VERSION ""

NS_ :

BS_:

BU_:
	NEO
	MCU
	GTW
	EPAS
	DI
	ESP
	SBW
	STW
	APP
	DAS
	iBooster
	IVS
	XXX

VAL_TABLE_ StW_AnglHP_Spd 16383 "SNA" ;
VAL_TABLE_ DI_aebFaultReason 15 "DI_AEB_FAULT_DAS_REQ_DI_UNAVAIL" 14 "DI_AEB_FAULT_ACCEL_REQ_INVALID" 13 "DI_AEB_FAULT_MIN_TIME_BTWN_EVENTS" 12 "DI_AEB_FAULT_ESP_MIA" 11 "DI_AEB_FAULT_ESP_FAULT" 10 "DI_AEB_FAULT_EPB_NOT_PARKED" 9 "DI_AEB_FAULT_ACCEL_OUT_OF_BOUNDS" 8 "DI_AEB_FAULT_PM_REQUEST" 7 "DI_AEB_FAULT_VEL_EST_ABNORMAL" 6 "DI_AEB_FAULT_DAS_SNA" 5 "DI_AEB_FAULT_DAS_CONTROL_MIA" 4 "DI_AEB_FAULT_SPEED_DELTA" 3 "DI_AEB_FAULT_EBR_FAULT" 2 "DI_AEB_FAULT_PM_MIA" 1 "DI_AEB_FAULT_EPB_MIA" 0 "DI_AEB_FAULT_NONE" ;
VAL_TABLE_ DI_aebLockState 3 "AEB_LOCK_STATE_SNA" 2 "AEB_LOCK_STATE_UNUSED" 1 "AEB_LOCK_STATE_UNLOCKED" 0 "AEB_LOCK_STATE_LOCKED" ;
VAL_TABLE_ DI_aebSmState 7 "DI_AEB_STATE_FAULT" 6 "DI_AEB_STATE_EXIT" 5 "DI_AEB_STATE_STANDSTILL" 4 "DI_AEB_STATE_STOPPING" 3 "DI_AEB_STATE_ENABLE" 2 "DI_AEB_STATE_ENABLE_INIT" 1 "DI_AEB_STATE_STANDBY" 0 "DI_AEB_STATE_UNAVAILABLE" ;
VAL_TABLE_ DI_aebState 7 "AEB_CAN_STATE_SNA" 4 "AEB_CAN_STATE_FAULT" 3 "AEB_CAN_STATE_STANDSTILL" 2 "AEB_CAN_STATE_ENABLED" 1 "AEB_CAN_STATE_STANDBY" 0 "AEB_CAN_STATE_UNAVAILABLE" ;
VAL_TABLE_ DI_epbInterfaceReady 1 "EPB_INTERFACE_READY" 0 "EPB_INTERFACE_NOT_READY" ;
VAL_TABLE_ DI_gear 7 "DI_GEAR_SNA" 4 "DI_GEAR_D" 3 "DI_GEAR_N" 2 "DI_GEAR_R" 1 "DI_GEAR_P" 0 "DI_GEAR_INVALID" ;
VAL_TABLE_ DI_gpoReason 8 "DI_GPO_NUMREASONS" 7 "DI_GPO_CAPACITOR_OVERTEMP" 6 "DI_GPO_NOT_ENOUGH_12V" 5 "DI_GPO_NO_BATTERY_POWER" 4 "DI_GPO_AMBIENT_OVERTEMP" 3 "DI_GPO_FLUID_DELTAT" 2 "DI_GPO_STATOR_OVERTEMP" 1 "DI_GPO_HEATSINK_OVERTEMP" 0 "DI_GPO_OUTLET_OVERTEMP" ;
VAL_TABLE_ DI_immobilizerCondition 1 "DI_IMM_CONDITION_LEARNED" 0 "DI_IMM_CONDITION_VIRGIN_SNA" ;
VAL_TABLE_ DI_immobilizerState 7 "DI_IMM_STATE_FAULT" 6 "DI_IMM_STATE_FAULTRETRY" 5 "DI_IMM_STATE_RESET" 4 "DI_IMM_STATE_LEARN" 3 "DI_IMM_STATE_DISARMED" 2 "DI_IMM_STATE_AUTHENTICATING" 1 "DI_IMM_STATE_REQUEST" 0 "DI_IMM_STATE_INIT_SNA" ;
VAL_TABLE_ DI_limpReason 24 "DI_LIMP_NUMREASONS" 23 "DI_LIMP_CAPACITOR_OVERTEMP" 22 "DI_LIMP_GTW_MIA" 21 "DI_LIMP_TRQCMD_VALIDITY_UNKNOWN" 20 "DI_LIMP_DI_MIA" 19 "DI_LIMP_CONFIG_MISMATCH" 18 "DI_LIMP_HEATSINK_TEMP" 17 "DI_LIMP_PMREQUEST" 16 "DI_LIMP_PMHEARTBEAT" 15 "DI_LIMP_TRQ_CROSS_CHECK" 14 "DI_LIMP_EXTERNAL_COMMAND" 13 "DI_LIMP_WRONG_CS_CALIBRATION" 12 "DI_LIMP_STATOR_TEMP" 11 "DI_LIMP_DELTAT_TOO_NEGATIVE" 10 "DI_LIMP_DELTAT_TOO_POSITIVE" 9 "DI_LIMP_AMBIENT_TEMP" 8 "DI_LIMP_OUTLET_TEMP" 7 "DI_LIMP_LOW_FLOW" 6 "DI_LIMP_BMS_MIA" 5 "DI_LIMP_12V_SUPPLY_UNDERVOLTAGE" 4 "DI_LIMP_NO_FLUID" 3 "DI_LIMP_NO_FUNC_HEATSINK_SENSOR" 2 "DI_LIMP_NO_FUNC_STATORT_SENSOR" 1 "DI_LIMP_BUSV_SENSOR_IRRATIONAL" 0 "DI_LIMP_PHASE_IMBALANCE" ;
VAL_TABLE_ DI_mode 2 "DI_MODE_DYNO" 1 "DI_MODE_DRIVE" 0 "DI_MODE_UNDEF" ;
VAL_TABLE_ DI_motorType 14 "DI_MOTOR_F2AE" 13 "DI_MOTOR_F2AD" 12 "DI_MOTOR_F2AC" 11 "DI_MOTOR_F2AB" 10 "DI_MOTOR_F1AC" 9 "DI_MOTOR_SSR1A" 8 "DI_MOTOR_F1A" 7 "DI_MOTOR_M7M6" 6 "DI_MOTOR_M8A" 5 "DI_MOTOR_M7M5" 4 "DI_MOTOR_M7M4" 3 "DI_MOTOR_M7M3" 2 "DI_MOTOR_ROADSTER_SPORT" 1 "DI_MOTOR_ROADSTER_BASE" 0 "DI_MOTOR_SNA" ;
VAL_TABLE_ DI_speedUnits 1 "DI_SPEED_KPH" 0 "DI_SPEED_MPH" ;
VAL_TABLE_ DI_state 4 "DI_STATE_ENABLE" 3 "DI_STATE_FAULT" 2 "DI_STATE_CLEAR_FAULT" 1 "DI_STATE_STANDBY" 0 "DI_STATE_PREAUTH" ;
VAL_TABLE_ DI_velocityEstimatorState 4 "VE_STATE_BACKUP_MOTOR" 3 "VE_STATE_BACKUP_WHEELS_B" 2 "VE_STATE_BACKUP_WHEELS_A" 1 "VE_STATE_WHEELS_NORMAL" 0 "VE_STATE_NOT_INITIALIZED" ;
VAL_TABLE_ DAS_DepartureWarning 3 "SNA" 2 "RIGHT_WARNING" 1 "LEFT_WARNING" 0 "NONE" ;
VAL_TABLE_ DAS_LaneDepartureWarningStatus 3 "DEGRADED" 2 "FAILED" 1 "INACTIVE" 0 "ACTIVE" ;
VAL_TABLE_ DAS_LaneTypeColor 15 "SNA" 14 "INVALID_YELLOW" 13 "BOTTS_DOTS_YELLOW" 12 "DOUBLE_LANE_YELLOW" 11 "ROAD_EDGE_YELLOW" 10 "UNDECIDED_YELLOW" 9 "SOLID_YELLOW" 8 "DASHED_YELLOW" 6 "INVALID" 5 "BOTTS_DOTS" 4 "DOUBLE_LANE" 3 "ROAD_EDGE" 2 "UNDECIDED" 1 "SOLID" 0 "DASHED" ;
VAL_TABLE_ DAS_NM_keepAwakeReason 2 "DAS_KEEPAWAKE_REASON_TELEMETRY" 1 "DAS_KEEPAWAKE_REASON_PRECONDITIONING" 0 "DAS_KEEPAWAKE_REASON_NONE_SNA" ;
VAL_TABLE_ DAS_SignType 255 "E_INVALID_SIGN" 254 "NO_SIGN_DETECTED" 221 "STANDARD_ELECTR_END_OF_NO_PASSING" 220 "STANDARD_ELECTR_NO_PASSING_START" 201 "REGULAR_END_OF_NO_PASSING" 200 "REGULAR_NO_PASSING_START" 176 "REGULAR_END_OF_PLAYGROUND_AREA" 175 "REGULAR_PLAYGROUND_AREA_BEGIN" 174 "STANDARD_REGULAR_END_OF_EXPRESSWAY" 173 "STANDARD_REGULAR_EXPRESSWAY_BEGIN" 172 "STANDARD_REGULAR_END_OF_MOTORWAY" 171 "STANDARD_REGULAR_MOTORWAY_BEGIN" 129 "STANDARD_ELECTRONIC_145" 128 "STANDARD_ELECTRONIC_135" 127 "STANDARD_ELECTRONIC_125" 126 "STANDARD_ELECTRONIC_115" 125 "STANDARD_ELECTRONIC_105" 124 "STANDARD_ELECTRONIC_95" 123 "STANDARD_ELECTRONIC_85" 122 "STANDARD_ELECTRONIC_75" 121 "STANDARD_ELECTRONIC_65" 120 "STANDARD_ELECTRONIC_55" 119 "STANDARD_ELECTRONIC_45" 118 "STANDARD_ELECTRONIC_35" 117 "STANDARD_ELECTRONIC_25" 116 "STANDARD_ELECTRONIC_15" 115 "STANDARD_ELECTRONIC_5" 114 "STANDARD_REGULAR_145" 113 "STANDARD_REGULAR_135" 112 "STANDARD_REGULAR_125" 111 "STANDARD_REGULAR_115" 110 "STANDARD_REGULAR_105" 109 "STANDARD_REGULAR_95" 108 "STANDARD_REGULAR_85" 107 "STANDARD_REGULAR_75" 106 "STANDARD_REGULAR_65" 105 "STANDARD_REGULAR_55" 104 "STANDARD_REGULAR_45" 103 "STANDARD_REGULAR_35" 102 "STANDARD_REGULAR_25" 101 "STANDARD_REGULAR_15" 100 "STANDARD_REGULAR_5" 65 "ELECTRIC_GEN_END_ALL_RESTRICTION" 64 "REGULAR_GEN_END_ALL_RESTRICT" 50 "ELECTRONIC_END_OF_NUM_RESTRICT" 41 "STANDARD_ELECTRONIC_140" 40 "STANDARD_ELECTRONIC_130" 39 "STANDARD_ELECTRONIC_120" 38 "STANDARD_ELECTRONIC_110" 37 "STANDARD_ELECTRONIC_100" 36 "STANDARD_ELECTRONIC_90" 35 "STANDARD_ELECTRONIC_80" 34 "STANDARD_ELECTRONIC_70" 33 "STANDARD_ELECTRONIC_60" 32 "STANDARD_ELECTRONIC_50" 31 "STANDARD_ELECTRONIC_40" 30 "STANDARD_ELECTRONIC_30" 29 "STANDARD_ELECTRONIC_20" 28 "STANDARD_ELECTRONIC_10" 20 "STANDARD_END_OF_NUM_RESTRICTION" 13 "STANDARD_REGULAR_140" 12 "STANDARD_REGULAR_130" 11 "STANDARD_REGULAR_120" 10 "STANDARD_REGULAR_110" 9 "STANDARD_REGULAR_100" 8 "STANDARD_REGULAR_90" 7 "STANDARD_REGULAR_80" 6 "STANDARD_REGULAR_70" 5 "STANDARD_REGULAR_60" 4 "STANDARD_REGULAR_50" 3 "STANDARD_REGULAR_40" 2 "STANDARD_REGULAR_30" 1 "STANDARD_REGULAR_20" 0 "STANDARD_REGULAR_10" ;
VAL_TABLE_ DAS_SteeringAngleRequest 16384 "ZERO_ANGLE" ;
VAL_TABLE_ DAS_aebEvent 3 "AEB_SNA" 2 "AEB_FAULT" 1 "AEB_ACTIVE" 0 "AEB_NOT_ACTIVE" ;
VAL_TABLE_ DAS_csa_internal_state 4 "CSA_INTERNAL_STATE_ENABLE_HOLD" 3 "CSA_INTERNAL_STATE_ENABLE_ACCELEROMETER" 2 "CSA_INTERNAL_STATE_ENABLE_PREDICTED" 1 "CSA_INTERNAL_STATE_AVAILABLE" 0 "CSA_INTERNAL_STATE_UNAVAILABLE" ;
VAL_TABLE_ DAS_eyeqAlert 3 "a003_eyeq_watchdog_reset" 2 "a002_eyeq_communication_timeout" 1 "a001_eyeq_boot_failure" ;
VAL_TABLE_ DAS_hazardLightRequest 3 "DAS_REQUEST_HAZARDS_SNA" 2 "DAS_REQUEST_HAZARDS_UNUSED" 1 "DAS_REQUEST_HAZARDS_ON" 0 "DAS_REQUEST_HAZARDS_OFF" ;
VAL_TABLE_ DAS_headlightRequest 3 "DAS_HEADLIGHT_REQUEST_INVALID" 1 "DAS_HEADLIGHT_REQUEST_ON" 0 "DAS_HEADLIGHT_REQUEST_OFF" ;
VAL_TABLE_ DAS_highLowBeamDecision 3 "DAS_HIGH_BEAM_SNA" 2 "DAS_HIGH_BEAM_ON" 1 "DAS_HIGH_BEAM_OFF" 0 "DAS_HIGH_BEAM_UNDECIDED" ;
VAL_TABLE_ DAS_highLowBeamOffReason 5 "HIGH_BEAM_OFF_REASON_SNA" 4 "HIGH_BEAM_OFF_REASON_HEAD_LIGHT" 3 "HIGH_BEAM_OFF_REASON_AMBIENT_LIGHT" 2 "HIGH_BEAM_OFF_REASON_MOVING_RADAR_TARGET" 1 "HIGH_BEAM_OFF_REASON_MOVING_VISION_TARGET" 0 "HIGH_BEAM_ON" ;
VAL_TABLE_ DAS_infoIndex 255 "DAS_INFO_END" 24 "DAS_INFO_EYEQ_FFS" 23 "DAS_INFO_EYEQ_APP" 20 "DAS_INFO_UDS_PROTOCOL_BOOTCRC" 19 "DAS_INFO_VERSION_DEPRECATED" 18 "DAS_INFO_BOOTLOADER_GITHASH" 17 "DAS_INFO_APP_GITHASH" 16 "DAS_INFO_EYEQ_BOOT" 15 "DAS_INFO_BOOTLOADER_CRC" 14 "DAS_INFO_BOOTLOADER_SVN" 13 "DAS_INFO_APP_CRC" 11 "DAS_INFO_PCBAID_ASSYID_USAGEID" 10 "DAS_INFO_BUILD_HWID_COMPONENTID" 9 "DAS_INFO_DEPRECATED_9" 8 "DAS_INFO_DEPRECATED_8" 7 "DAS_INFO_DEPRECATED_7" 6 "DAS_INFO_DEPRECATED_6" 5 "DAS_INFO_DEPRECATED_5" 4 "DAS_INFO_DEPRECATED_4" 3 "DAS_INFO_DEPRECATED_3" 2 "DAS_INFO_DEPRECATED_2" 1 "DAS_INFO_DEPRECATED_1" 0 "DAS_INFO_DEPRECATED_0" ;
VAL_TABLE_ DAS_locMode 3 "DAS_LOC_DRIVERLESS" 2 "DAS_LOC_RESTRICTED" 1 "DAS_LOC_NORMAL" 0 "DAS_LOC_OFF" ;
VAL_TABLE_ DAS_locRequest 4 "DAS_RQ_PARK" 3 "DAS_RQ_HOLD" 2 "DAS_RQ_BACKWARD" 1 "DAS_RQ_FORWARD" 0 "DAS_RQ_IDLE" ;
VAL_TABLE_ DAS_locState 7 "DAS_LOC_FAULT_SNA" 6 "DAS_LOC_AEB_ACTIVE" 2 "DAS_LOC_CANCEL_SILENT" 1 "DAS_LOC_CANCEL_GENERIC" 0 "DAS_LOC_HEALTHY" ;
VAL_TABLE_ DAS_steeringLKAOperatingStatus 3 "Not_available" 2 "Not_used" 1 "Operating" 0 "Inhibited" ;
VAL_TABLE_ DAS_sw019_020_taskID 5 "TASKS_VEHICLE" 4 "TASKS_MOBILEYE" 3 "TASKS_UDS" 2 "TASKS_CAN" 1 "TASKS_INIT" 0 "TASKS_RESERVED" ;
VAL_TABLE_ DAS_sw021_tempSensorId 4 "DDR_TEMP_SENSOR" 3 "CAMERA_TEMP_SENSOR" 2 "EYE_Q_TEMP_SENSOR_1" 1 "EYE_Q_TEMP_SENSOR_0" 0 "EXTERNAL_TEMP_SENSOR" ;
VAL_TABLE_ DAS_sw022_operation 4 "Erase All" 3 "Delete" 2 "Read" 1 "Write" 0 "Initialize" ;
VAL_TABLE_ DAS_sw024_heaterState 2 "SHORT" 1 "OPEN" 0 "NORMAL" ;
VAL_TABLE_ DAS_sw037_issue 1 "Invalid parameters" 0 "Failed to read" ;
VAL_TABLE_ DAS_sw043_mesp_health_main_state 172 "EYEQ_MESP_MAIN_STATE_TAC2" 170 "EYEQ_MESP_MAIN_STATE_DV" 146 "EYEQ_MESP_MAIN_STATE_VISION_INIT_PENDING" 133 "EYEQ_MESP_MAIN_STATE_TAC2_INIT_PENDING" 130 "EYEQ_MESP_MAIN_STATE_SPC_INIT_PENDING" 129 "EYEQ_MESP_MAIN_STATE_SPTAC_INIT_PENDING" 34 "EYEQ_MESP_MAIN_STATE_SPC" 33 "EYEQ_MESP_MAIN_STATE_SPTAC" 2 "EYEQ_MESP_MAIN_STATE_VISION" ;
VAL_TABLE_ DAS_sw043_mobileye_status 24 "MOBILEYE_STATUS_UNDEFINED" 23 "MOBILEYE_STATUS_TEARDOWN_FLASH_ACCESS_MODE" 22 "MOBILEYE_STATUS_FLASH_READ_MODE" 21 "MOBILEYE_STATUS_SETUP_FLASH_ACCESS_MODE" 20 "MOBILEYE_STATUS_RUNNING_SPTAC_MODE" 19 "MOBILEYE_STATUS_SPTAC_INIT_SENT" 18 "MOBILEYE_STATUS_WAITING_FOR_SPTAC_INIT" 17 "MOBILEYE_STATUS_BURN_EDR_MODE" 16 "MOBILEYE_STATUS_SPC_INIT_SENT" 15 "MOBILEYE_STATUS_WAITING_FOR_SPC_INIT" 14 "MOBILEYE_STATUS_ERROR" 13 "MOBILEYE_STATUS_LATCHING_FAILURE" 12 "MOBILEYE_STATUS_UPDATING" 11 "MOBILEYE_STATUS_RUNNING_DV_MODE" 10 "MOBILEYE_STATUS_WAITING_FOR_DV" 9 "MOBILEYE_STATUS_RUNNING_TAC_MODE" 8 "MOBILEYE_STATUS_RUNNING_SPC_MODE" 7 "MOBILEYE_STATUS_RUNNING_VISION_MODE" 6 "MOBILEYE_STATUS_TAC_INIT_SENT" 5 "MOBILEYE_STATUS_WAITING_FOR_TAC_INIT" 4 "MOBILEYE_STATUS_VISION_INIT_SENT" 3 "MOBILEYE_STATUS_WAITING_FOR_VISION_INIT" 2 "MOBILEYE_STATUS_WAITING_FOR_BOOT" 1 "MOBILEYE_STATUS_POWER_OFF" 0 "MOBILEYE_STATUS_POWER_CYCLE" ;
VAL_TABLE_ DAS_turnIndicatorRequest 3 "DAS_TURN_INDICATOR_CANCEL" 2 "DAS_TURN_INDICATOR_RIGHT" 1 "DAS_TURN_INDICATOR_LEFT" 0 "DAS_TURN_INDICATOR_NONE" ;
VAL_TABLE_ DAS_turnIndicatorRequestReason 6 "DAS_ACTIVE_COMMANDED_LANE_CHANGE" 5 "DAS_CANCEL_FORK" 4 "DAS_CANCEL_LANE_CHANGE" 3 "DAS_ACTIVE_FORK" 2 "DAS_ACTIVE_SPEED_LANE_CHANGE" 1 "DAS_ACTIVE_NAV_LANE_CHANGE" 0 "DAS_NONE" ;
VAL_TABLE_ DAS_wiperSpeed 15 "DAS_WIPER_SPEED_INVALID" 14 "DAS_WIPER_SPEED_14" 13 "DAS_WIPER_SPEED_13" 12 "DAS_WIPER_SPEED_12" 11 "DAS_WIPER_SPEED_11" 10 "DAS_WIPER_SPEED_10" 9 "DAS_WIPER_SPEED_9" 8 "DAS_WIPER_SPEED_8" 7 "DAS_WIPER_SPEED_7" 6 "DAS_WIPER_SPEED_6" 5 "DAS_WIPER_SPEED_5" 4 "DAS_WIPER_SPEED_4" 3 "DAS_WIPER_SPEED_3" 2 "DAS_WIPER_SPEED_2" 1 "DAS_WIPER_SPEED_1" 0 "DAS_WIPER_SPEED_OFF" ;

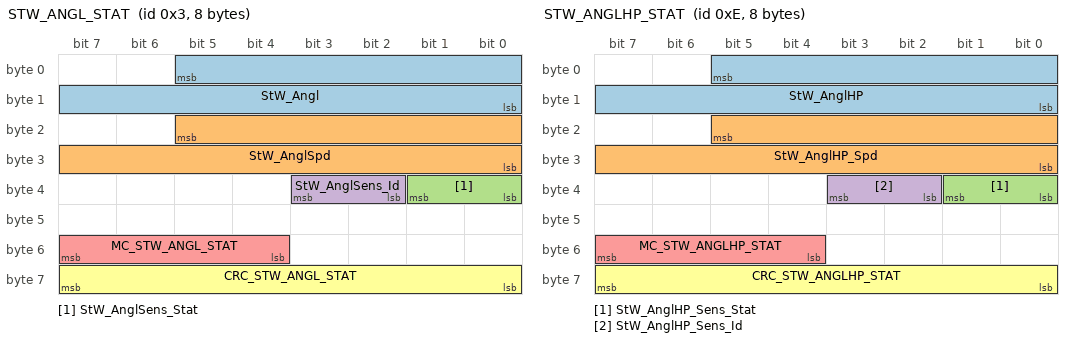
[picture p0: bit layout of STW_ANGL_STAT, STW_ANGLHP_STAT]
BO_ 3 STW_ANGL_STAT: 8 STW
 SG_ StW_Angl : 5|14@0+ (0.5,-2048) [0|0] "deg"  NEO
 SG_ StW_AnglSpd : 21|14@0+ (0.5,-2048) [0|0] "/s"  NEO
 SG_ StW_AnglSens_Stat : 33|2@0+ (1,0) [-1|4] ""  NEO
 SG_ StW_AnglSens_Id : 35|2@0+ (1,0) [3|3] ""  NEO
 SG_ MC_STW_ANGL_STAT : 55|4@0+ (1,0) [0|15] ""  NEO
 SG_ CRC_STW_ANGL_STAT : 63|8@0+ (1,0) [0|255] ""  NEO

BO_ 14 STW_ANGLHP_STAT: 8 STW
 SG_ StW_AnglHP : 5|14@0+ (0.1,-819.2) [-819.2|819] "deg"  NEO
 SG_ StW_AnglHP_Spd : 21|14@0+ (0.5,-4096) [-4096|4095.5] "deg/s"  NEO
 SG_ StW_AnglHP_Sens_Stat : 33|2@0+ (1,0) [0|0] ""  NEO
 SG_ StW_AnglHP_Sens_Id : 35|2@0+ (1,0) [0|0] ""  NEO
 SG_ MC_STW_ANGLHP_STAT : 55|4@0+ (1,0) [0|15] ""  NEO
 SG_ CRC_STW_ANGLHP_STAT : 63|8@0+ (1,0) [0|0] ""  NEO

BO_ 69 STW_ACTN_RQ: 8 XXX
 SG_ SpdCtrlLvr_Stat : 0|6@1+ (1,0) [0|0] "" XXX
 SG_ VSL_Enbl_Rq : 6|1@1+ (1,0) [0|0] "" XXX
 SG_ SpdCtrlLvrStat_Inv : 7|1@1+ (1,0) [0|0] "" XXX
 SG_ DTR_Dist_Rq : 8|8@1+ (1,0) [0|200] "" XXX
 SG_ TurnIndLvr_Stat : 16|2@1+ (1,0) [0|0] "" XXX
 SG_ HiBmLvr_Stat : 18|2@1+ (1,0) [0|0] "" XXX
 SG_ WprWashSw_Psd : 20|2@1+ (1,0) [0|0] "" XXX
 SG_ WprWash_R_Sw_Posn_V2 : 22|2@1+ (1,0) [0|0] "" XXX
 SG_ StW_Lvr_Stat : 24|3@1+ (1,0) [0|0] "" XXX
 SG_ StW_Cond_Flt : 27|1@1+ (1,0) [0|0] "" XXX
 SG_ StW_Cond_Psd : 28|2@1+ (1,0) [0|0] "" XXX
 SG_ HrnSw_Psd : 30|2@1+ (1,0) [0|0] "" XXX
 SG_ StW_Sw00_Psd : 32|1@1+ (1,0) [0|0] "" XXX
 SG_ StW_Sw01_Psd : 33|1@1+ (1,0) [0|0] "" XXX
 SG_ StW_Sw02_Psd : 34|1@1+ (1,0) [0|0] "" XXX
 SG_ StW_Sw03_Psd : 35|1@1+ (1,0) [0|0] "" XXX
 SG_ StW_Sw04_Psd : 36|1@1+ (1,0) [0|0] "" XXX
 SG_ StW_Sw05_Psd : 37|1@1+ (1,0) [0|0] "" XXX
 SG_ StW_Sw06_Psd : 38|1@1+ (1,0) [0|0] "" XXX
 SG_ StW_Sw07_Psd : 39|1@1+ (1,0) [0|0] "" XXX
 SG_ StW_Sw08_Psd : 40|1@1+ (1,0) [0|0] "" XXX
 SG_ StW_Sw09_Psd : 41|1@1+ (1,0) [0|0] "" XXX
 SG_ StW_Sw10_Psd : 42|1@1+ (1,0) [0|0] "" XXX
 SG_ StW_Sw11_Psd : 43|1@1+ (1,0) [0|0] "" XXX
 SG_ StW_Sw12_Psd : 44|1@1+ (1,0) [0|0] "" XXX
 SG_ StW_Sw13_Psd : 45|1@1+ (1,0) [0|0] "" XXX
 SG_ StW_Sw14_Psd : 46|1@1+ (1,0) [0|0] "" XXX
 SG_ StW_Sw15_Psd : 47|1@1+ (1,0) [0|0] "" XXX
 SG_ WprSw6Posn : 48|3@1+ (1,0) [0|0] "" XXX
 SG_ MC_STW_ACTN_RQ : 52|4@1+ (1,0) [0|15] "" XXX
 SG_ CRC_STW_ACTN_RQ : 56|8@1+ (1,0) [0|0] "" XXX

BO_ 104 MCU_locationStatus2: 8 XXX
 SG_ MCU_elevation : 0|32@1- (0.1,0) [0|0] "m" XXX
 SG_ MCU_navigonExpectedSpeed : 32|7@1+ (1,0) [0|126] "mph" XXX

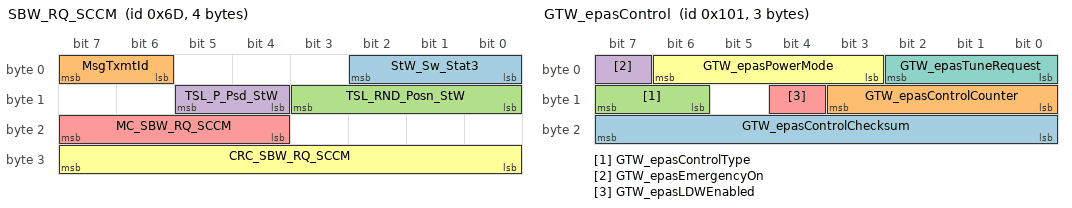
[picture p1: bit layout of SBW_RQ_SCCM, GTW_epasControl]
BO_ 109 SBW_RQ_SCCM: 4 XXX
 SG_ StW_Sw_Stat3 : 0|3@1+ (1,0) [0|0] "" XXX
 SG_ MsgTxmtId : 6|2@1+ (1,0) [0|0] "" XXX
 SG_ TSL_RND_Posn_StW : 8|4@1+ (1,0) [0|0] "" XXX
 SG_ TSL_P_Psd_StW : 12|2@1+ (1,0) [0|0] "" XXX
 SG_ MC_SBW_RQ_SCCM : 20|4@1+ (1,0) [0|15] "" XXX
 SG_ CRC_SBW_RQ_SCCM : 24|8@1+ (1,0) [0|0] "" XXX

BO_ 257 GTW_epasControl: 3 NEO
 SG_ GTW_epasControlChecksum : 23|8@0+ (1,0) [0|255] ""  NEO
 SG_ GTW_epasControlCounter : 11|4@0+ (1,0) [0|15] ""  NEO
 SG_ GTW_epasControlType : 15|2@0+ (1,0) [-1|4] ""  NEO
 SG_ GTW_epasEmergencyOn : 7|1@0+ (1,0) [-1|2] ""  NEO
 SG_ GTW_epasLDWEnabled : 12|1@0+ (1,0) [-1|2] ""  NEO
 SG_ GTW_epasPowerMode : 6|4@0+ (1,0) [4|14] ""  NEO
 SG_ GTW_epasTuneRequest : 2|3@0+ (1,0) [-1|8] ""  NEO

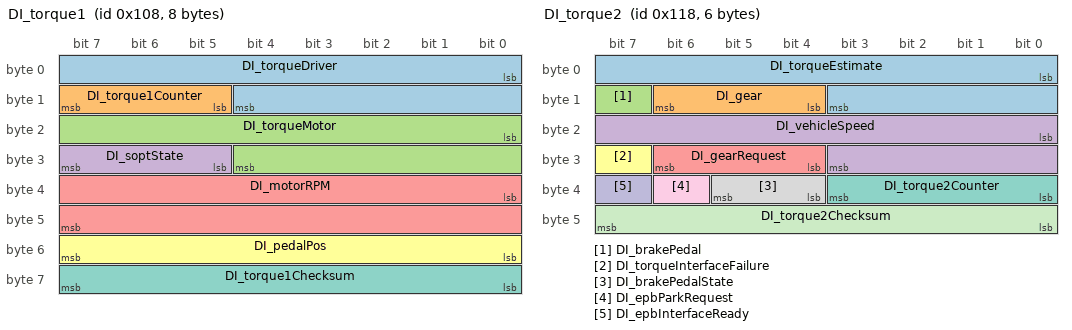
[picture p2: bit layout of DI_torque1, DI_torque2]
BO_ 264 DI_torque1: 8 DI
 SG_ DI_torqueDriver : 0|13@1- (0.25,0) [-750|750] "Nm"  NEO
 SG_ DI_torque1Counter : 13|3@1+ (1,0) [0|0] ""  NEO
 SG_ DI_torqueMotor : 16|13@1- (0.25,0) [-750|750] "Nm"  NEO
 SG_ DI_soptState : 29|3@1+ (1,0) [0|0] ""  NEO
 SG_ DI_motorRPM : 32|16@1- (1,0) [-17000|17000] "RPM"  NEO
 SG_ DI_pedalPos : 48|8@1+ (0.4,0) [0|100] "%"  NEO
 SG_ DI_torque1Checksum : 56|8@1+ (1,0) [0|0] ""  NEO

BO_ 280 DI_torque2: 6 DI
 SG_ DI_torqueEstimate : 0|12@1- (0.5,0) [-750|750] "Nm" NEO
 SG_ DI_gear : 12|3@1+ (1,0) [0|0] "" NEO
 SG_ DI_brakePedal : 15|1@1+ (1,0) [0|0] "" NEO
 SG_ DI_vehicleSpeed : 16|12@1+ (0.05,-25) [-25|179.75] "MPH" NEO
 SG_ DI_gearRequest : 28|3@1+ (1,0) [0|0] "" NEO
 SG_ DI_torqueInterfaceFailure : 31|1@1+ (1,0) [0|0] "" NEO
 SG_ DI_torque2Counter : 32|4@1+ (1,0) [0|0] "" NEO
 SG_ DI_brakePedalState : 36|2@1+ (1,0) [0|0] "" NEO
 SG_ DI_epbParkRequest : 38|1@1+ (1,0) [0|0] "" NEO
 SG_ DI_epbInterfaceReady : 39|1@1+ (1,0) [0|0] "" NEO
 SG_ DI_torque2Checksum : 40|8@1+ (1,0) [0|0] "" NEO

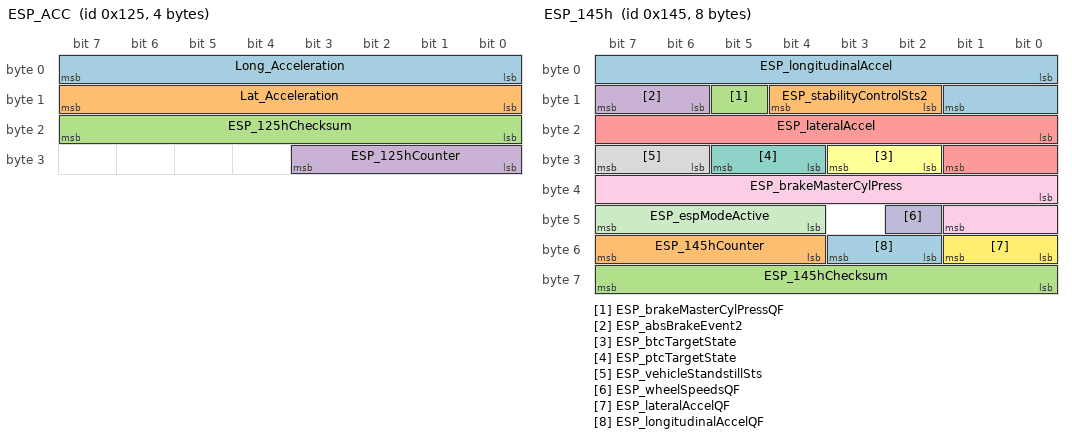
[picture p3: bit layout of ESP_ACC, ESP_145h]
BO_ 293 ESP_ACC: 4 ESP
 SG_ Long_Acceleration : 0|8@1- (0.08,0) [-10.24|10] "m/s^2" NEO
 SG_ Lat_Acceleration : 8|8@1- (0.08,0) [-10.24|10] "m/s^2" NEO
 SG_ ESP_125hChecksum : 16|8@1+ (1,0) [0|0] "" NEO
 SG_ ESP_125hCounter : 24|4@1+ (1,0) [0|0] "" NEO

BO_ 309 ESP_135h: 5 ESP
 SG_ ESP_135hChecksum : 23|8@0+ (1,0) [0|255] ""  NEO
 SG_ ESP_135hCounter : 11|4@0+ (1,0) [0|15] ""  NEO
 SG_ ESP_absBrakeEvent : 2|1@0+ (1,0) [-1|2] ""  NEO
 SG_ ESP_brakeDiscWipingActive : 4|1@0+ (1,0) [-1|2] ""  NEO
 SG_ ESP_brakeLamp : 3|1@0+ (1,0) [-1|2] ""  NEO
 SG_ ESP_espFaultLamp : 6|1@0+ (1,0) [-1|2] ""  NEO
 SG_ ESP_espLampFlash : 7|1@0+ (1,0) [-1|2] ""  NEO
 SG_ ESP_hillStartAssistActive : 1|2@0+ (1,0) [-1|4] ""  NEO
 SG_ ESP_messagePumpService : 24|1@0+ (1,0) [0|1] ""  NEO
 SG_ ESP_messagePumpFailure : 25|1@0+ (1,0) [0|1] ""  NEO
 SG_ ESP_messageEBDFailure : 26|1@0+ (1,0) [0|1] ""  NEO
 SG_ ESP_absFaultLamp : 27|1@0+ (1,0) [-1|2] ""  NEO
 SG_ ESP_tcDisabledByFault : 28|1@0+ (1,0) [0|1] ""  NEO
 SG_ ESP_messageDynoModeActive : 29|1@0+ (1,0) [0|1] ""  NEO
 SG_ ESP_hydraulicBoostEnabled : 30|1@0+ (1,0) [0|1] ""  NEO
 SG_ ESP_espOffLamp : 31|1@0+ (1,0) [-1|2] ""  NEO
 SG_ ESP_stabilityControlSts : 14|3@0+ (1,0) [6|7] ""  NEO
 SG_ ESP_tcLampFlash : 5|1@0+ (1,0) [-1|2] ""  NEO
 SG_ ESP_tcOffLamp : 15|1@0+ (1,0) [0|1] ""  NEO

BO_ 325 ESP_145h: 8 ESP
 SG_ ESP_longitudinalAccel : 0|10@1+ (0.05,-25.6) [-25.6|25.55] "m/s^2" NEO
 SG_ ESP_stabilityControlSts2 : 10|3@1+ (1,0) [0|0] "" NEO
 SG_ ESP_brakeMasterCylPressQF : 13|1@1+ (1,0) [0|1] "" NEO
 SG_ ESP_absBrakeEvent2 : 14|2@1+ (1,0) [0|0] "" NEO
 SG_ ESP_lateralAccel : 16|10@1+ (0.05,-25.6) [-25.6|25.55] "m/s^2" NEO
 SG_ ESP_btcTargetState : 26|2@1+ (1,0) [0|0] "" NEO
 SG_ ESP_ptcTargetState : 28|2@1+ (1,0) [0|0] "" NEO
 SG_ ESP_vehicleStandstillSts : 30|2@1+ (1,0) [0|0] "" NEO
 SG_ ESP_brakeMasterCylPress : 32|10@1+ (0.25,-42.5) [-42.5|213.25] "bar" NEO
 SG_ ESP_wheelSpeedsQF : 42|1@1+ (1,0) [0|1] "" NEO
 SG_ ESP_espModeActive : 44|4@1+ (1,0) [0|15] "" NEO
 SG_ ESP_lateralAccelQF : 48|2@1+ (1,0) [0|3] "" NEO
 SG_ ESP_longitudinalAccelQF : 50|2@1+ (1,0) [0|3] "" NEO
 SG_ ESP_145hCounter : 52|4@1+ (1,0) [0|0] "" NEO
 SG_ ESP_145hChecksum : 56|8@1+ (1,0) [0|0] "" NEO

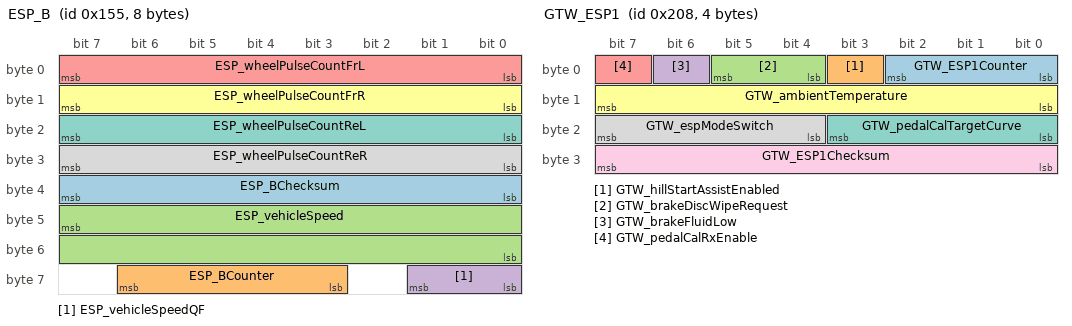
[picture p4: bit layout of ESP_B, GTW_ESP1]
BO_ 341 ESP_B: 8 ESP
 SG_ ESP_BChecksum : 39|8@0+ (1,0) [0|255] ""  NEO,EPAS
 SG_ ESP_BCounter : 62|4@0+ (1,0) [1|15] ""  NEO,EPAS
 SG_ ESP_vehicleSpeed : 47|16@0+ (0.01,0) [0|0] "kph"  NEO,EPAS
 SG_ ESP_vehicleSpeedQF : 57|2@0+ (1,0) [1|2] ""  NEO,EPAS
 SG_ ESP_wheelPulseCountFrL : 7|8@0+ (1,0) [0|254] ""  NEO,EPAS
 SG_ ESP_wheelPulseCountFrR : 15|8@0+ (1,0) [0|254] ""  NEO,EPAS
 SG_ ESP_wheelPulseCountReL : 23|8@0+ (1,0) [0|254] ""  NEO,EPAS
 SG_ ESP_wheelPulseCountReR : 31|8@0+ (1,0) [0|254] ""  NEO,EPAS

BO_ 513 SDM1: 5 GTW
 SG_ SDM_bcklPassStatus : 3|2@0+ (1,0) [0|3] "" NEO
 SG_ SDM_bcklDrivStatus : 5|2@0+ (1,0) [0|3] "" NEO

BO_ 520 GTW_ESP1: 4 NEO
 SG_ GTW_ESP1Counter : 0|3@1+ (1,0) [0|1] "" NEO,ESP
 SG_ GTW_hillStartAssistEnabled : 3|1@1+ (1,0) [0|0] "" NEO,ESP
 SG_ GTW_brakeDiscWipeRequest : 4|2@1+ (1,0) [0|0] "" NEO,ESP
 SG_ GTW_brakeFluidLow : 6|1@1+ (1,0) [0|0] "" NEO,ESP
 SG_ GTW_pedalCalRxEnable : 7|1@1+ (1,0) [0|1] "" NEO,ESP
 SG_ GTW_ambientTemperature : 8|8@1+ (0.5,-40) [-40|60] "dgr. Celsius" NEO,ESP
 SG_ GTW_pedalCalTargetCurve : 16|4@1+ (1,0) [0|15] "" NEO,ESP
 SG_ GTW_espModeSwitch : 20|4@1+ (1,0) [0|15] "" NEO,ESP
 SG_ GTW_ESP1Checksum : 24|8@1+ (1,0) [0|0] "" NEO,ESP

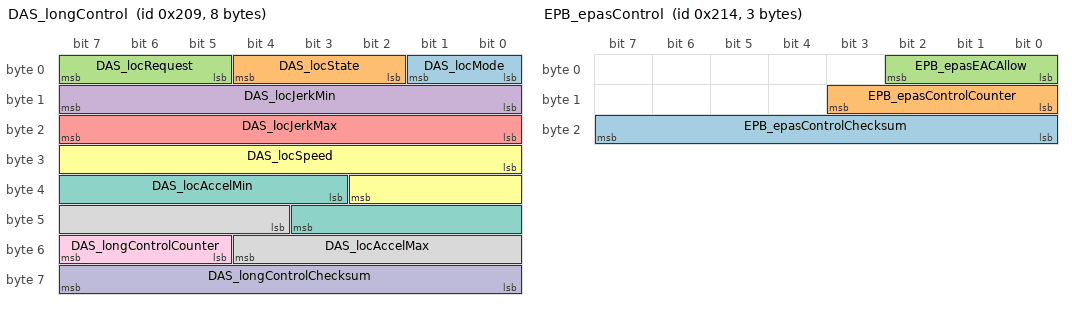
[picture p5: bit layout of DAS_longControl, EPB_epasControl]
BO_ 521 DAS_longControl: 8 XXX
 SG_ DAS_locMode : 0|2@1+ (1,0) [0|0] "" XXX
 SG_ DAS_locState : 2|3@1+ (1,0) [0|0] "" XXX
 SG_ DAS_locRequest : 5|3@1+ (1,0) [0|0] "" XXX
 SG_ DAS_locJerkMin : 8|8@1+ (0.034,-8.67) [-8.67|0] "m/s^3" XXX
 SG_ DAS_locJerkMax : 16|8@1+ (0.034,0) [0|8.67] "m/s^3" XXX
 SG_ DAS_locSpeed : 24|11@1+ (0.1,0) [0|204.7] "kph" XXX
 SG_ DAS_locAccelMin : 35|9@1+ (0.04,-15) [-15|5.44] "m/s^2" XXX
 SG_ DAS_locAccelMax : 44|9@1+ (0.04,-15) [-15|5.44] "m/s^2" XXX
 SG_ DAS_longControlCounter : 53|3@1+ (1,0) [0|0] "" XXX
 SG_ DAS_longControlChecksum : 56|8@1+ (1,0) [0|0] "" XXX

BO_ 522 BrakeMessage: 8 XXX
 SG_ driverBrakeStatus : 2|2@1+ (1,0) [0|3] "" XXX

BO_ 529 RCM_status: 8 RCM
 SG_ RCM_driverOrientationInitStatus : 2|3@0+ (1,0) [0|7] "" GTW,OCS
 SG_ RCM_armStatus : 5|2@0+ (1,0) [0|3] "" GTW,OCS
 SG_ RCM_warningIndicatorState : 7|2@0+ (1,0) [0|3] "" GTW,OCS
 SG_ RCM_tellTalePassengerState : 9|2@0+ (1,0) [0|3] "" GTW,OCS,DAS
 SG_ RCM_bucklePassengerStatus : 11|2@0+ (1,0) [0|3] "" GTW,OCS
 SG_ RCM_tellTaleDriverState : 13|2@0+ (1,0) [0|3] "" GTW,OCS
 SG_ RCM_buckleDriverStatus : 15|2@0+ (1,0) [0|3] "" GTW,OCS,DAS
 SG_ RCM_seatTrackPositionDrvr : 19|2@0+ (1,0) [0|3] "" GTW,OCS
 SG_ RCM_passAirbagRequest : 21|2@0+ (1,0) [0|3] "" GTW,OCS
 SG_ RCM_chimeState1stRow : 23|2@0+ (1,0) [0|3] "" GTW,OCS
 SG_ RCM_vinLearnFlag : 25|2@0+ (1,0) [0|3] "" GTW,OCS
 SG_ RCM_hwConfigPin58 : 27|2@0+ (1,0) [0|3] "" GTW,OCS
 SG_ RCM_hwConfigPin57 : 29|2@0+ (1,0) [0|3] "" GTW,OCS
 SG_ RCM_hwConfigPin56 : 31|2@0+ (1,0) [0|3] "" GTW,OCS
 SG_ RCM_passOccupantStatus : 33|2@0+ (1,0) [0|3] "" GTW,OCS
 SG_ RCM_airbagCutoffSwStatus : 35|2@0+ (1,0) [0|3] "" GTW,OCS
 SG_ RCM_privateCANStatus : 37|2@0+ (1,0) [0|3] "" GTW,OCS
 SG_ RCM_publicCANStatus : 39|2@0+ (1,0) [0|3] "" GTW,OCS
 SG_ RCM_edr2State : 45|2@0+ (1,0) [0|3] "" GTW,OCS
 SG_ RCM_edr1State : 47|2@0+ (1,0) [0|3] "" GTW,OCS
 SG_ RCM_buckle2ndRowStatus : 50|3@0+ (1,0) [0|3] "" GTW,OCS,DAS
 SG_ RCM_statusCounter : 55|4@0+ (1,0) [0|15] "" GTW,OCS,DAS
 SG_ RCM_statusChecksum : 63|8@0+ (1,0) [0|255] "" GTW,OCS,DAS

BO_ 532 EPB_epasControl: 3 EPB
 SG_ EPB_epasControlChecksum : 23|8@0+ (1,0) [0|255] ""  XXX
 SG_ EPB_epasControlCounter : 11|4@0+ (1,0) [0|15] ""  XXX
 SG_ EPB_epasEACAllow : 2|3@0+ (1,0) [4|7] ""  XXX

BO_ 536 MCU_chassisControl: 8 XXX
 SG_ MCU_dasDebugEnable : 0|1@1+ (1,0) [0|0] "" XXX
 SG_ MCU_parkBrakeRequest : 1|2@1+ (1,0) [0|0] "" XXX
 SG_ MCU_trailerModeCH : 3|1@1+ (1,0) [0|0] "" XXX
 SG_ MCU_fcwSensitivity : 4|2@1+ (1,0) [0|0] "" XXX
 SG_ MCU_fcwEnable : 6|2@1+ (1,0) [0|0] "" XXX
 SG_ MCU_latControlEnable : 8|2@1+ (1,0) [0|0] "" XXX
 SG_ MCU_accOvertakeEnable : 10|2@1+ (1,0) [0|0] "" XXX
 SG_ MCU_ldwEnable : 12|2@1+ (1,0) [0|0] "" XXX
 SG_ MCU_aebEnable : 14|2@1+ (1,0) [0|0] "" XXX
 SG_ MCU_bsdEnable : 16|2@1+ (1,0) [0|0] "" XXX
 SG_ MCU_ahlbEnable : 18|2@1+ (1,0) [0|0] "" XXX
 SG_ MCU_parkSetting : 20|2@1+ (1,0) [0|0] "" XXX
 SG_ MCU_pedalSafetyEnable : 22|2@1+ (1,0) [0|0] "" XXX
 SG_ MCU_frontDefrostReq_das : 24|2@1+ (1,0) [0|0] "" XXX
 SG_ MCU_autoParkRequest : 26|4@1+ (1,0) [0|0] "" XXX
 SG_ MCU_redLightStopSignEnable : 30|2@1+ (1,0) [0|0] "" XXX
 SG_ MCU_enableCreepTorqueCH : 32|1@1+ (1,0) [0|0] "" XXX
 SG_ MCU_narrowGarages : 33|1@1+ (1,0) [0|0] "" XXX
 SG_ MCU_rebootAutopilot : 34|1@1+ (1,0) [0|0] "" XXX
 SG_ MCU_enableAutowipers : 35|1@1+ (1,0) [0|0] "" XXX
 SG_ MCU_overPaintedUSS : 38|2@1+ (1,0) [0|0] "" XXX
 SG_ MCU_selfParkTune : 40|4@1+ (1,0) [0|15] "" XXX
 SG_ MCU_towModeEnable : 44|2@1+ (1,0) [0|0] "" XXX
 SG_ MCU_zeroSpeedConfirmed : 46|2@1+ (1,0) [0|0] "" XXX
 SG_ MCU_aesEnable : 48|2@1+ (1,0) [0|0] "" XXX
 SG_ MCU_autoLaneChangeEnable : 50|2@1+ (1,0) [0|0] "" XXX
 SG_ MCU_chassisControlCounter : 52|4@1+ (1,0) [0|0] "" XXX
 SG_ MCU_chassisControlChecksum : 56|8@1+ (1,0) [0|0] "" XXX

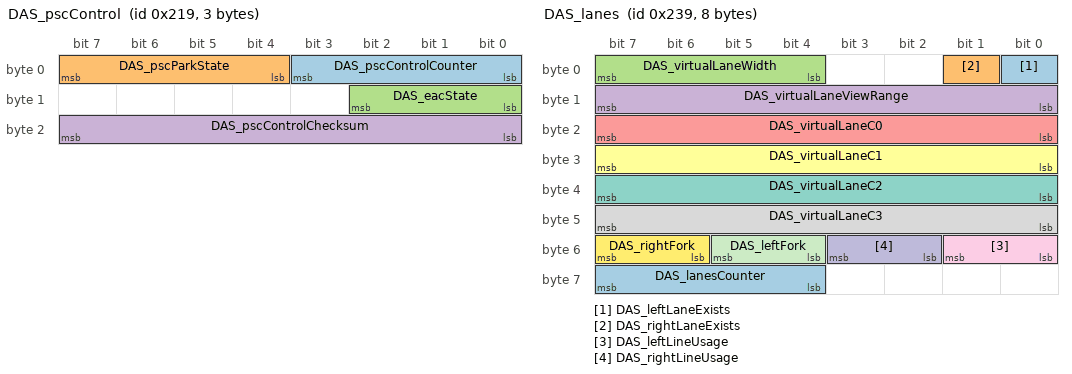
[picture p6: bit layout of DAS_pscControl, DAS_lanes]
BO_ 537 DAS_pscControl: 3 DAS
 SG_ DAS_pscControlCounter : 0|4@1+ (1,0) [0|15] "" PARK,APS
 SG_ DAS_pscParkState : 4|4@1+ (1,0) [0|15] "" PARK,EPB,APS
 SG_ DAS_eacState : 8|3@1+ (1,0) [0|3] "" PARK,APS
 SG_ DAS_pscControlChecksum : 16|8@1+ (1,0) [0|255] "" PARK,APS

BO_ 568 UI_driverAssistRoadSign: 8 XXX
 SG_ UI_roadSign M : 0|8@1+ (1,0) [0|0] "" XXX
 SG_ UI_splineLocConfidence : 40|7@1+ (1,0) [0|100] "" XXX
 SG_ UI_splineID : 48|4@1+ (1,0) [0|15] "" Vector__XXX
 SG_ UI_roadSignCounter : 52|4@1+ (1,0) [0|0] "" Vector__XXX
 SG_ UI_roadSignChecksum : 56|8@1+ (1,0) [0|0] "" Vector__XXX
 SG_ UI_dummyData m0 : 8|1@1+ (1,0) [0|0] "" Vector__XXX
 SG_ UI_stopSignStopLineDist m1 : 8|10@1+ (0.25,-8) [-8|247.5] "m" Vector__XXX
 SG_ UI_stopSignStopLineConf m1 : 18|7@1+ (1,0) [0|100] "" Vector__XXX
 SG_ UI_trafficLightStopLineDist m2 : 8|10@1+ (0.25,-8) [-8|247.5] "m" Vector__XXX
 SG_ UI_trafficLightStopLineConf m2 : 18|7@1+ (1,0) [0|100] "" Vector__XXX
 SG_ UI_baseMapSpeedLimitMPS m3 : 8|8@1+ (0.25,0) [0|63.75] "m/s" XXX
 SG_ UI_bottomQrtlFleetSpeedMPS m3 : 16|8@1+ (0.25,0) [0|63.75] "m/s" XXX
 SG_ UI_topQrtlFleetSpeedMPS m3 : 24|8@1+ (0.25,0) [0|63.75] "m/s" XXX
 SG_ UI_meanFleetSplineSpeedMPS m4 : 8|8@1+ (0.25,0) [0|63.75] "m/s" XXX
 SG_ UI_medianFleetSpeedMPS m4 : 16|8@1+ (0.25,0) [0|63.75] "m/s" XXX
 SG_ UI_meanFleetSplineAccelMPS2 m4 : 24|8@1+ (0.05,-6.35) [-6.35|6.4] "m/s^2" XXX
 SG_ UI_rampType m4 : 32|3@1+ (1,0) [0|7] "" XXX
 SG_ UI_currSplineIdFull m5 : 8|32@1+ (1,0) [0|1] "" XXX

BO_ 569 DAS_lanes: 8 XXX
 SG_ DAS_leftLaneExists : 0|1@1+ (1,0) [0|0] "" XXX
 SG_ DAS_rightLaneExists : 1|1@1+ (1,0) [0|0] "" XXX
 SG_ DAS_virtualLaneWidth : 4|4@1+ (0.3125,2) [2|7] "m" XXX
 SG_ DAS_virtualLaneViewRange : 8|8@1+ (1,0) [0|160] "m" XXX
 SG_ DAS_virtualLaneC0 : 16|8@1+ (0.035,-3.5) [-3.5|3.5] "m" XXX
 SG_ DAS_virtualLaneC1 : 24|8@1+ (0.0016,-0.2) [-0.2|0.2] "rad" XXX
 SG_ DAS_virtualLaneC2 : 32|8@1+ (2E-05,-0.0025) [-0.0025|0.0025] "m-1" XXX
 SG_ DAS_virtualLaneC3 : 40|8@1+ (2.4E-07,-3E-05) [-3E-05|3E-05] "m-2" XXX
 SG_ DAS_leftLineUsage : 48|2@1+ (1,0) [0|3] "" XXX
 SG_ DAS_rightLineUsage : 50|2@1+ (1,0) [0|3] "" XXX
 SG_ DAS_leftFork : 52|2@1+ (1,0) [0|3] "" XXX
 SG_ DAS_rightFork : 54|2@1+ (1,0) [0|3] "" XXX
 SG_ DAS_lanesCounter : 60|4@1+ (1,0) [0|0] "" XXX

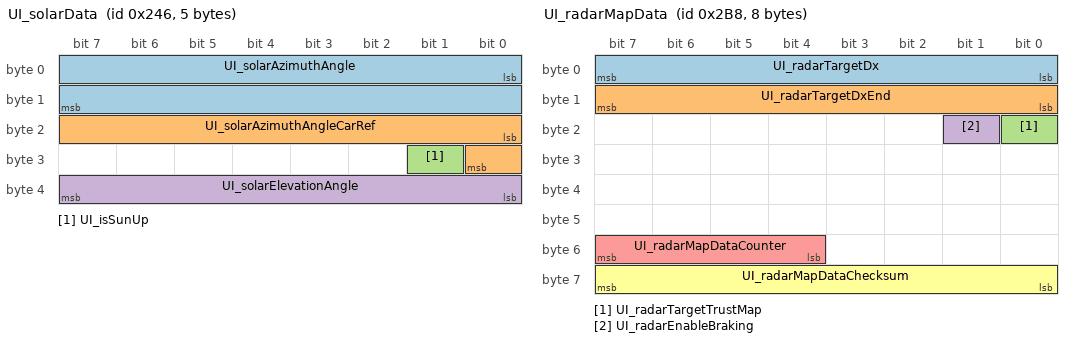
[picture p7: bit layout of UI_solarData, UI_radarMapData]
BO_ 582 UI_solarData: 5 XXX
 SG_ UI_solarAzimuthAngle : 0|16@1- (1,0) [0|360] "deg" XXX
 SG_ UI_solarAzimuthAngleCarRef : 16|9@1- (1,0) [-180|180] "deg" XXX
 SG_ UI_isSunUp : 25|1@1+ (1,0) [0|0] "" Vector__XXX
 SG_ UI_solarElevationAngle : 32|8@1- (1,0) [-90|90] "deg" XXX

BO_ 643 BODY_R1: 8 XXX
 SG_ AirTemp_Insd : 47|8@0+ (0.25,0) [0|63.5] "C"  XXX
 SG_ AirTemp_Outsd : 63|8@0+ (0.5,-40) [-40|86.5] "C"  XXX
 SG_ Bckl_Sw_RL_Stat_SAM_R : 49|2@0+ (1,0) [-1|4] ""  XXX
 SG_ Bckl_Sw_RM_Stat_SAM_R : 53|2@0+ (1,0) [-1|4] ""  XXX
 SG_ Bckl_Sw_RR_Stat_SAM_R : 51|2@0+ (1,0) [-1|4] ""  XXX
 SG_ DL_RLtch_Stat : 9|2@0+ (1,0) [-1|4] ""  XXX
 SG_ DrRLtch_FL_Stat : 1|2@0+ (1,0) [-1|4] ""  XXX
 SG_ DrRLtch_FR_Stat : 3|2@0+ (1,0) [-1|4] ""  XXX
 SG_ DrRLtch_RL_Stat : 5|2@0+ (1,0) [-1|4] ""  XXX
 SG_ DrRLtch_RR_Stat : 7|2@0+ (1,0) [-1|4] ""  XXX
 SG_ EngHd_Stat : 11|2@0+ (1,0) [-1|4] ""  XXX
 SG_ LoBm_On_Rq : 32|1@0+ (1,0) [0|1] ""  XXX
 SG_ HiBm_On : 33|1@0+ (1,0) [0|1] ""  XXX
 SG_ Hrn_On : 26|1@0+ (1,0) [0|1] ""  XXX
 SG_ IrLmp_D_Lt_Flt : 34|1@0+ (1,0) [0|1] ""  XXX
 SG_ IrLmp_P_Rt_Flt : 35|1@0+ (1,0) [0|1] ""  XXX
 SG_ LgtSens_Twlgt : 18|3@0+ (1,0) [0|7] "Steps"  XXX
 SG_ LgtSens_SNA : 19|1@0+ (1,0) [0|1] ""  XXX
 SG_ LgtSens_Tunnel : 20|1@0+ (1,0) [0|1] ""  XXX
 SG_ LgtSens_Flt : 21|1@0+ (1,0) [0|1] ""  XXX
 SG_ LgtSens_Night : 22|1@0+ (1,0) [-1|2] ""  XXX
 SG_ ADL_LoBm_On_Rq : 23|1@0+ (1,0) [0|1] ""  XXX
 SG_ LoBm_D_Lt_Flt : 36|1@0+ (1,0) [0|1] ""  XXX
 SG_ LoBm_P_Rt_Flt : 37|1@0+ (1,0) [0|1] ""  XXX
 SG_ MPkBrk_Stat : 28|1@0+ (1,0) [-1|2] ""  XXX
 SG_ RevGr_Engg : 39|2@0+ (1,0) [-1|4] ""  XXX
 SG_ StW_Cond_Stat : 55|2@0+ (1,0) [-1|4] ""  XXX
 SG_ Term54_Actv : 27|1@0+ (1,0) [0|1] ""  XXX
 SG_ Trlr_Stat : 25|2@0+ (1,0) [-1|4] ""  XXX
 SG_ VTA_Alm_Actv : 13|1@0+ (1,0) [0|1] ""  XXX
 SG_ WprOutsdPkPosn : 29|1@0+ (1,0) [0|1] ""  XXX

BO_ 696 UI_radarMapData: 8 XXX
 SG_ UI_radarTargetDx : 0|8@1+ (1,-95) [-95|160] "m" XXX
 SG_ UI_radarTargetDxEnd : 8|8@1+ (1,0) [0|255] "m" XXX
 SG_ UI_radarTargetTrustMap : 16|1@1+ (1,0) [0|1] "" XXX
 SG_ UI_radarEnableBraking : 17|1@1+ (1,0) [0|1] "" XXX
 SG_ UI_radarMapDataCounter : 52|4@1+ (1,0) [0|0] "" XXX
 SG_ UI_radarMapDataChecksum : 56|8@1+ (1,0) [0|0] "" XXX

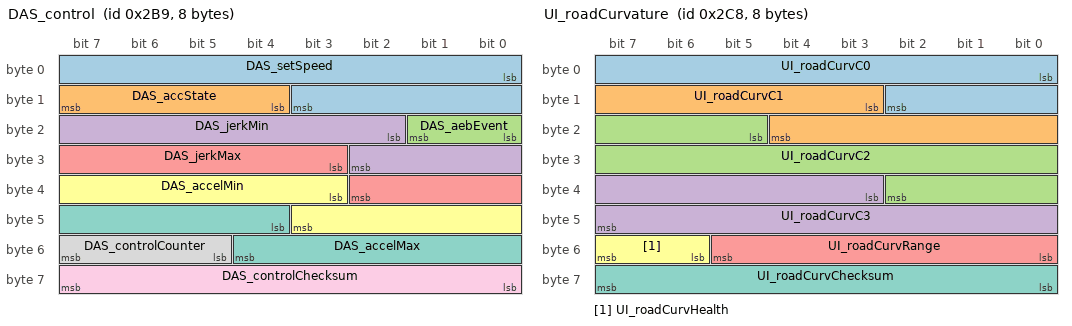
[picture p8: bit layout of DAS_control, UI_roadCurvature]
BO_ 697 DAS_control: 8 NEO
 SG_ DAS_setSpeed : 0|12@1+ (0.1,0) [0|409.4] "kph" NEO
 SG_ DAS_accState : 12|4@1+ (1,0) [0|0] "" NEO
 SG_ DAS_aebEvent : 16|2@1+ (1,0) [0|3] "" NEO
 SG_ DAS_jerkMin : 18|9@1+ (0.03,-15.232) [-15.232|0.098] "m/s^3" NEO
 SG_ DAS_jerkMax : 27|8@1+ (0.059,0) [0|15.045] "m/s^3" NEO
 SG_ DAS_accelMin : 35|9@1+ (0.04,-15) [-15|5.44] "m/s^2" NEO
 SG_ DAS_accelMax : 44|9@1+ (0.04,-15) [-15|5.44] "m/s^2" NEO
 SG_ DAS_controlCounter : 53|3@1+ (1,0) [0|0] "" NEO
 SG_ DAS_controlChecksum : 56|8@1+ (1,0) [0|0] "" NEO

BO_ 712 UI_roadCurvature: 8 XXX
 SG_ UI_roadCurvC0 : 0|11@1- (0.02,0) [-20.48|20.46] "m" XXX
 SG_ UI_roadCurvC1 : 11|10@1- (0.00075,0) [-0.384|0.38325] "1" XXX
 SG_ UI_roadCurvC2 : 21|14@1- (7.5E-06,0) [-0.03072|0.03071625] "1/m" XXX
 SG_ UI_roadCurvC3 : 35|13@1- (3E-08,0) [-0.00012288|0.00012285] "1/m2" XXX
 SG_ UI_roadCurvRange : 48|6@1+ (4,0) [0|252] "m" XXX
 SG_ UI_roadCurvHealth : 54|2@1+ (1,0) [0|0] "" XXX
 SG_ UI_roadCurvChecksum : 56|8@1+ (1,0) [0|0] "" Vector__XXX

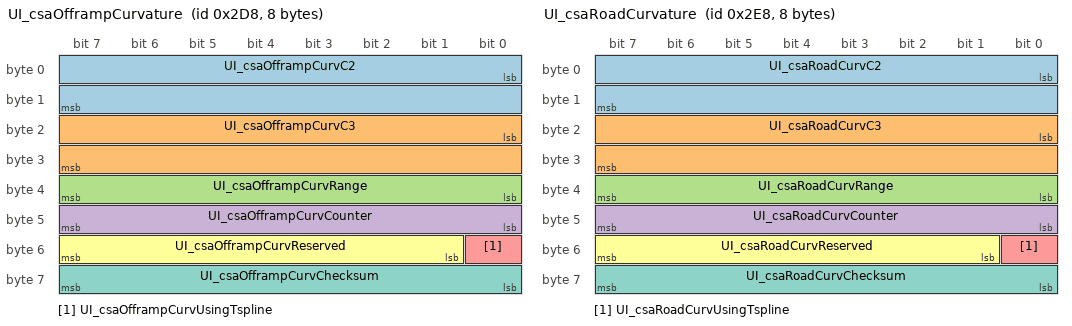
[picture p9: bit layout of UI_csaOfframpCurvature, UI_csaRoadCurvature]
BO_ 728 UI_csaOfframpCurvature: 8 XXX
 SG_ UI_csaOfframpCurvC2 : 0|16@1- (1E-06,0) [-0.032768|0.032767] "1/m" XXX
 SG_ UI_csaOfframpCurvC3 : 16|16@1- (4E-09,0) [-0.000131072|0.000131068] "1/m2" XXX
 SG_ UI_csaOfframpCurvRange : 32|8@1+ (2,0) [0|510] "m" XXX
 SG_ UI_csaOfframpCurvCounter : 40|8@1+ (1,0) [0|255] "" Vector__XXX
 SG_ UI_csaOfframpCurvUsingTspline : 48|1@1+ (1,0) [0|1] "" XXX
 SG_ UI_csaOfframpCurvReserved : 49|7@1+ (1,0) [0|0] "" Vector__XXX
 SG_ UI_csaOfframpCurvChecksum : 56|8@1+ (1,0) [0|0] "" Vector__XXX

BO_ 744 UI_csaRoadCurvature: 8 XXX
 SG_ UI_csaRoadCurvC2 : 0|16@1- (1E-06,0) [-0.032768|0.032767] "1/m" XXX
 SG_ UI_csaRoadCurvC3 : 16|16@1- (4E-09,0) [-0.000131072|0.000131068] "1/m2" XXX
 SG_ UI_csaRoadCurvRange : 32|8@1+ (2,0) [0|510] "m" XXX
 SG_ UI_csaRoadCurvCounter : 40|8@1+ (1,0) [0|255] "" Vector__XXX
 SG_ UI_csaRoadCurvUsingTspline : 48|1@1+ (1,0) [0|1] "" XXX
 SG_ UI_csaRoadCurvReserved : 49|7@1+ (1,0) [0|0] "" Vector__XXX
 SG_ UI_csaRoadCurvChecksum : 56|8@1+ (1,0) [0|0] "" Vector__XXX

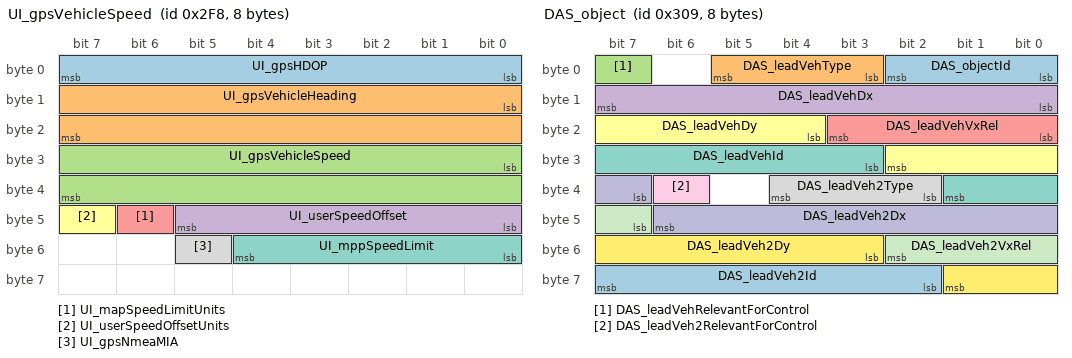
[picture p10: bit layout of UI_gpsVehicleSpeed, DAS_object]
BO_ 760 UI_gpsVehicleSpeed: 8 XXX
 SG_ UI_gpsHDOP : 0|8@1+ (0.1,0) [0|25.5] "1" XXX
 SG_ UI_gpsVehicleHeading : 8|16@1+ (0.0078125,0) [0|511.9921875] "deg" XXX
 SG_ UI_gpsVehicleSpeed : 24|16@1+ (0.00390625,0) [0|250.996] "km/hr" Vector__XXX
 SG_ UI_userSpeedOffset : 40|6@1+ (1,-30) [-30|33] "kph/mph" XXX
 SG_ UI_mapSpeedLimitUnits : 46|1@1+ (1,0) [0|1] "" XXX
 SG_ UI_userSpeedOffsetUnits : 47|1@1+ (1,0) [0|1] "" XXX
 SG_ UI_mppSpeedLimit : 48|5@1+ (5,0) [0|155] "kph/mph" XXX
 SG_ UI_gpsNmeaMIA : 53|1@1+ (1,0) [0|0] "" XXX

BO_ 777 DAS_object: 8 XXX
 SG_ DAS_objectId : 0|3@1+ (1,0) [0|7] "" XXX
 SG_ DAS_leadVehType : 3|3@1+ (1,0) [0|7] "" XXX
 SG_ DAS_leadVehRelevantForControl : 7|1@1+ (1,0) [0|1] "" XXX
 SG_ DAS_leadVehDx : 8|8@1+ (0.5,0) [0|127] "m" XXX
 SG_ DAS_leadVehVxRel : 16|4@1+ (4,-30) [-30|26] "m/s" XXX
 SG_ DAS_leadVehDy : 20|7@1+ (0.35,-22.05) [-22.05|22.4] "m" XXX
 SG_ DAS_leadVehId : 27|7@1+ (1,0) [0|126] "" XXX
 SG_ DAS_leadVeh2Type : 34|3@1+ (1,0) [0|7] "" XXX
 SG_ DAS_leadVeh2RelevantForControl : 38|1@1+ (1,0) [0|1] "" XXX
 SG_ DAS_leadVeh2Dx : 39|8@1+ (0.5,0) [0|127] "m" XXX
 SG_ DAS_leadVeh2VxRel : 47|4@1+ (4,-30) [-30|26] "m/s" XXX
 SG_ DAS_leadVeh2Dy : 51|7@1+ (0.35,-22.05) [-22.05|22.4] "m" XXX
 SG_ DAS_leadVeh2Id : 58|6@1+ (1,0) [0|63] "" XXX

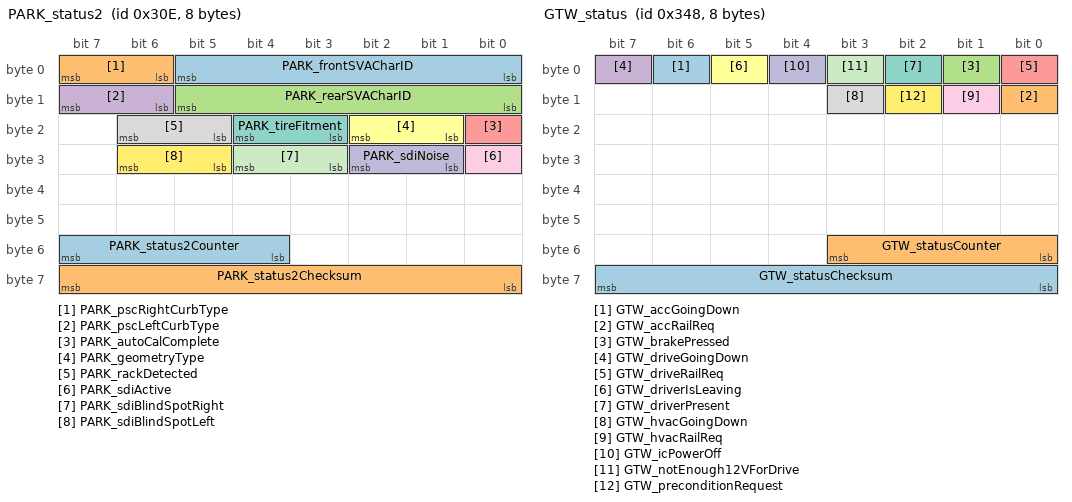
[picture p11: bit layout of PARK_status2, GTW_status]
BO_ 782 PARK_status2: 8 PARK
 SG_ PARK_frontSVACharID : 0|6@1+ (1,0) [0|63] "" DAS,GTW
 SG_ PARK_pscRightCurbType : 6|2@1+ (1,0) [0|3] "" DAS,GTW
 SG_ PARK_rearSVACharID : 8|6@1+ (1,0) [0|63] "" DAS,GTW
 SG_ PARK_pscLeftCurbType : 14|2@1+ (1,0) [0|3] "" DAS,GTW
 SG_ PARK_autoCalComplete : 16|1@1+ (1,0) [0|1] "" DAS,GTW
 SG_ PARK_geometryType : 17|2@1+ (1,0) [0|3] "" GTW
 SG_ PARK_tireFitment : 19|2@1+ (1,0) [0|3] "" DAS,GTW
 SG_ PARK_rackDetected : 21|2@1+ (1,0) [0|3] "" DAS,GTW
 SG_ PARK_sdiActive : 24|1@1+ (1,0) [0|1] "" DAS,GTW
 SG_ PARK_sdiNoise : 25|2@1+ (1,0) [0|3] "" DAS,GTW
 SG_ PARK_sdiBlindSpotRight : 27|2@1+ (1,0) [0|3] "" DAS,GTW
 SG_ PARK_sdiBlindSpotLeft : 29|2@1+ (1,0) [0|3] "" DAS,GTW
 SG_ PARK_status2Counter : 52|4@1+ (1,0) [0|0] "" GTW,DAS
 SG_ PARK_status2Checksum : 56|8@1+ (1,0) [0|0] "" GTW

BO_ 792 GTW_carState: 8 XXX
 SG_ YEAR : 0|7@1+ (1,2000) [2000|2127] "Year" XXX
 SG_ CERRD : 7|1@1+ (1,0) [0|1] "" XXX
 SG_ MONTH : 8|4@1+ (1,0) [1|12] "Month" XXX
 SG_ DOOR_STATE_FL : 12|2@1+ (1,0) [0|3] "" XXX
 SG_ DOOR_STATE_FR : 14|2@1+ (1,0) [0|3] "" XXX
 SG_ SECOND : 16|6@1+ (1,0) [0|59] "s" XXX
 SG_ DOOR_STATE_RL : 22|2@1+ (1,0) [0|3] "" XXX
 SG_ Hour : 24|5@1+ (1,0) [0|23] "h" XXX
 SG_ DOOR_STATE_RR : 29|2@1+ (1,0) [0|3] "" XXX
 SG_ DAY : 32|5@1+ (1,0) [0|31] "" XXX
 SG_ MINUTE : 40|6@1+ (1,0) [0|59] "min" XXX
 SG_ BOOT_STATE : 46|2@1+ (1,0) [0|3] "" XXX
 SG_ GTW_updateInProgress : 48|2@1+ (1,0) [0|3] "" XXX
 SG_ DOOR_STATE_FrontTrunk : 50|2@1+ (1,0) [0|3] "" XXX
 SG_ MCU_factoryMode : 52|1@1+ (1,0) [0|1] "" XXX
 SG_ MCU_transportModeOn : 53|1@0+ (1,0) [0|1] "" XXX
 SG_ BC_headLightLStatus : 55|2@0+ (1,0) [0|3] "" XXX
 SG_ BC_headLightRStatus : 57|2@0+ (1,0) [0|3] "" XXX
 SG_ BC_indicatorLStatus : 59|2@0+ (1,0) [0|3] "" XXX
 SG_ BC_indicatorRStatus : 61|2@0+ (1,0) [0|3] "" XXX

BO_ 824 UI_status: 8 XXX
 SG_ UI_touchActive : 0|1@1+ (1,0) [0|0] "" IC
 SG_ UI_audioActive : 1|1@1+ (1,0) [0|0] "" IC
 SG_ UI_bluetoothActive : 2|1@1+ (1,0) [0|0] "" IC
 SG_ UI_cellActive : 3|1@1+ (1,0) [0|0] "" IC
 SG_ UI_displayReady : 4|1@1+ (1,0) [0|0] "" IC
 SG_ UI_gpsActive : 5|1@1+ (1,0) [0|0] "" IC
 SG_ UI_wifiConnected : 6|1@1+ (1,0) [0|0] "" IC,XXX
 SG_ UI_systemActive : 7|1@1+ (1,0) [0|0] "" IC
 SG_ UI_xmActive : 8|1@1+ (1,0) [0|0] "" IC
 SG_ UI_displayOn : 9|1@1+ (1,0) [0|0] "" IC,XXX
 SG_ UI_readyForDrive : 10|1@1+ (1,0) [0|0] "" IC
 SG_ UI_cellConnected : 11|1@1+ (1,0) [0|0] "" IC,XXX
 SG_ UI_vpnActive : 12|1@1+ (1,0) [0|0] "" IC,XXX
 SG_ UI_wifiActive : 13|1@1+ (1,0) [0|0] "" IC
 SG_ UI_cameraActive : 14|1@1+ (1,0) [0|0] "" IC,XXX
 SG_ UI_usbActive : 15|1@1+ (1,0) [0|0] "" IC
 SG_ UI_screenshotActive : 16|1@1+ (1,0) [0|0] "" IC,XXX
 SG_ UI_monitorModemPower : 17|1@1+ (1,0) [0|0] "" Vector__XXX
 SG_ UI_factoryReset : 18|2@1+ (1,0) [0|3] "" Vector__XXX
 SG_ UI_cellNetworkTechnology : 20|4@1+ (1,0) [0|15] "" XXX
 SG_ UI_tegraCoreTemperature : 24|8@1+ (1,-64) [0|0] "deg C" IC
 SG_ UI_tegraAmbientTemperature : 32|8@1+ (1,-64) [0|0] "deg C" IC
 SG_ UI_googleWifiUsages : 40|8@1+ (1,0) [0|0] "" Vector__XXX
 SG_ UI_autopilotTrial : 48|2@1+ (1,0) [0|0] "" XXX
 SG_ UI_cellSignalBars : 50|3@1+ (1,0) [0|7] "" XXX
 SG_ UI_hardwareType : 53|2@1+ (1,0) [0|3] "" XXX
 SG_ UI_developmentCar : 55|1@1+ (1,0) [0|0] "" Vector__XXX
 SG_ UI_cellReceiverPower : 56|8@1+ (1,-128) [-128|127] "dB" XXX

BO_ 840 GTW_status: 8 XXX
 SG_ GTW_accGoingDown : 6|1@0+ (1,0) [0|1] ""  XXX
 SG_ GTW_accRailReq : 8|1@0+ (1,0) [0|1] ""  XXX
 SG_ GTW_brakePressed : 1|1@0+ (1,0) [0|1] ""  XXX
 SG_ GTW_driveGoingDown : 7|1@0+ (1,0) [0|1] ""  XXX
 SG_ GTW_driveRailReq : 0|1@0+ (1,0) [0|1] ""  XXX
 SG_ GTW_driverIsLeaving : 5|1@0+ (1,0) [0|1] ""  XXX
 SG_ GTW_driverPresent : 2|1@0+ (1,0) [0|1] ""  XXX
 SG_ GTW_hvacGoingDown : 11|1@0+ (1,0) [0|1] ""  XXX
 SG_ GTW_hvacRailReq : 9|1@0+ (1,0) [0|1] ""  XXX
 SG_ GTW_icPowerOff : 4|1@0+ (1,0) [0|1] ""  XXX
 SG_ GTW_notEnough12VForDrive : 3|1@0+ (1,0) [0|1] ""  XXX
 SG_ GTW_preconditionRequest : 10|1@0+ (1,0) [0|1] ""  XXX
 SG_ GTW_statusChecksum : 63|8@0+ (1,0) [0|255] ""  XXX
 SG_ GTW_statusCounter : 51|4@0+ (1,0) [0|15] ""  XXX

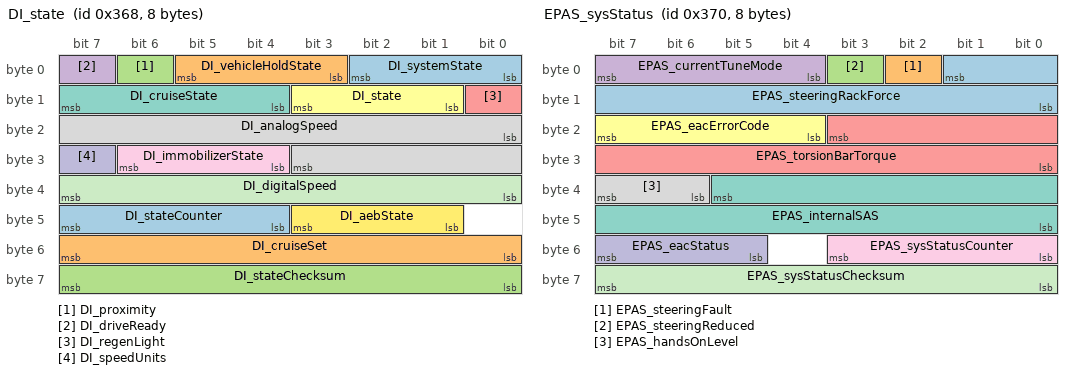
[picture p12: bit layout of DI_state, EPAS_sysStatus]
BO_ 872 DI_state: 8 DI
 SG_ DI_systemState : 0|3@1+ (1,0) [0|0] ""  NEO
 SG_ DI_vehicleHoldState : 3|3@1+ (1,0) [0|0] ""  NEO
 SG_ DI_proximity : 6|1@1+ (1,0) [0|0] ""  NEO
 SG_ DI_driveReady : 7|1@1+ (1,0) [0|0] ""  NEO
 SG_ DI_regenLight : 8|1@1+ (1,0) [0|0] ""  NEO
 SG_ DI_state : 9|3@1+ (1,0) [0|0] ""  NEO
 SG_ DI_cruiseState : 12|4@1+ (1,0) [0|0] ""  NEO
 SG_ DI_analogSpeed : 16|12@1+ (0.1,0) [0|150] "speed"  NEO
 SG_ DI_immobilizerState : 28|3@1+ (1,0) [0|0] ""  NEO
 SG_ DI_speedUnits : 31|1@1+ (1,0) [0|1] ""  NEO
 SG_ DI_digitalSpeed : 32|8@1+ (1,0) [0|255.5] "speed"  NEO
 SG_ DI_aebState : 41|3@1+ (1,0) [0|0] ""  NEO
 SG_ DI_stateCounter : 44|4@1+ (1,0) [0|0] ""  NEO
 SG_ DI_cruiseSet : 48|8@1+ (1,0) [0|250] ""  NEO
 SG_ DI_stateChecksum : 56|8@1+ (1,0) [0|0] ""  NEO

BO_ 880 EPAS_sysStatus: 8 EPAS
 SG_ EPAS_steeringRackForce : 1|10@0+ (50,-25575) [-25575|25575] "N" NEO
 SG_ EPAS_steeringFault : 2|1@0+ (1,0) [0|1] "" NEO
 SG_ EPAS_steeringReduced : 3|1@0+ (1,0) [0|1] "" NEO
 SG_ EPAS_currentTuneMode : 7|4@0+ (1,0) [0|15] "" NEO
 SG_ EPAS_torsionBarTorque : 19|12@0+ (0.01,-20.5) [-20.5|20.45] "Nm" NEO
 SG_ EPAS_eacErrorCode : 23|4@0+ (1,0) [0|15] "" NEO
 SG_ EPAS_internalSAS : 37|14@0+ (0.1,-819.2) [-819.2|819] "deg" NEO
 SG_ EPAS_handsOnLevel : 39|2@0+ (1,0) [0|3] "" NEO
 SG_ EPAS_sysStatusCounter : 51|4@0+ (1,0) [0|15] "" NEO
 SG_ EPAS_eacStatus : 55|3@0+ (1,0) [0|7] "" NEO
 SG_ EPAS_sysStatusChecksum : 63|8@0+ (1,0) [0|255] "" NEO

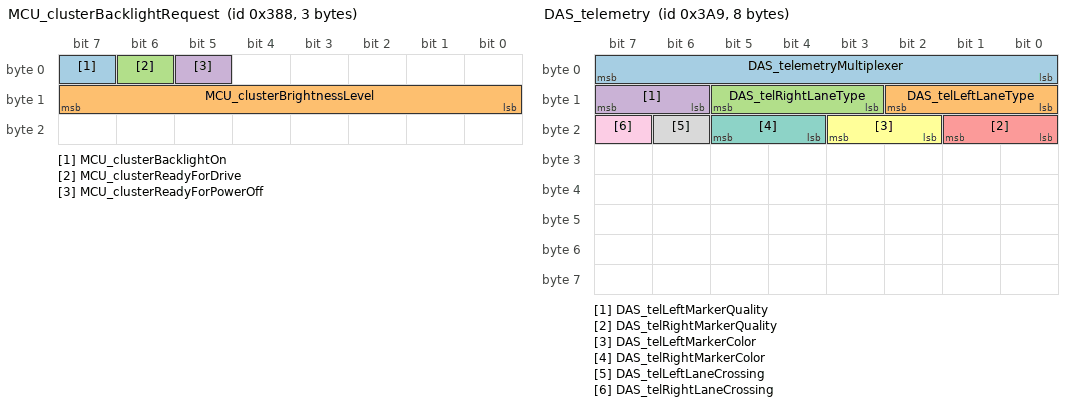
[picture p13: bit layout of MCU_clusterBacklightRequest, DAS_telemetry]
BO_ 904 MCU_clusterBacklightRequest: 3 XXX
 SG_ MCU_clusterBacklightOn : 7|1@1+ (1,0) [0|1] "" XXX
 SG_ MCU_clusterBrightnessLevel : 8|8@1+ (0.5,0) [0|127.5] "%" XXX
 SG_ MCU_clusterReadyForDrive : 6|1@1+ (1,0) [-1|2] ""  XXX
 SG_ MCU_clusterReadyForPowerOff : 5|1@1+ (1,0) [0|1] "" XXX

BO_ 905 DAS_status2: 8 XXX
 SG_ DAS_accSpeedLimit : 0|10@1+ (0.2,0) [0|204.6] "mph" GTW,APS
 SG_ DAS_pmmObstacleSeverity : 10|3@1+ (1,0) [0|7] "" GTW,APS
 SG_ DAS_pmmLoggingRequest : 13|1@1+ (1,0) [0|1] "" GTW,APS
 SG_ DAS_activationFailureStatus : 14|2@1+ (1,0) [0|1] "" GTW,APS
 SG_ DAS_pmmUltrasonicsFaultReason : 16|3@1+ (1,0) [0|7] "" GTW,APS
 SG_ DAS_pmmRadarFaultReason : 19|2@1+ (1,0) [0|3] "" GTW,APS
 SG_ DAS_pmmSysFaultReason : 21|3@1+ (1,0) [0|7] "" GTW,APS
 SG_ DAS_pmmCameraFaultReason : 24|2@1+ (1,0) [0|3] "" GTW,APS
 SG_ DAS_ACC_report : 26|5@1+ (1,0) [0|0] "" GTW,APS
 SG_ DAS_relaxCruiseLimits : 31|1@1+ (1,0) [0|0] "" GTW,APS,APP
 SG_ DAS_csaState : 32|2@1+ (1,0) [0|0] "" GTW,APS
 SG_ DAS_radarTelemetry : 34|2@1+ (1,0) [0|0] "" GTW,APS
 SG_ DAS_robState : 36|2@1+ (1,0) [0|3] "" GTW,APS
 SG_ DAS_driverInteractionLevel : 38|2@1+ (1,0) [0|3] "" GTW,APS
 SG_ DAS_ppOffsetDesiredRamp : 40|8@1+ (0.01,-1.28) [-1.28|1.27] "m" GTW,APS
 SG_ DAS_longCollisionWarning : 48|4@1+ (1,0) [0|15] "" GTW,APS
 SG_ DAS_status2Counter : 52|4@1+ (1,0) [0|0] "" GTW,APS
 SG_ DAS_status2Checksum : 56|8@1+ (1,0) [0|0] "" GTW,APS

BO_ 920 GTW_carConfig: 8 XXX
 SG_ GTW_performanceConfig : 2|3@0+ (1,0) [0|0] "" XXX
 SG_ GTW_fourWheelDrive : 4|2@0+ (1,0) [0|0] ""  XXX
 SG_ GTW_unknown1 : 5|1@0+ (1,0) [0|0] ""  XXX
 SG_ GTW_dasHw : 7|2@0+ (1,0) [0|0] ""  XXX
 SG_ GTW_parkAssistInstalled : 9|2@0+ (1,0) [0|0] ""  XXX
 SG_ GTW_forwardRadarHw : 11|2@0+ (1,0) [0|0] "" XXX
 SG_ GTW_airSuspensionInstalled : 14|3@0+ (1,0) [0|0] ""  XXX
 SG_ GTW_unknown2 : 15|1@0+ (1,0) [0|0] ""  XXX
 SG_ GTW_country : 23|16@0+ (1,0) [0|0] ""  XXX
 SG_ GTW_parkSensorGeometryType : 33|2@0+ (1,0) [0|0] ""  XXX
 SG_ GTW_rhd : 34|1@0+ (1,0) [0|0] ""  XXX
 SG_ GTW_bodyControlsType : 35|1@0+ (1,0) [0|0] "" XXX
 SG_ GTW_radarPosition : 39|4@0+ (1,0) [0|0] ""  XXX
 SG_ GTW_rearCornerRadarHw : 41|2@0+ (1,0) [0|0] ""  XXX
 SG_ GTW_frontCornerRadarHw : 43|2@0+ (1,0) [0|0] ""  XXX
 SG_ GTW_epasType : 45|2@0+ (1,0) [0|0] ""  XXX
 SG_ GTW_chassisType : 47|2@0+ (1,0) [0|2] ""  XXX
 SG_ GTW_wheelType : 52|5@0+ (1,0) [0|0] ""  XXX
 SG_ GTW_rearSeatControllerMask : 55|3@0+ (1,0) [0|7] ""  XXX
 SG_ GTW_euVehicle : 56|1@0+ (1,0) [0|0] "" XXX
 SG_ GTW_foldingMirrorsInstalled : 57|1@0+ (1,0) [0|0] ""  XXX
 SG_ GTW_brakeHwType : 59|2@0+ (1,0) [0|2] ""  XXX
 SG_ GTW_autopilot : 61|2@0+ (1,0) [0|0] ""  XXX
 SG_ GTW_unknown3 : 63|2@0+ (1,0) [0|0] ""  XXX

BO_ 921 DAS_status: 8 XXX
 SG_ DAS_autopilotState : 0|4@1+ (1,0) [0|0] "" GTW,APS,TAS2
 SG_ DAS_blindSpotRearLeft : 4|2@1+ (1,0) [0|0] "" GTW,APS
 SG_ DAS_blindSpotRearRight : 6|2@1+ (1,0) [0|0] "" GTW,APS
 SG_ DAS_fusedSpeedLimit : 8|5@1+ (5,0) [0|150] "kph/mph" GTW,APS
 SG_ DAS_suppressSpeedWarning : 13|1@1+ (1,0) [0|0] "" GTW,APS
 SG_ DAS_summonObstacle : 14|1@1+ (1,0) [0|0] "" GTW,APS
 SG_ DAS_summonClearedGate : 15|1@1+ (1,0) [0|0] "" GTW,APS
 SG_ DAS_visionOnlySpeedLimit : 16|5@1+ (5,0) [0|150] "kph/mph" GTW,APS
 SG_ DAS_heaterState : 21|1@1+ (1,0) [0|0] "" GTW
 SG_ DAS_forwardCollisionWarning : 22|2@1+ (1,0) [0|0] "" GTW,APS
 SG_ DAS_autoparkReady : 24|1@1+ (1,0) [0|1] "" GTW,APS
 SG_ DAS_autoParked : 25|1@1+ (1,0) [0|0] "" GTW,APS
 SG_ DAS_autoparkWaitingForBrake : 26|1@1+ (1,0) [0|1] "" GTW,APS
 SG_ DAS_summonFwdLeashReached : 27|1@1+ (1,0) [0|1] "" GTW,APS
 SG_ DAS_summonRvsLeashReached : 28|1@1+ (1,0) [0|1] "" GTW,APS
 SG_ DAS_lssState : 29|3@1+ (1,0) [0|0] "" GTW,APS,EPB
 SG_ DAS_sideCollisionAvoid : 32|2@1+ (1,0) [0|0] "" GTW,APS
 SG_ DAS_sideCollisionWarning : 34|2@1+ (1,0) [0|0] "" GTW,APS
 SG_ DAS_sideCollisionInhibit : 36|1@1+ (1,0) [0|0] "" GTW,APS
 SG_ DAS_laneDepartureWarning : 37|3@1+ (1,0) [0|0] "" GTW,APS
 SG_ DAS_fleetSpeedState : 40|2@1+ (1,0) [0|0] "" GTW,APS
 SG_ DAS_autopilotHandsOnState : 42|4@1+ (1,0) [0|0] "" GTW,APS
 SG_ DAS_autoLaneChangeState : 46|5@1+ (1,0) [0|0] "" GTW,APS
 SG_ DAS_summonAvailable : 51|1@1+ (1,0) [0|1] "" GTW,APS
 SG_ DAS_statusCounter : 52|4@1+ (1,0) [0|0] "" GTW,APS,TAS2
 SG_ DAS_statusChecksum : 56|8@1+ (1,0) [0|0] "" GTW,APS,TAS2

BO_ 937 DAS_telemetry: 8 XXX
 SG_ DAS_telemetryMultiplexer : 0|8@1+ (1,0) [0|0] "" XXX
 SG_ DAS_telLeftLaneType : 8|3@1+ (1,0) [0|0] "" XXX
 SG_ DAS_telRightLaneType : 11|3@1+ (1,0) [0|0] "" XXX
 SG_ DAS_telLeftMarkerQuality : 14|2@1+ (1,0) [0|0] "" XXX
 SG_ DAS_telRightMarkerQuality : 16|2@1+ (1,0) [0|0] "" XXX
 SG_ DAS_telLeftMarkerColor : 18|2@1+ (1,0) [0|0] "" XXX
 SG_ DAS_telRightMarkerColor : 20|2@1+ (1,0) [0|0] "" XXX
 SG_ DAS_telLeftLaneCrossing : 22|1@1+ (1,0) [0|0] "" XXX
 SG_ DAS_telRightLaneCrossing : 23|1@1+ (1,0) [0|0] "" XXX

BO_ 938 DAS_telemetryM: 8 XXX
 SG_ DAS_telemetryMultiplexerM M : 0|8@1+ (1,0) [0|0] "" XXX
 SG_ DAS_telLeftLaneType m0 : 8|3@1+ (1,0) [0|0] "" XXX
 SG_ DAS_telRightLaneType m0 : 11|3@1+ (1,0) [0|0] "" XXX
 SG_ DAS_telLeftMarkerQuality m0 : 14|2@1+ (1,0) [0|0] "" XXX
 SG_ DAS_telRightMarkerQuality m0 : 16|2@1+ (1,0) [0|0] "" XXX
 SG_ DAS_telLeftMarkerColor m0 : 18|2@1+ (1,0) [0|0] "" XXX
 SG_ DAS_telRightMarkerColor m0 : 20|2@1+ (1,0) [0|0] "" XXX
 SG_ DAS_telLeftLaneCrossing m0 : 22|1@1+ (1,0) [0|0] "" XXX
 SG_ DAS_telRightLaneCrossing m0 : 23|1@1+ (1,0) [0|0] "" XXX
 SG_ DAS_MCPObserved m1 : 8|1@1+ (1,0) [0|1] "" XXX
 SG_ DAS_accReengaged m1 : 9|1@1+ (1,0) [0|1] "" XXX
 SG_ DAS_pedestrianInFOVBeforeIntr m1 : 10|1@1+ (1,0) [0|1] "" XXX
 SG_ DAS_pedestrianInFOVAfterIntr m1 : 11|1@1+ (1,0) [0|1] "" XXX
 SG_ DAS_camFreeSpaceBeforeIntr m1 : 12|1@1+ (1,0) [0|1] "" XXX
 SG_ DAS_camFreeSpaceAfterIntr m1 : 13|1@1+ (1,0) [0|1] "" XXX
 SG_ DAS_timeOfIntervention m1 : 14|6@1+ (0.25,0) [0|16] "s" XXX
 SG_ DAS_timeOfFirstPedestrian m1 : 20|6@1+ (0.25,0) [0|16] "s" XXX
 SG_ DAS_timeOfACCReengaging m1 : 26|6@1+ (0.25,0) [0|16] "s" XXX
 SG_ DAS_durationOfPrevACCStandstill m1 : 32|6@1+ (0.5,0) [0|30] "s" XXX
 SG_ DAS_maxAbsSteeringWheelAngle m1 : 38|7@1+ (2,0) [0|256] "degrees" XXX
 SG_ DAS_targetRelvelAtIntervention m1 : 45|6@1+ (0.25,-2) [-2|13.5] "m/s" XXX
 SG_ DAS_targetDistAtIntervention m1 : 51|6@1+ (0.5,0) [0|32] "m" XXX
 SG_ DAS_egoSpeedAtIntervention m1 : 57|6@1+ (0.5,0) [0|32] "m/s" XXX
 SG_ DAS_stopSignLongitudinalDist m2 : 8|10@1+ (0.1,0) [0|102.2] "m" XXX
 SG_ DAS_stopSignLateralDist m2 : 18|8@1+ (0.25,-32) [-32|31.5] "m" XXX
 SG_ DAS_stopSignHeight m2 : 26|6@1+ (0.1,0) [0|6.2] "m" XXX
 SG_ DAS_stopSignStopLineDistance m2 : 32|10@1+ (0.1,-20) [-20|82.2] "m" XXX
 SG_ DAS_stopSignCIPVDistance m2 : 42|6@1+ (0.5,0) [0|31.5] "m" XXX
 SG_ DAS_stopSignHostAccel m2 : 48|10@1+ (0.01,-5) [-5|5.23] "m/s^2" XXX
 SG_ DAS_stopSignCrossingWarning m2 : 58|1@1+ (1,0) [0|1] "" XXX
 SG_ DAS_stopSignIndex m2 : 59|4@1+ (1,0) [0|15] "" XXX
 SG_ DAS_csaOverride m7 : 10|1@1+ (1,0) [0|0] "" XXX
 SG_ DAS_csaIntState m7 : 11|3@1+ (1,0) [0|3] "" XXX
 SG_ DAS_csaEnableSpeed m7 : 14|12@1+ (0.05,-25) [-25|179.75] "MPH" XXX
 SG_ DAS_csaDisableSpeed m7 : 26|12@1+ (0.05,-25) [-25|179.75] "MPH" XXX
 SG_ DAS_csaFiltCurv m7 : 40|16@1- (1E-06,0) [-0.032768|0.032767] "1/m" XXX
 SG_ DAS_csaMeasLatAccel m7 : 56|8@1+ (0.08,-10.24) [-10.24|10] "m/s^2" XXX
 SG_ DAS_soCamCipvStatus m8 : 8|2@1+ (1,0) [0|3] "" XXX
 SG_ DAS_soRad5Status m8 : 10|2@1+ (1,0) [0|3] "" XXX
 SG_ DAS_soRad1Status m8 : 12|2@1+ (1,0) [0|3] "" XXX
 SG_ DAS_soCamCipvDx m8 : 14|6@1+ (2,0) [0|126] "m" XXX
 SG_ DAS_soRad1Dx m8 : 20|6@1+ (2,0) [0|126] "m" XXX
 SG_ DAS_soRad5Dx m8 : 26|6@1+ (2,0) [0|126] "m" XXX
 SG_ DAS_soCamCipvDy m8 : 32|5@1+ (0.4,-6.4) [-6.4|6] "m" XXX
 SG_ DAS_soRad5Dy m8 : 37|5@1+ (0.4,-6.4) [-6.4|6] "m" XXX
 SG_ DAS_soCamCipvVx m8 : 42|5@1+ (1,0) [0|31] "m/s" XXX
 SG_ DAS_soRad5ObstProb m8 : 47|4@1+ (0.0625,0) [0|0.9375] "probability" XXX
 SG_ DAS_soRad5Dz m8 : 51|6@1+ (0.25,-5) [-5|10.75] "m" XXX
 SG_ DAS_soRad5powerdB m8 : 57|7@1+ (2,0) [0|254] "dB" XXX
 SG_ DAS_assPrevSetSpeed m9 : 8|8@1+ (0.25,0) [0|63.75] "m/s" XXX
 SG_ DAS_assNewSetSpeed m9 : 16|8@1+ (0.25,0) [0|63.75] "m/s" XXX
 SG_ DAS_assFusedSpeedLimit m9 : 24|6@1+ (1,0) [0|63] "m/s" XXX
 SG_ DAS_assAutosteerActive m9 : 30|1@1+ (1,0) [0|1] "" XXX
 SG_ DAS_assSmartSpeedActive m9 : 31|1@1+ (2,0) [0|1] "" XXX

BO_ 968 UI_driverAssistMapData: 8 XXX
 SG_ UI_mapSpeedLimitDependency : 0|3@1+ (1,0) [0|0] "" XXX
 SG_ UI_roadClass : 3|3@1+ (1,0) [0|0] "" XXX
 SG_ UI_inSuperchargerGeofence : 6|1@1+ (1,0) [0|0] "" XXX
 SG_ UI_mapSpeedUnits : 7|1@1+ (1,0) [0|0] "" XXX
 SG_ UI_mapSpeedLimit : 8|5@1+ (1,0) [0|0] "" XXX
 SG_ UI_mapSpeedLimitType : 13|3@1+ (1,0) [0|0] "" XXX
 SG_ UI_countryCode : 16|10@1+ (1,0) [0|0] "" XXX
 SG_ UI_streetCount : 26|2@1+ (1,0) [0|0] "" XXX
 SG_ UI_gpsRoadMatch : 28|1@1+ (1,0) [0|0] "" XXX
 SG_ UI_navRouteActive : 29|1@1+ (1,0) [0|0] "" XXX
 SG_ UI_parallelAutoparkEnabled : 30|1@1+ (1,0) [0|1] "" XXX
 SG_ UI_perpendicularAutoparkEnabled : 31|1@1+ (1,0) [0|1] "" XXX
 SG_ UI_nextBranchDist : 32|5@1+ (10,0) [0|300] "m" XXX
 SG_ UI_controlledAccess : 37|1@1+ (1,0) [0|0] "" XXX
 SG_ UI_nextBranchLeftOffRamp : 38|1@1+ (1,0) [0|0] "" XXX
 SG_ UI_nextBranchRightOffRamp : 39|1@1+ (1,0) [0|0] "" XXX
 SG_ UI_rejectLeftLane : 40|1@1+ (1,0) [0|0] "" XXX
 SG_ UI_rejectRightLane : 41|1@1+ (1,0) [0|0] "" XXX
 SG_ UI_rejectHPP : 42|1@1+ (1,0) [0|0] "" XXX
 SG_ UI_rejectNav : 43|1@1+ (1,0) [0|0] "" XXX
 SG_ UI_rejectLeftFreeSpace : 44|1@1+ (1,0) [0|0] "" XXX
 SG_ UI_rejectRightFreeSpace : 45|1@1+ (1,0) [0|0] "" XXX
 SG_ UI_rejectAutosteer : 46|1@1+ (1,0) [0|0] "" XXX
 SG_ UI_rejectHandsOn : 47|1@1+ (1,0) [0|0] "" XXX
 SG_ UI_acceptBottsDots : 48|1@1+ (1,0) [0|0] "" XXX
 SG_ UI_autosteerRestricted : 49|1@1+ (1,0) [0|0] "" XXX
 SG_ UI_pmmEnabled : 50|1@1+ (1,0) [0|0] "" XXX
 SG_ UI_scaEnabled : 51|1@1+ (1,0) [0|0] "" XXX
 SG_ UI_mapDataCounter : 52|4@1+ (1,0) [0|0] "" XXX
 SG_ UI_mapDataChecksum : 56|8@1+ (1,0) [0|0] "" XXX

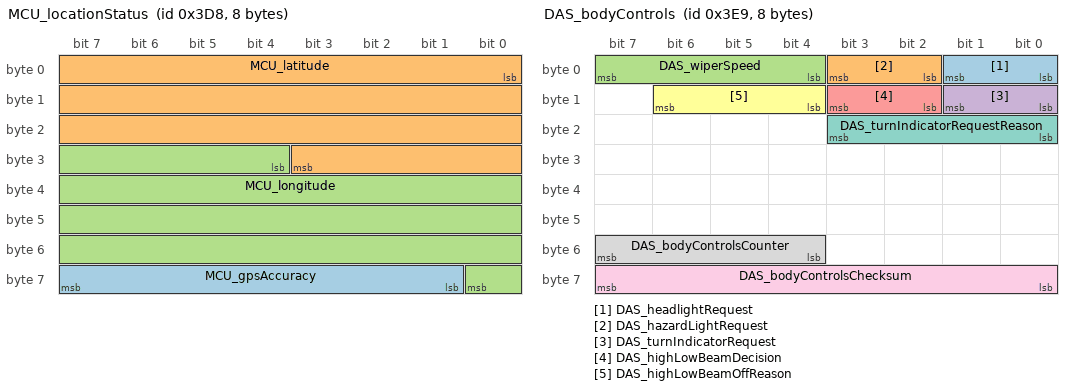
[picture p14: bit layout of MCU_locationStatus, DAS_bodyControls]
BO_ 984 MCU_locationStatus: 8 XXX
 SG_ MCU_gpsAccuracy : 57|7@1+ (0.2,0) [0|0] "m" XXX
 SG_ MCU_latitude : 0|28@1- (1E-06,0) [0|0] "deg" XXX
 SG_ MCU_longitude : 28|29@1- (1E-06,0) [0|0] "deg" XXX

BO_ 1000 UI_driverAssistControl: 8 XXX
 SG_ UI_autopilotControlRequest : 0|1@1+ (1,0) [1|0] "" XXX
 SG_ UI_ulcStalkConfirm : 1|1@1+ (1,0) [1|0] "" XXX
 SG_ UI_summonHeartbeat : 2|2@1+ (1,0) [0|0] "" XXX
 SG_ UI_curvSpeedAdaptDisable : 4|1@1+ (1,0) [0|0] "" XXX
 SG_ UI_dasDeveloper : 5|1@1+ (1,0) [0|0] "" XXX
 SG_ UI_enableVinAssociation : 6|1@1+ (1,0) [0|0] "" XXX
 SG_ UI_lssLkaEnabled : 7|1@1+ (1,0) [0|0] "" XXX
 SG_ UI_lssLdwEnabled : 8|1@1+ (1,0) [0|0] "" XXX
 SG_ UI_autoSummonEnable : 10|1@1+ (1,0) [0|1] "" XXX
 SG_ UI_exceptionListEnable : 11|1@1+ (1,0) [0|1] "" XXX
 SG_ UI_roadCheckDisable : 12|1@1+ (1,0) [0|0] "" XXX
 SG_ UI_driveOnMapsEnable : 13|1@1+ (1,0) [0|0] "" XXX
 SG_ UI_handsOnRequirementDisable : 14|1@1+ (1,0) [0|0] "" XXX
 SG_ UI_forksEnable : 15|1@1+ (1,0) [0|0] "" XXX
 SG_ UI_fuseLanesDisable : 16|1@1+ (1,0) [0|0] "" XXX
 SG_ UI_fuseHPPDisable : 17|1@1+ (1,0) [0|0] "" XXX
 SG_ UI_fuseVehiclesDisable : 18|1@1+ (1,0) [0|0] "" XXX
 SG_ UI_enableNextGenACC : 19|1@1+ (1,0) [0|1] "" XXX
 SG_ UI_visionSpeedType : 20|2@1+ (1,0) [0|0] "" XXX
 SG_ UI_curvatureDatabaseOnly : 22|1@1+ (1,0) [0|0] "" XXX
 SG_ UI_lssElkEnabled : 23|1@1+ (1,0) [0|0] "" XXX
 SG_ UI_summonExitType : 24|2@1+ (1,0) [0|3] "" XXX
 SG_ UI_summonEntryType : 26|2@1+ (1,0) [0|3] "" XXX
 SG_ UI_selfParkRequest : 28|4@1+ (1,0) [0|15] "" XXX
 SG_ UI_summonReverseDist : 32|6@1+ (1,0) [0|63] "" XXX
 SG_ UI_undertakeAssistEnable : 38|1@1+ (1,0) [0|0] "" XXX
 SG_ UI_adaptiveSetSpeedEnable : 39|1@1+ (1,0) [0|0] "" XXX
 SG_ UI_drivingSide : 40|2@1+ (1,0) [0|3] "" XXX
 SG_ UI_enableClipTelemetry : 42|1@1+ (1,0) [0|0] "" XXX
 SG_ UI_enableTripTelemetry : 43|1@1+ (1,0) [0|0] "" XXX
 SG_ UI_enableRoadSegmentTelemetry : 44|1@1+ (1,0) [0|0] "" XXX
 SG_ UI_followNavRouteEnable : 46|1@1+ (1,0) [0|0] "" XXX
 SG_ UI_ulcSpeedConfig : 48|2@1+ (1,0) [0|3] "" XXX
 SG_ UI_ulcBlindSpotConfig : 50|2@1+ (1,0) [0|3] "" XXX
 SG_ UI_autopilotAlwaysOn : 52|1@1+ (1,0) [0|1] "" XXX
 SG_ UI_accFromZero : 53|1@1+ (1,0) [0|1] "" XXX
 SG_ UI_alcOffHighwayEnable : 54|1@1+ (1,0) [0|1] "" XXX
 SG_ UI_validationLoop : 55|1@1+ (1,0) [0|1] "" XXX
 SG_ UI_ulcOffHighway : 56|1@1+ (1,0) [0|1] "" XXX
 SG_ UI_enableNavRouteCSA : 57|1@1+ (1,0) [0|1] "" XXX
 SG_ UI_enableCutinExperiments : 58|1@1+ (1,0) [0|1] "" XXX
 SG_ UI_source3D : 60|3@1+ (1,0) [0|7] "" XXX
 SG_ UI_enableVisionOnlyStops : 63|1@1+ (1,0) [0|1] "" XXX

BO_ 1001 DAS_bodyControls: 8 XXX
 SG_ DAS_headlightRequest : 0|2@1+ (1,0) [0|3] "" XXX
 SG_ DAS_hazardLightRequest : 2|2@1+ (1,0) [0|3] "" XXX
 SG_ DAS_wiperSpeed : 4|4@1+ (1,0) [0|15] "" XXX
 SG_ DAS_turnIndicatorRequest : 8|2@1+ (1,0) [0|3] "" XXX
 SG_ DAS_highLowBeamDecision : 10|2@1+ (1,0) [0|3] "" XXX
 SG_ DAS_highLowBeamOffReason : 12|3@1+ (1,0) [0|4] "" XXX
 SG_ DAS_turnIndicatorRequestReason : 16|4@1+ (1,0) [0|15] "" XXX
 SG_ DAS_bodyControlsCounter : 52|4@1+ (1,0) [0|15] "" XXX
 SG_ DAS_bodyControlsChecksum : 56|8@1+ (1,0) [0|255] "" XXX

BO_ 1006 UI_autopilotControl: 8 XXX
 SG_ UI_autopilotControlIndex M : 0|3@1+ (1,0) [0|7] "" XXX
 SG_ UI_hovEnabled m0 : 3|1@1+ (1,0) [0|0] "" XXX
 SG_ UI_donDisableAutoWiperDuration m0 : 4|3@1+ (1,0) [0|0] "" XXX
 SG_ UI_donDisableOnAutoWiperSpeed m0 : 7|4@1+ (1,0) [0|0] "" XXX
 SG_ UI_blindspotMinSpeed m0 : 11|4@1+ (1,0) [0|0] "" XXX
 SG_ UI_blindspotDistance m0 : 15|3@1+ (1,0) [0|0] "" XXX
 SG_ UI_blindspotTTC m0 : 18|3@1+ (1,0) [0|0] "" XXX
 SG_ UI_donStopEndOfRampBuffer m0 : 21|3@1+ (1,0) [0|0] "" XXX
 SG_ UI_donDisableCutin m0 : 24|1@1+ (1,0) [0|0] "" XXX
 SG_ UI_donMinGoreWidthForAbortMap m0 : 25|4@1+ (1,0) [0|0] "" XXX
 SG_ UI_donAlcProgGoreAbortThres m0 : 29|4@1+ (1,0) [0|0] "" XXX
 SG_ UI_donMinGoreWidthForAbortNotMap m0 : 33|4@1+ (1,0) [0|0] "" XXX
 SG_ UI_alcDisableUltrasonicCheck m0 : 37|1@1+ (1,0) [0|0] "" XXX
 SG_ UI_alcUltrasonicDistance m0 : 38|4@1+ (1,0) [0|0] "" XXX
 SG_ UI_alcUltrasonicWaitTime m0 : 42|3@1+ (1,0) [0|0] "" XXX
 SG_ UI_alcEgoLeadingReactionAccel m0 : 48|2@1+ (1,0) [0|0] "" XXX
 SG_ UI_alcMergIntervalRearDHyst m0 : 50|2@1+ (1,0) [0|0] "" XXX
 SG_ UI_alcMergingIntervalHeadwayHyst m0 : 52|2@1+ (1,0) [0|0] "" XXX
 SG_ UI_alcAssertivenessRate m0 : 54|2@1+ (1,0) [0|0] "" XXX
 SG_ UI_alcViewRangeSensitivity m0 : 56|2@1+ (1,0) [0|0] "" XXX
 SG_ UI_camBlockLaneCheckDisable m1 : 3|1@1+ (1,0) [0|0] "" XXX
 SG_ UI_camBlockLaneCheckThreshold m1 : 4|6@1+ (0.01587,0) [0|1] "%" XXX
 SG_ UI_camBlockBlurDisable m1 : 10|1@1+ (1,0) [0|0] "" XXX
 SG_ UI_camBlockBlurThreshold m1 : 11|6@1+ (0.01587,0) [0|1] "%" XXX

BO_ 1064 UI_telemetryControl: 8 XXX
 SG_ UI_TCR_enable : 0|1@1+ (1,0) [0|0] "" XXX
 SG_ UI_TCR_moveStateStanding : 1|1@1+ (1,0) [0|0] "" XXX
 SG_ UI_TCR_moveStateStopped : 2|1@1+ (1,0) [0|0] "" XXX
 SG_ UI_TCR_moveStateMoving : 3|1@1+ (1,0) [0|0] "" XXX
 SG_ UI_TCR_moveStateIndeterm : 4|1@1+ (1,0) [0|0] "" XXX
 SG_ UI_TCR_classConstElem : 5|1@1+ (1,0) [0|0] "" XXX
 SG_ UI_TCR_classMovingPed : 6|1@1+ (1,0) [0|0] "" XXX
 SG_ UI_TCR_classMovingTwoWheel : 7|1@1+ (1,0) [0|0] "" XXX
 SG_ UI_TCR_classMovingFourWheel : 8|1@1+ (1,0) [0|0] "" XXX
 SG_ UI_TCR_classUnknown : 9|1@1+ (1,0) [0|0] "" XXX
 SG_ UI_TCR_downSampleFactor : 16|4@1+ (1,0) [0|15] "" Vector__XXX
 SG_ UI_TCR_wExist : 24|5@1+ (1,0) [0|31] "" Vector__XXX
 SG_ UI_TCR_vehSpeed : 32|8@1+ (1,0) [0|0] "" Vector__XXX
 SG_ UI_TCR_minRCS : 40|8@1+ (0.25,-14) [-14|49.75] "dB" Vector__XXX
 SG_ UI_TCR_maxDy : 48|5@1+ (0.5,0) [0|15.5] "m" Vector__XXX
 SG_ UI_TCR_maxObjects : 56|5@1+ (1,0) [0|31] "" Vector__XXX
 SG_ UI_TCR_maxRoadClass : 61|3@1+ (1,0) [0|7] "" Vector__XXX

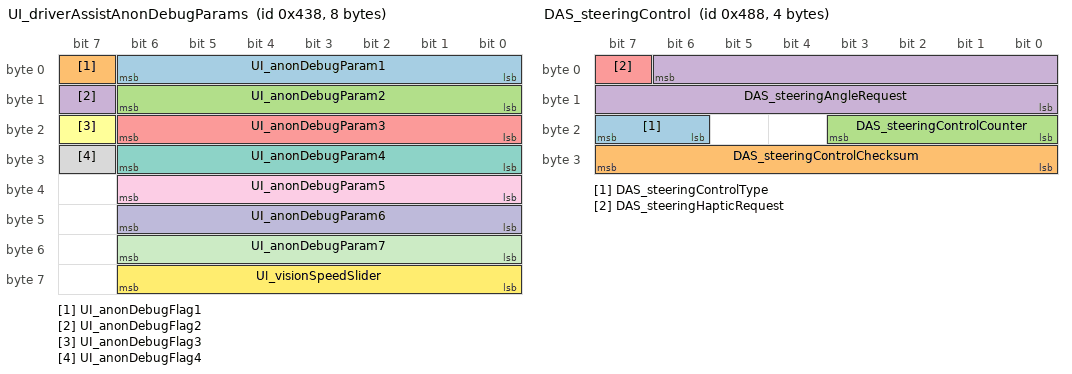
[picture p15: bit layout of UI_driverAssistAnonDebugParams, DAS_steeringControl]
BO_ 1080 UI_driverAssistAnonDebugParams: 8 XXX
 SG_ UI_anonDebugParam1 : 0|7@1+ (1,0) [0|100] "" XXX
 SG_ UI_anonDebugFlag1 : 7|1@1+ (1,0) [0|0] "" XXX
 SG_ UI_anonDebugParam2 : 8|7@1+ (1,0) [0|100] "" XXX
 SG_ UI_anonDebugFlag2 : 15|1@1+ (1,0) [0|0] "" XXX
 SG_ UI_anonDebugParam3 : 16|7@1+ (1,0) [0|100] "" XXX
 SG_ UI_anonDebugFlag3 : 23|1@1+ (1,0) [0|0] "" XXX
 SG_ UI_anonDebugParam4 : 24|7@1+ (1,0) [0|100] "" XXX
 SG_ UI_anonDebugFlag4 : 31|1@1+ (1,0) [0|0] "" XXX
 SG_ UI_anonDebugParam5 : 32|7@1+ (1,0) [0|100] "" XXX
 SG_ UI_anonDebugParam6 : 40|7@1+ (1,0) [0|100] "" XXX
 SG_ UI_anonDebugParam7 : 48|7@1+ (1,0) [0|100] "" XXX
 SG_ UI_visionSpeedSlider : 56|7@1+ (1,0) [0|100] "" XXX

BO_ 1160 DAS_steeringControl: 4 NEO
 SG_ DAS_steeringControlType : 23|2@0+ (1,0) [0|0] "" EPAS
 SG_ DAS_steeringControlChecksum : 31|8@0+ (1,0) [0|0] "" EPAS
 SG_ DAS_steeringControlCounter : 19|4@0+ (1,0) [0|0] "" EPAS
 SG_ DAS_steeringAngleRequest : 6|15@0+ (0.1,-1638.35) [-1638.35|1638.35] "deg" EPAS
 SG_ DAS_steeringHapticRequest : 7|1@0+ (1,0) [0|0] "" EPAS

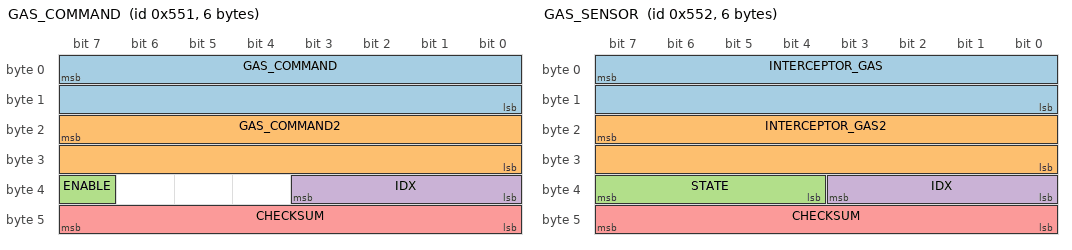
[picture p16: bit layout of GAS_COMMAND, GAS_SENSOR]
BO_ 1361 GAS_COMMAND: 6 EON
 SG_ GAS_COMMAND : 7|16@0+ (0.0507968128,-22.85856576) [0|1] "" INTERCEPTOR
 SG_ GAS_COMMAND2 : 23|16@0+ (0.1015936256,-22.85856576) [0|1] "" INTERCEPTOR
 SG_ ENABLE : 39|1@0+ (1,0) [0|1] "" INTERCEPTOR
 SG_ IDX : 35|4@0+ (1,0) [0|15] "" INTERCEPTOR
 SG_ CHECKSUM : 47|8@0+ (1,0) [0|3] "" INTERCEPTOR

BO_ 1362 GAS_SENSOR: 6 INTERCEPTOR
 SG_ INTERCEPTOR_GAS : 7|16@0+ (0.0507968128,-22.85856576) [0|1] "" EON
 SG_ INTERCEPTOR_GAS2 : 23|16@0+ (0.1015936256,-22.85856576) [0|1] "" EON
 SG_ STATE : 39|4@0+ (1,0) [0|15] "" EON
 SG_ IDX : 35|4@0+ (1,0) [0|15] "" EON
 SG_ CHECKSUM : 47|8@0+ (1,0) [0|3] "" EON

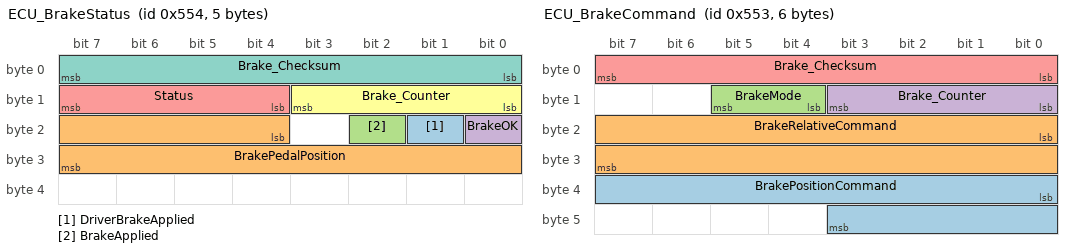
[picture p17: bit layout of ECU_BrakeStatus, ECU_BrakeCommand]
BO_ 1364 ECU_BrakeStatus: 5 iBooster
 SG_ DriverBrakeApplied : 17|1@1+ (1,0) [0|1] ""  EON
 SG_ BrakePedalPosition : 20|12@1+ (0.015625,-5) [0|47] "mm"  EON
 SG_ BrakeApplied : 18|1@1+ (1,0) [0|1] ""  EON
 SG_ BrakeOK : 16|1@1+ (1,0) [0|1] ""  EON
 SG_ Status : 12|4@1+ (1,0) [0|15] ""  EON
 SG_ Brake_Counter : 8|4@1+ (1,0) [0|15] ""  EON
 SG_ Brake_Checksum : 0|8@1+ (1,0) [0|255] ""  EON

BO_ 1363 ECU_BrakeCommand: 6 EON
 SG_ BrakePositionCommand : 32|12@1+ (0.015625,-5) [0|20] "mm"  iBooster
 SG_ BrakeRelativeCommand : 16|16@1+ (0.0078125,-252) [-252|252] "ml/s"  iBooster
 SG_ BrakeMode : 12|2@1+ (1,0) [0|3] ""  iBooster
 SG_ Brake_Counter : 8|4@1+ (1,0) [0|15] ""  iBooster
 SG_ Brake_Checksum : 0|8@1+ (1,0) [0|255] ""  iBooster

BO_ 1365 IVS_Command: 6 EON
 SG_ IvsCounter : 8|4@1+ (1,0) [0|15] ""  IVS
 SG_ IvsChecksum : 0|8@1+ (1,0) [0|255] ""  IVS

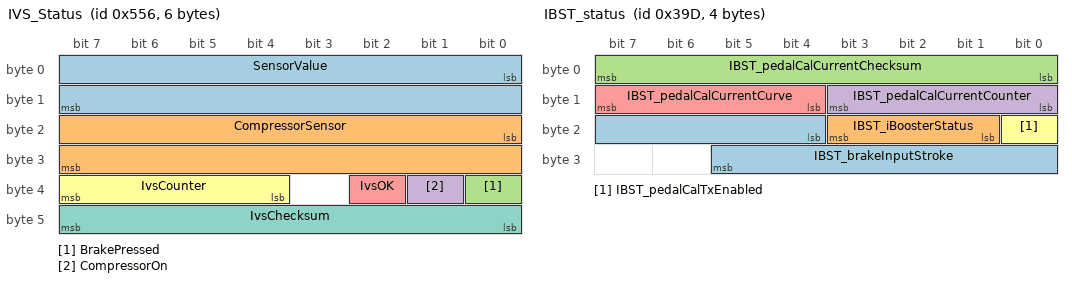
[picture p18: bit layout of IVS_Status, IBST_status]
BO_ 1366 IVS_Status: 6 IVS
 SG_ SensorValue : 0|16@1+ (0.001604107,0) [0|5] "V" EON
 SG_ CompressorSensor : 16|16@1+ (0.001604107,0) [0|5] "V" EON
 SG_ BrakePressed : 32|1@1+ (1,0) [0|1] "" EON
 SG_ CompressorOn : 33|1@1+ (1,0) [0|1] "" EON
 SG_ IvsOK : 34|1@1+ (1,0) [0|1] "" EON
 SG_ IvsCounter : 36|4@1+ (1,0) [0|15] "" EON
 SG_ IvsChecksum : 40|8@1+ (1,0) [0|3] "" EON

BO_ 861 IBST_dtcMatrix: 4 iBooster
 SG_ IBST_dtcIndex M : 0|8@1+ (1,0) [0|0] "" Vector__XXX
 SG_ IBST_d000_bmsInitTestFail m0 : 8|2@1+ (1,0) [0|0] "" Vector__XXX
 SG_ IBST_d001_bmcSingleTransTest m0 : 10|2@1+ (1,0) [0|0] "" Vector__XXX
 SG_ IBST_d002_tle5012SsccrcFail m0 : 12|2@1+ (1,0) [0|0] "" Vector__XXX
 SG_ IBST_d003_tle5012Config m0 : 14|2@1+ (1,0) [0|0] "" Vector__XXX
 SG_ IBST_d004_deadlMonTaskx1Ovr m0 : 16|2@1+ (1,0) [0|0] "" Vector__XXX
 SG_ IBST_d005_ecuWdFltCntTstFls m0 : 18|2@1+ (1,0) [0|0] "" Vector__XXX
 SG_ IBST_d006_ecuWdScheduleTout m0 : 20|2@1+ (1,0) [0|0] "" Vector__XXX
 SG_ IBST_d007_ecuWdStarttestFls m0 : 22|2@1+ (1,0) [0|0] "" Vector__XXX
 SG_ IBST_d008_ecuWdStatusContErr m0 : 24|2@1+ (1,0) [0|0] "" Vector__XXX
 SG_ IBST_d009_netOvrvolt m0 : 26|2@1+ (1,0) [0|0] "" Vector__XXX
 SG_ IBST_d010_micSpiTout m0 : 28|2@1+ (1,0) [0|0] "" Vector__XXX
 SG_ IBST_d011_micSpiTransferErr m0 : 30|2@1+ (1,0) [0|0] "" Vector__XXX
 SG_ IBST_d012_netUndvolt m0 : 32|2@1+ (1,0) [0|0] "" Vector__XXX
 SG_ IBST_d013_xpassToutErr m0 : 34|2@1+ (1,0) [0|0] "" Vector__XXX
 SG_ IBST_d014_rpsOffsEeReadEmpty m0 : 36|2@1+ (1,0) [0|0] "" Vector__XXX
 SG_ IBST_d015_rtpEnaHigh m0 : 38|2@1+ (1,0) [0|0] "" Vector__XXX
 SG_ IBST_d016_xpassEchoCountErr m0 : 40|2@1+ (1,0) [0|0] "" Vector__XXX
 SG_ IBST_d017_preDriveChckFail m0 : 42|2@1+ (1,0) [0|0] "" Vector__XXX
 SG_ IBST_d018_ucSafetyFlt m0 : 44|2@1+ (1,0) [0|0] "" Vector__XXX
 SG_ IBST_d019_unsupportedHw m0 : 46|2@1+ (1,0) [0|0] "" Vector__XXX
 SG_ IBST_d020_voltPreRegModeFld m0 : 48|2@1+ (1,0) [0|0] "" Vector__XXX
 SG_ IBST_d021_ubbSupplyLine m0 : 50|2@1+ (1,0) [0|0] "" Vector__XXX
 SG_ IBST_d022_stmAswSysTout m0 : 52|2@1+ (1,0) [0|0] "" Vector__XXX
 SG_ IBST_d023_stackOvrUndFlow m0 : 54|2@1+ (1,0) [0|0] "" Vector__XXX
 SG_ IBST_d024_smmOneReqsInit m0 : 56|2@1+ (1,0) [0|0] "" Vector__XXX
 SG_ IBST_d025_ptsSupply m0 : 58|2@1+ (1,0) [0|0] "" Vector__XXX
 SG_ IBST_d026_ptsSupplyUndvolt m0 : 60|2@1+ (1,0) [0|0] "" Vector__XXX
 SG_ IBST_d027_tempB6Plaus m0 : 62|2@1+ (1,0) [0|0] "" Vector__XXX
 SG_ IBST_d028_ecuWdErrCntContErr m1 : 8|2@1+ (1,0) [0|0] "" Vector__XXX
 SG_ IBST_d029_bmcShortedGateTest m1 : 10|2@1+ (1,0) [0|0] "" Vector__XXX
 SG_ IBST_d030_controllerDevTooBig m1 : 12|2@1+ (1,0) [0|0] "" Vector__XXX
 SG_ IBST_d031_ibDtrFail m1 : 14|2@1+ (1,0) [0|0] "" Vector__XXX
 SG_ IBST_d032_oc6InitTestFail m1 : 16|2@1+ (1,0) [0|0] "" Vector__XXX
 SG_ IBST_d033_oc6Monitor m1 : 18|2@1+ (1,0) [0|0] "" Vector__XXX
 SG_ IBST_d034_motorOscillationDet m1 : 20|2@1+ (1,0) [0|0] "" Vector__XXX
 SG_ IBST_d035_rpsOffsEeReadFail m1 : 22|2@1+ (1,0) [0|0] "" Vector__XXX
 SG_ IBST_d036_sysErrHook m1 : 24|2@1+ (1,0) [0|0] "" Vector__XXX
 SG_ IBST_d037_calIdlePosNotPlaus m1 : 26|2@1+ (1,0) [0|0] "" Vector__XXX
 SG_ IBST_d038_boostSupUndrvolt m1 : 28|2@1+ (1,0) [0|0] "" Vector__XXX
 SG_ IBST_d039_calRoutineAbort m1 : 30|2@1+ (1,0) [0|0] "" Vector__XXX
 SG_ IBST_d040_bmcGateUndervoltPro m1 : 32|2@1+ (1,0) [0|0] "" Vector__XXX
 SG_ IBST_d041_hswInitPhseUndrvolt m1 : 34|2@1+ (1,0) [0|0] "" Vector__XXX
 SG_ IBST_d042_ltmWarnLevelReached m1 : 36|2@1+ (1,0) [0|0] "" Vector__XXX
 SG_ IBST_d043_rpsVctrLengthRelErr m1 : 38|2@1+ (1,0) [0|0] "" Vector__XXX
 SG_ IBST_d044_b6TempDegradeLevel1 m1 : 40|2@1+ (1,0) [0|0] "" Vector__XXX
 SG_ IBST_d045_B6TempDegradeLevel2 m1 : 42|2@1+ (1,0) [0|0] "" Vector__XXX
 SG_ IBST_d046_spiAnglOrRawNotUp m1 : 44|2@1+ (1,0) [0|0] "" Vector__XXX
 SG_ IBST_d047_dcomIboosterNotInit m1 : 46|2@1+ (1,0) [0|0] "" Vector__XXX
 SG_ IBST_d048_unintendMotorReturn m1 : 48|2@1+ (1,0) [0|0] "" Vector__XXX
 SG_ IBST_d049_cdmOvrvoltLevel1 m1 : 50|2@1+ (1,0) [0|0] "" Vector__XXX
 SG_ IBST_d050_cdmUndrvoltLevel2 m1 : 52|2@1+ (1,0) [0|0] "" Vector__XXX
 SG_ IBST_d051_cdmUndrvoltLevel1 m1 : 54|2@1+ (1,0) [0|0] "" Vector__XXX
 SG_ IBST_d052_motTrvlRelReadFail m1 : 56|2@1+ (1,0) [0|0] "" Vector__XXX
 SG_ IBST_d053_tle5012UnexpReset m1 : 58|2@1+ (1,0) [0|0] "" Vector__XXX
 SG_ IBST_d054_bmsGateUndrvolt m1 : 60|2@1+ (1,0) [0|0] "" Vector__XXX
 SG_ IBST_d055_kl15HwPlausSw m1 : 62|2@1+ (1,0) [0|0] "" Vector__XXX
 SG_ IBST_d056_ibNotShutDownRight m2 : 8|2@1+ (1,0) [0|0] "" Vector__XXX
 SG_ IBST_d057_cdmHardUndrvolt m2 : 10|2@1+ (1,0) [0|0] "" Vector__XXX
 SG_ IBST_d058_cdmHardOvrvolt m2 : 12|2@1+ (1,0) [0|0] "" Vector__XXX
 SG_ IBST_d059_maxTrvlAdjstUpdFail m2 : 14|2@1+ (1,0) [0|0] "" Vector__XXX
 SG_ IBST_d060_ltmLimitReached m2 : 16|2@1+ (1,0) [0|0] "" Vector__XXX
 SG_ IBST_d061_dcomEcuDefect m2 : 18|2@1+ (1,0) [0|0] "" Vector__XXX
 SG_ IBST_d062_inputStroke1RngHigh m2 : 20|2@1+ (1,0) [0|0] "" Vector__XXX
 SG_ IBST_d063_inputStroke1RngLow m2 : 22|2@1+ (1,0) [0|0] "" Vector__XXX
 SG_ IBST_d064_inputStroke2RngHigh m2 : 24|2@1+ (1,0) [0|0] "" Vector__XXX
 SG_ IBST_d065_inputStroke2RngLow m2 : 26|2@1+ (1,0) [0|0] "" Vector__XXX
 SG_ IBST_d066_ibSupVoltDivDrift m2 : 28|2@1+ (1,0) [0|0] "" Vector__XXX
 SG_ IBST_d067_sOutRodToPressVal m2 : 30|2@1+ (1,0) [0|0] "" Vector__XXX
 SG_ IBST_d068_tle5012LifeCnt m2 : 32|2@1+ (1,0) [0|0] "" Vector__XXX
 SG_ IBST_d069_cdmExtendedUndrvolt m2 : 34|2@1+ (1,0) [0|0] "" Vector__XXX
 SG_ IBST_d070_cdmExtendedOvrvolt m2 : 36|2@1+ (1,0) [0|0] "" Vector__XXX
 SG_ IBST_d071_tempB6Ch1LineHigh m2 : 38|2@1+ (1,0) [0|0] "" Vector__XXX
 SG_ IBST_d072_tempB6Ch1LineLow m2 : 40|2@1+ (1,0) [0|0] "" Vector__XXX
 SG_ IBST_d073_tempB6Ch2LineHigh m2 : 42|2@1+ (1,0) [0|0] "" Vector__XXX
 SG_ IBST_d074_tempB6Ch2LineLow m2 : 44|2@1+ (1,0) [0|0] "" Vector__XXX
 SG_ IBST_d075_hevSwitchOffDcom m2 : 46|2@1+ (1,0) [0|0] "" Vector__XXX
 SG_ IBST_d076_tle5012VoltFail m2 : 48|2@1+ (1,0) [0|0] "" Vector__XXX
 SG_ IBST_d077_bcsFltCurrentHigh m2 : 50|2@1+ (1,0) [0|0] "" Vector__XXX
 SG_ IBST_d078_bcsFltCurrentLow m2 : 52|2@1+ (1,0) [0|0] "" Vector__XXX
 SG_ IBST_d079_ecuSupVoltDivDrift m2 : 54|2@1+ (1,0) [0|0] "" Vector__XXX
 SG_ IBST_d080_inputstroke1Grad m2 : 56|2@1+ (1,0) [0|0] "" Vector__XXX
 SG_ IBST_d081_pts1Err m2 : 58|2@1+ (1,0) [0|0] "" Vector__XXX
 SG_ IBST_d082_pts1LineGnd m2 : 60|2@1+ (1,0) [0|0] "" Vector__XXX
 SG_ IBST_d083_pts1LineHigh m2 : 62|2@1+ (1,0) [0|0] "" Vector__XXX
 SG_ IBST_d084_inputStroke2Grad m3 : 8|2@1+ (1,0) [0|0] "" Vector__XXX
 SG_ IBST_d085_pts2Err m3 : 10|2@1+ (1,0) [0|0] "" Vector__XXX
 SG_ IBST_d086_pts2LineGnd m3 : 12|2@1+ (1,0) [0|0] "" Vector__XXX
 SG_ IBST_d087_pts2LineHigh m3 : 14|2@1+ (1,0) [0|0] "" Vector__XXX
 SG_ IBST_d088_faildevInputStroke m3 : 16|2@1+ (1,0) [0|0] "" Vector__XXX
 SG_ IBST_d089_ptsOffsTooHigh m3 : 18|2@1+ (1,0) [0|0] "" Vector__XXX
 SG_ IBST_d090_pbistErr m3 : 20|2@1+ (1,0) [0|0] "" Vector__XXX
 SG_ IBST_d091_ramInitErr m3 : 22|2@1+ (1,0) [0|0] "" Vector__XXX
 SG_ IBST_d092_ramsinlgeFlt m3 : 24|2@1+ (1,0) [0|0] "" Vector__XXX
 SG_ IBST_d093_bertFlt m3 : 26|2@1+ (1,0) [0|0] "" Vector__XXX
 SG_ IBST_d094_CalDataNotPlaus m3 : 28|2@1+ (1,0) [0|0] "" Vector__XXX
 SG_ IBST_d095_canEHwError m3 : 30|2@1+ (1,0) [0|0] "" Vector__XXX
 SG_ IBST_d096_canETout m3 : 32|2@1+ (1,0) [0|0] "" Vector__XXX
 SG_ IBST_d097_cpuException m3 : 34|2@1+ (1,0) [0|0] "" Vector__XXX
 SG_ IBST_d098_ecuBandGap m3 : 36|2@1+ (1,0) [0|0] "" Vector__XXX
 SG_ IBST_d099_ecuBmsOnWhileWdTout m3 : 38|2@1+ (1,0) [0|0] "" Vector__XXX
 SG_ IBST_d100_ecuErrpinCntTstFls m3 : 40|2@1+ (1,0) [0|0] "" Vector__XXX
 SG_ IBST_d101_ecuHetException m3 : 42|2@1+ (1,0) [0|0] "" Vector__XXX
 SG_ IBST_d102_ecuHetTuAddErr m3 : 44|2@1+ (1,0) [0|0] "" Vector__XXX
 SG_ IBST_d103_ecuHetTuBusErr m3 : 46|2@1+ (1,0) [0|0] "" Vector__XXX
 SG_ IBST_d104_ecuHetTuBusyErr m3 : 48|2@1+ (1,0) [0|0] "" Vector__XXX
 SG_ IBST_d105_ecuHetTuException m3 : 50|2@1+ (1,0) [0|0] "" Vector__XXX
 SG_ IBST_d106_ecuTaskMissing m3 : 52|2@1+ (1,0) [0|0] "" Vector__XXX
 SG_ IBST_d107_hetRefError m3 : 54|2@1+ (1,0) [0|0] "" Vector__XXX
 SG_ IBST_d108_micInitSpiTstFld m3 : 56|2@1+ (1,0) [0|0] "" Vector__XXX
 SG_ IBST_d109_micInitSpiTransfErr m3 : 58|2@1+ (1,0) [0|0] "" Vector__XXX
 SG_ IBST_d110_micIntMonGenBitMon m3 : 60|2@1+ (1,0) [0|0] "" Vector__XXX
 SG_ IBST_d111_micIntVoltMonFld m3 : 62|2@1+ (1,0) [0|0] "" Vector__XXX
 SG_ IBST_d112_motPosTrvlReadEmpty m4 : 8|2@1+ (1,0) [0|0] "" Vector__XXX
 SG_ IBST_d113_motAngBoundReadEmpt m4 : 10|2@1+ (1,0) [0|0] "" Vector__XXX
 SG_ IBST_d114_motShaftShiftDetect m4 : 12|2@1+ (1,0) [0|0] "" Vector__XXX
 SG_ IBST_d115_osErrHook m4 : 14|2@1+ (1,0) [0|0] "" Vector__XXX
 SG_ IBST_d116_pdurEInitFail m4 : 16|2@1+ (1,0) [0|0] "" Vector__XXX
 SG_ IBST_d117_pdurEPduInstLost m4 : 18|2@1+ (1,0) [0|0] "" Vector__XXX
 SG_ IBST_d118_pts1OffsEeReadEmpty m4 : 20|2@1+ (1,0) [0|0] "" Vector__XXX
 SG_ IBST_d119_pts2OffsEeReadEmpty m4 : 22|2@1+ (1,0) [0|0] "" Vector__XXX
 SG_ IBST_d120_rpsOffsXEeReadFail m4 : 24|2@1+ (1,0) [0|0] "" Vector__XXX
 SG_ IBST_d121_rpsOffsYEeReadFail m4 : 26|2@1+ (1,0) [0|0] "" Vector__XXX
 SG_ IBST_d122_rpsSynchEeReadFail m4 : 28|2@1+ (1,0) [0|0] "" Vector__XXX
 SG_ IBST_d123_rpsAnglRecalcErr m4 : 30|2@1+ (1,0) [0|0] "" Vector__XXX
 SG_ IBST_d124_motTrvlRelWriteFail m4 : 32|2@1+ (1,0) [0|0] "" Vector__XXX
 SG_ IBST_d125_motTrvlRelReadEmpty m4 : 34|2@1+ (1,0) [0|0] "" Vector__XXX
 SG_ IBST_d126_ptsEeReadEmpty m4 : 36|2@1+ (1,0) [0|0] "" Vector__XXX
 SG_ IBST_d127_ecuAdcConversionErr m4 : 38|2@1+ (1,0) [0|0] "" Vector__XXX
 SG_ IBST_d128_ecuAdcSelftestErr m4 : 40|2@1+ (1,0) [0|0] "" Vector__XXX
 SG_ IBST_d129_ccmFlt m4 : 42|2@1+ (1,0) [0|0] "" Vector__XXX
 SG_ IBST_d130_ecuRomCheck m4 : 44|2@1+ (1,0) [0|0] "" Vector__XXX
 SG_ IBST_d131_esmNmiFlt m4 : 46|2@1+ (1,0) [0|0] "" Vector__XXX
 SG_ IBST_d132_esmSafetyFlt m4 : 48|2@1+ (1,0) [0|0] "" Vector__XXX
 SG_ IBST_d133_motPosTrvlReadFail m4 : 50|2@1+ (1,0) [0|0] "" Vector__XXX
 SG_ IBST_d134_motPosTrvlWriteFail m4 : 52|2@1+ (1,0) [0|0] "" Vector__XXX
 SG_ IBST_d135_motAnglBndReadErr m4 : 54|2@1+ (1,0) [0|0] "" Vector__XXX
 SG_ IBST_d136_motAnglBndWriteErr m4 : 56|2@1+ (1,0) [0|0] "" Vector__XXX
 SG_ IBST_d137_motAnglGradTooLarge m4 : 58|2@1+ (1,0) [0|0] "" Vector__XXX
 SG_ IBST_d138_pdmCustomerIdMis m4 : 60|2@1+ (1,0) [0|0] "" Vector__XXX
 SG_ IBST_d139_pdmDtFormatMis m4 : 62|2@1+ (1,0) [0|0] "" Vector__XXX
 SG_ IBST_d140_pdmOutOfMemory m5 : 8|2@1+ (1,0) [0|0] "" Vector__XXX
 SG_ IBST_d141_pdmFieldSizeMis m5 : 10|2@1+ (1,0) [0|0] "" Vector__XXX
 SG_ IBST_d142_pdmHwAcsErr m5 : 12|2@1+ (1,0) [0|0] "" Vector__XXX
 SG_ IBST_d143_pdmInternalHWErr m5 : 14|2@1+ (1,0) [0|0] "" Vector__XXX
 SG_ IBST_d144_ptsCalHysWritFail m5 : 16|2@1+ (1,0) [0|0] "" Vector__XXX
 SG_ IBST_d145_ptsCalValuesChkFail m5 : 18|2@1+ (1,0) [0|0] "" Vector__XXX
 SG_ IBST_d146_pts1CalEeReadFail m5 : 20|2@1+ (1,0) [0|0] "" Vector__XXX
 SG_ IBST_d147_pts1CalEeWriteFail m5 : 22|2@1+ (1,0) [0|0] "" Vector__XXX
 SG_ IBST_d148_rpsFailCompErr m5 : 24|2@1+ (1,0) [0|0] "" Vector__XXX
 SG_ IBST_d149_pts1OffsEeWriteFail m5 : 26|2@1+ (1,0) [0|0] "" Vector__XXX
 SG_ IBST_d150_pts2CalEeReadFail m5 : 28|2@1+ (1,0) [0|0] "" Vector__XXX
 SG_ IBST_d151_pts2CalEeWriteFail m5 : 30|2@1+ (1,0) [0|0] "" Vector__XXX
 SG_ IBST_d152_pts2OffsEeReadFail m5 : 32|2@1+ (1,0) [0|0] "" Vector__XXX
 SG_ IBST_d153_pts2OffsEeWriteFail m5 : 34|2@1+ (1,0) [0|0] "" Vector__XXX
 SG_ IBST_d154_rpsOffsXEeReadEmpty m5 : 36|2@1+ (1,0) [0|0] "" Vector__XXX
 SG_ IBST_d155_rpsOffsXEeWriteFail m5 : 38|2@1+ (1,0) [0|0] "" Vector__XXX
 SG_ IBST_d156_rpsOffsYEeReadEmpty m5 : 40|2@1+ (1,0) [0|0] "" Vector__XXX
 SG_ IBST_d157_rpsOffsYEeWriteFail m5 : 42|2@1+ (1,0) [0|0] "" Vector__XXX
 SG_ IBST_d158_rpsSynchEeReadEmpty m5 : 44|2@1+ (1,0) [0|0] "" Vector__XXX
 SG_ IBST_d159_rpsSynchEeWriteFail m5 : 46|2@1+ (1,0) [0|0] "" Vector__XXX
 SG_ IBST_d160_assertionFail m5 : 48|2@1+ (1,0) [0|0] "" Vector__XXX
 SG_ IBST_d161_comsclBrkPrsPduLen m5 : 50|2@1+ (1,0) [0|0] "" Vector__XXX
 SG_ IBST_d162_comsclBrkPrsPduTout m5 : 52|2@1+ (1,0) [0|0] "" Vector__XXX
 SG_ IBST_d163_comsclEspIb1CntErr m5 : 54|2@1+ (1,0) [0|0] "" Vector__XXX
 SG_ IBST_d164_comsclEspIb1CsErr m5 : 56|2@1+ (1,0) [0|0] "" Vector__XXX
 SG_ IBST_d165_comsclEspIb1DlcErr m5 : 58|2@1+ (1,0) [0|0] "" Vector__XXX
 SG_ IBST_d166_comsclEspIb1Tout m5 : 60|2@1+ (1,0) [0|0] "" Vector__XXX
 SG_ IBST_d167_comsclEspIb2CntErr m5 : 62|2@1+ (1,0) [0|0] "" Vector__XXX
 SG_ IBST_d168_comsclEspIb2CsErr m6 : 8|2@1+ (1,0) [0|0] "" Vector__XXX
 SG_ IBST_d169_comsclEspIb2DlcErr m6 : 10|2@1+ (1,0) [0|0] "" Vector__XXX
 SG_ IBST_d170_comsclEspIb2Tout m6 : 12|2@1+ (1,0) [0|0] "" Vector__XXX
 SG_ IBST_d171_comsclEspIb3CntErr m6 : 14|2@1+ (1,0) [0|0] "" Vector__XXX
 SG_ IBST_d172_comsclEspIb3CsErr m6 : 16|2@1+ (1,0) [0|0] "" Vector__XXX
 SG_ IBST_d173_comsclEspIb3DlcErr m6 : 18|2@1+ (1,0) [0|0] "" Vector__XXX
 SG_ IBST_d174_comsclEspIb3Tout m6 : 20|2@1+ (1,0) [0|0] "" Vector__XXX
 SG_ IBST_d175_comsclGtwEsp1CntErr m6 : 22|2@1+ (1,0) [0|0] "" Vector__XXX
 SG_ IBST_d176_comsclGtwEsp1CsErr m6 : 24|2@1+ (1,0) [0|0] "" Vector__XXX
 SG_ IBST_d177_comsclGtwEsp1Corrpt m6 : 26|2@1+ (1,0) [0|0] "" Vector__XXX
 SG_ IBST_d178_comsclGtwEsp1Tout m6 : 28|2@1+ (1,0) [0|0] "" Vector__XXX
 SG_ IBST_d179_dcomSmrtActuNotInit m6 : 30|2@1+ (1,0) [0|0] "" Vector__XXX
 SG_ IBST_d180_rpsLengthAbsolHigh m6 : 32|2@1+ (1,0) [0|0] "" Vector__XXX
 SG_ IBST_d181_rpsLengthAbsolLow m6 : 34|2@1+ (1,0) [0|0] "" Vector__XXX
 SG_ IBST_d182_shutDownEeReadFail m6 : 36|2@1+ (1,0) [0|0] "" Vector__XXX
 SG_ IBST_d183_shutDownEeWriteFail m6 : 38|2@1+ (1,0) [0|0] "" Vector__XXX
 SG_ IBST_d184_maxTrvlAdjstReadErr m6 : 40|2@1+ (1,0) [0|0] "" Vector__XXX
 SG_ IBST_d185_psOffsMcEeReadFail m6 : 42|2@1+ (1,0) [0|0] "" Vector__XXX
 SG_ IBST_d186_psOffsMcEeWriteFail m6 : 44|2@1+ (1,0) [0|0] "" Vector__XXX
 SG_ IBST_d187_ltmSelfProtDeact m6 : 46|2@1+ (1,0) [0|0] "" Vector__XXX
 SG_ IBST_d188_pts1OffsEeReadFail m6 : 48|2@1+ (1,0) [0|0] "" Vector__XXX
 SG_ IBST_d189_diffStrokeRange m6 : 50|2@1+ (1,0) [0|0] "" Vector__XXX
 SG_ IBST_d190_notProgVin m6 : 52|2@1+ (1,0) [0|0] "" Vector__XXX
 SG_ IBST_d191_plausVin m6 : 54|2@1+ (1,0) [0|0] "" Vector__XXX
 SG_ IBST_d192_dlCorCSumVin m6 : 56|2@1+ (1,0) [0|0] "" Vector__XXX
 SG_ IBST_d193_ToutVin m6 : 58|2@1+ (1,0) [0|0] "" Vector__XXX
 SG_ IBST_d194_ecuEnableB6Fail m6 : 60|2@1+ (1,0) [0|0] "" Vector__XXX
 SG_ IBST_d195_ecuIbEnContErr m6 : 62|2@1+ (1,0) [0|0] "" Vector__XXX
 SG_ IBST_d196_sclEspIb1pEstMax m7 : 8|2@1+ (1,0) [0|0] "" Vector__XXX
 SG_ IBST_d197_sclEspIb1VehSpd m7 : 10|2@1+ (1,0) [0|0] "" Vector__XXX
 SG_ IBST_d198_sclEspIb2pLimExt m7 : 12|2@1+ (1,0) [0|0] "" Vector__XXX
 SG_ IBST_d199_sclEspIb2qTarExt m7 : 14|2@1+ (1,0) [0|0] "" Vector__XXX
 SG_ IBST_d200_sclEspIb3pFBlend m7 : 16|2@1+ (1,0) [0|0] "" Vector__XXX
 SG_ IBST_d201_sclEspIb3pMc1 m7 : 18|2@1+ (1,0) [0|0] "" Vector__XXX
 SG_ IBST_d202_sclEspIb3pTarDriver m7 : 20|2@1+ (1,0) [0|0] "" Vector__XXX
 SG_ IBST_d203_netBusOffNet0 m7 : 22|2@1+ (1,0) [0|0] "" Vector__XXX
 SG_ IBST_d204_netErrPassivNet0 m7 : 24|2@1+ (1,0) [0|0] "" Vector__XXX
 SG_ IBST_d205_netBusOffNet1 m7 : 26|2@1+ (1,0) [0|0] "" Vector__XXX
 SG_ IBST_d206_netErrPassivNet1 m7 : 28|2@1+ (1,0) [0|0] "" Vector__XXX
 SG_ IBST_d207_maxStrokeReached m7 : 30|2@1+ (1,0) [0|0] "" Vector__XXX
 SG_ IBST_d208_sysSwClockMismatch m7 : 32|2@1+ (1,0) [0|0] "" Vector__XXX
 SG_ IBST_d209_comsclGtwOdoCorrpt m7 : 34|2@1+ (1,0) [0|0] "" Vector__XXX
 SG_ IBST_d210_comsclGtwStatCorrpt m7 : 36|2@1+ (1,0) [0|0] "" Vector__XXX
 SG_ IBST_d211_comsclEpbStatCorrpt m7 : 38|2@1+ (1,0) [0|0] "" Vector__XXX
 SG_ IBST_d212_comsclGtwOdoTout m7 : 40|2@1+ (1,0) [0|0] "" Vector__XXX
 SG_ IBST_d213_comsclGtwStatTout m7 : 42|2@1+ (1,0) [0|0] "" Vector__XXX
 SG_ IBST_d214_comsclEpbStatTout m7 : 44|2@1+ (1,0) [0|0] "" Vector__XXX
 SG_ IBST_d215_comSclEpbStatCsErr m7 : 46|2@1+ (1,0) [0|0] "" Vector__XXX
 SG_ IBST_d216_comSclEpbStatCntFlt m7 : 48|2@1+ (1,0) [0|0] "" Vector__XXX
 SG_ IBST_d217_comSclDiTrq1Tout m7 : 50|2@1+ (1,0) [0|0] "" Vector__XXX
 SG_ IBST_d218_comSclDiTrq1Corrpt m7 : 52|2@1+ (1,0) [0|0] "" Vector__XXX
 SG_ IBST_d219_comSclDiTrq1CsErr m7 : 54|2@1+ (1,0) [0|0] "" Vector__XXX
 SG_ IBST_d220_comSclDiTrq1CntFlt m7 : 56|2@1+ (1,0) [0|0] "" Vector__XXX

BO_ 813 IBST_info: 4 iBooster
 SG_ IBST_infoIndex M : 0|8@1+ (1,0) [0|0] "" Vector__XXX
 SG_ IBST_buildType m10 : 8|8@1+ (1,0) [0|0] "" Vector__XXX
 SG_ IBST_componentId m10 : 48|16@1+ (1,0) [0|0] "" Vector__XXX
 SG_ IBST_pcbaId m11 : 16|8@1+ (1,0) [0|0] "" Vector__XXX
 SG_ IBST_assemblyId m11 : 24|8@1+ (1,0) [0|0] "" Vector__XXX
 SG_ IBST_usageId m11 : 32|16@1+ (1,0) [0|0] "" Vector__XXX
 SG_ IBST_udsProtocolVersion m20 : 8|8@1+ (1,0) [0|0] "" Vector__XXX
 SG_ IBST_bootloaderCrc m20 : 32|32@1+ (1,0) [0|0] "" Vector__XXX
 SG_ IBST_applicationCrc m13 : 32|32@1+ (1,0) [0|0] "" Vector__XXX
 SG_ IBST_variantCrc m22 : 32|32@1+ (1,0) [0|0] "" Vector__XXX

BO_ 925 IBST_status: 4 iBooster
 SG_ IBST_brakeInputStroke : 20|10@1+ (0.05,-0.5) [0|0] "mm" Vector__XXX
 SG_ IBST_iBoosterStatus : 17|3@1+ (1,0) [0|0] "" Vector__XXX
 SG_ IBST_pedalCalCurrentChecksum : 0|8@1+ (1,0) [0|0] "" Vector__XXX
 SG_ IBST_pedalCalCurrentCounter : 8|4@1+ (1,0) [0|0] "" Vector__XXX
 SG_ IBST_pedalCalCurrentCurve : 12|4@1+ (1,0) [0|0] "1" Vector__XXX
 SG_ IBST_pedalCalTxEnabled : 16|1@1+ (1,0) [0|0] "1" Vector__XXX

VAL_ 3 StW_Angl 16383 "SNA" ;
VAL_ 3 StW_AnglSens_Id 2 "MUST" 0 "PSBL" 1 "SELF" ;
VAL_ 3 StW_AnglSens_Stat 2 "ERR" 3 "ERR_INI" 1 "INI" 0 "OK" ;
VAL_ 3 StW_AnglSpd 16383 "SNA" ;
VAL_ 14 StW_AnglHP 16383 "SNA" ;
VAL_ 14 StW_AnglHP_Spd 16383 "SNA" ;
VAL_ 14 StW_AnglHP_Sens_Stat 3 "SNA" 2 "ERR" 1 "INI" 0 "OK" ;
VAL_ 14 StW_AnglHP_Sens_Id 3 "SNA" 2 "KOSTAL" 1 "DELPHI" 0 "TEST" ;
VAL_ 69 SpdCtrlLvr_Stat 32 "DN_1ST" 16 "UP_1ST" 8 "DN_2ND" 4 "UP_2ND" 2 "RWD" 1 "FWD" 0 "IDLE" ;
VAL_ 69 DTR_Dist_Rq 255 "SNA" 200 "ACC_DIST_7" 166 "ACC_DIST_6" 133 "ACC_DIST_5" 100 "ACC_DIST_4" 66 "ACC_DIST_3" 33 "ACC_DIST_2" 0 "ACC_DIST_1" ;
VAL_ 69 TurnIndLvr_Stat 3 "SNA" 2 "RIGHT" 1 "LEFT" 0 "IDLE" ;
VAL_ 69 HiBmLvr_Stat 3 "SNA" 2 "HIBM_FLSH_ON_PSD" 1 "HIBM_ON_PSD" 0 "IDLE" ;
VAL_ 69 WprWashSw_Psd 3 "SNA" 2 "WASH" 1 "TIPWIPE" 0 "NPSD" ;
VAL_ 69 WprWash_R_Sw_Posn_V2 3 "SNA" 2 "WASH" 1 "INTERVAL" 0 "OFF" ;
VAL_ 69 StW_Lvr_Stat 4 "STW_BACK" 3 "STW_FWD" 2 "STW_DOWN" 1 "STW_UP" 0 "NPSD" ;
VAL_ 69 StW_Cond_Psd 3 "SNA" 2 "DOWN" 1 "UP" 0 "NPSD" ;
VAL_ 69 HrnSw_Psd 3 "SNA" 2 "NDEF2" 1 "PSD" 0 "NPSD" ;
VAL_ 69 StW_Sw00_Psd 1 "PRESSED" 0 "NOT_PRESSED_SNA" ;
VAL_ 69 StW_Sw01_Psd 1 "PRESSED" 0 "NOT_PRESSED_SNA" ;
VAL_ 69 StW_Sw03_Psd 1 "PRESSED" 0 "NOT_PRESSED_SNA" ;
VAL_ 69 StW_Sw04_Psd 1 "PRESSED" 0 "NOT_PRESSED_SNA" ;
VAL_ 69 WprSw6Posn 7 "SNA" 6 "STAGE2" 5 "STAGE1" 4 "INTERVAL4" 3 "INTERVAL3" 2 "INTERVAL2" 1 "INTERVAL1" 0 "OFF" ;
VAL_ 257 GTW_epasControlType 0 "WITHOUT" 1 "WITH_ANGLE" 3 "WITH_BOTH" 2 "WITH_TORQUE" ;
VAL_ 109 StW_Sw_Stat3 7 "SNA" 6 "NDEF6" 5 "NDEF5" 4 "NDEF4" 3 "PLUS_MINUS" 2 "MINUS" 1 "PLUS" 0 "NPSD" ;
VAL_ 109 MsgTxmtId 3 "NDEF3" 2 "NDEF2" 1 "SCCM" 0 "EWM" ;
VAL_ 109 TSL_RND_Posn_StW 15 "SNA" 8 "D" 6 "INI" 4 "N_DOWN" 2 "N_UP" 1 "R" 0 "IDLE" ;
VAL_ 109 TSL_P_Psd_StW 3 "SNA" 2 "INI" 1 "PSD" 0 "IDLE" ;
VAL_ 257 GTW_epasEmergencyOn 1 "EMERGENCY_POWER" 0 "NONE" ;
VAL_ 257 GTW_epasLDWEnabled 1 "ALLOWED" 0 "INHIBITED" ;
VAL_ 257 GTW_epasPowerMode 0 "DRIVE_OFF" 1 "DRIVE_ON" 3 "LOAD_SHED" 2 "SHUTTING_DOWN" 15 "SNA" ;
VAL_ 257 GTW_epasTuneRequest 1 "DM_COMFORT" 3 "DM_SPORT" 2 "DM_STANDARD" 0 "FAIL_SAFE_DEFAULT" 4 "RWD_COMFORT" 6 "RWD_SPORT" 5 "RWD_STANDARD" 7 "SNA" ;
VAL_ 264 DI_torqueDriver -4096 "SNA" ;
VAL_ 264 DI_torqueMotor -4096 "SNA" ;
VAL_ 264 DI_soptState 7 "SOPT_TEST_SNA" 4 "SOPT_TEST_NOT_RUN" 3 "SOPT_TEST_PASSED" 2 "SOPT_TEST_FAILED" 1 "SOPT_TEST_IN_PROGRESS" 0 "SOPT_PRE_TEST" ;
VAL_ 264 DI_motorRPM -32768 "SNA" ;
VAL_ 264 DI_pedalPos 255 "SNA" ;
VAL_ 280 DI_torqueEstimate -2048 "SNA" ;
VAL_ 280 DI_gear 7 "DI_GEAR_SNA" 4 "DI_GEAR_D" 3 "DI_GEAR_N" 2 "DI_GEAR_R" 1 "DI_GEAR_P" 0 "DI_GEAR_INVALID" ;
VAL_ 280 DI_brakePedal 1 "Applied" 0 "Not_applied" ;
VAL_ 280 DI_vehicleSpeed 4095 "SNA" ;
VAL_ 280 DI_gearRequest 7 "DI_GEAR_SNA" 4 "DI_GEAR_D" 3 "DI_GEAR_N" 2 "DI_GEAR_R" 1 "DI_GEAR_P" 0 "DI_GEAR_INVALID" ;
VAL_ 280 DI_torqueInterfaceFailure 1 "TORQUE_INTERFACE_FAILED" 0 "TORQUE_INTERFACE_NORMAL" ;
VAL_ 280 DI_brakePedalState 3 "SNA" 2 "INVALID" 1 "ON" 0 "OFF" ;
VAL_ 280 DI_epbParkRequest 1 "Park_requested" 0 "No_request" ;
VAL_ 280 DI_epbInterfaceReady 1 "EPB_INTERFACE_READY" 0 "EPB_INTERFACE_NOT_READY" ;
VAL_ 309 ESP_absBrakeEvent 1 "ACTIVE" 0 "NOT_ACTIVE" ;
VAL_ 309 ESP_brakeDiscWipingActive 1 "ACTIVE" 0 "INACTIVE" ;
VAL_ 309 ESP_brakeLamp 0 "OFF" 1 "ON" ;
VAL_ 309 ESP_espFaultLamp 0 "OFF" 1 "ON" ;
VAL_ 309 ESP_espLampFlash 1 "FLASH" 0 "OFF" ;
VAL_ 309 ESP_hillStartAssistActive 1 "ACTIVE" 0 "INACTIVE" 2 "NOT_AVAILABLE" 3 "SNA" ;
VAL_ 309 ESP_absFaultLamp 0 "OFF" 1 "ON" ;
VAL_ 309 ESP_espOffLamp 0 "OFF" 1 "ON" ;
VAL_ 309 ESP_stabilityControlSts 2 "ENGAGED" 3 "FAULTED" 5 "INIT" 4 "NOT_CONFIGURED" 0 "OFF" 1 "ON" ;
VAL_ 309 ESP_tcLampFlash 1 "FLASH" 0 "OFF" ;
VAL_ 537 DAS_pscParkState 15 "SNA" 14 "SUMMON" 10 "PAUSE" 9 "SEARCH" 8 "COMPLETE" 7 "ABORT" 6 "PARALLEL_PULL_OUT_TO_RIGHT" 5 "PARALLEL_PULL_OUT_TO_LEFT" 4 "PARK_RIGHT_CROSS" 3 "PARK_RIGHT_PARALLEL" 2 "PARK_LEFT_CROSS" 1 "PARK_LEFT_PARALLEL" 0 "NONE" ;
VAL_ 537 DAS_eacState 4 "SNA" 3 "EAC_FAULT" 2 "EAC_ACTIVE" 1 "EAC_AVAILABLE" 0 "EAC_INHIBITED" ;
VAL_ 568 UI_mapSpeedLimit 31 "SNA" 30 "UNLIMITED" 29 "LESS_OR_EQ_160" 28 "LESS_OR_EQ_150" 27 "LESS_OR_EQ_140" 26 "LESS_OR_EQ_130" 25 "LESS_OR_EQ_120" 24 "LESS_OR_EQ_115" 23 "LESS_OR_EQ_110" 22 "LESS_OR_EQ_105" 21 "LESS_OR_EQ_100" 20 "LESS_OR_EQ_95" 19 "LESS_OR_EQ_90" 18 "LESS_OR_EQ_85" 17 "LESS_OR_EQ_80" 16 "LESS_OR_EQ_75" 15 "LESS_OR_EQ_70" 14 "LESS_OR_EQ_65" 13 "LESS_OR_EQ_60" 12 "LESS_OR_EQ_55" 11 "LESS_OR_EQ_50" 10 "LESS_OR_EQ_45" 9 "LESS_OR_EQ_40" 8 "LESS_OR_EQ_35" 7 "LESS_OR_EQ_30" 6 "LESS_OR_EQ_25" 5 "LESS_OR_EQ_20" 4 "LESS_OR_EQ_15" 3 "LESS_OR_EQ_10" 2 "LESS_OR_EQ_7" 1 "LESS_OR_EQ_5" 0 "UNKNOWN" ;
VAL_ 569 DAS_leftLineUsage 3 "BLACKLISTED" 2 "FUSED" 1 "AVAILABLE" 0 "REJECTED_UNAVAILABLE" ;
VAL_ 569 DAS_rightLineUsage 3 "BLACKLISTED" 2 "FUSED" 1 "AVAILABLE" 0 "REJECTED_UNAVAILABLE" ;
VAL_ 569 DAS_leftFork 3 "LEFT_FORK_UNAVAILABLE" 2 "LEFT_FORK_SELECTED" 1 "LEFT_FORK_AVAILABLE" 0 "LEFT_FORK_NONE" ;
VAL_ 569 DAS_rightFork 3 "RIGHT_FORK_UNAVAILABLE" 2 "RIGHT_FORK_SELECTED" 1 "RIGHT_FORK_AVAILABLE" 0 "RIGHT_FORK_NONE" ;
VAL_ 520 GTW_hillStartAssistEnabled 1 "HSA_ENABLED" 0 "HSA_DISABLED" ;
VAL_ 520 GTW_brakeDiscWipeRequest 3 "BDW_SNA" 2 "BDW_STRONG" 1 "BDW_LIGHT" 0 "BDW_NO_REQUEST" ;
VAL_ 520 GTW_pedalCalRxEnable 1 "ENABLED" 0 "DISABLED" ;
VAL_ 520 GTW_ambientTemperature 255 "SNA" ;
VAL_ 520 GTW_pedalCalTargetCurve 6 "SNA" 5 "PEDAL_CURVE_5" 4 "PEDAL_CURVE_4" 3 "PEDAL_CURVE_3" 2 "PEDAL_CURVE_2" 1 "PEDAL_CURVE_1" 0 "PEDAL_CURVE_0" ;
VAL_ 520 GTW_espModeSwitch 5 "SWITCH_03_PRESSED_ESP_DEV_2" 4 "SWITCH_02_PRESSED_ESP_DEV_1" 3 "SWITCH_01_PRESSED_TC_OFF" 2 "SNA" 1 "SWITCH_00_PRESSED_NORMAL" 0 "SWITCH_NOT_PRESSED" ;
VAL_ 521 DAS_locMode 3 "DAS_LOC_DRIVERLESS" 2 "DAS_LOC_RESTRICTED" 1 "DAS_LOC_NORMAL" 0 "DAS_LOC_OFF" ;
VAL_ 521 DAS_locState 7 "DAS_LOC_FAULT_SNA" 6 "DAS_LOC_AEB_ACTIVE" 2 "DAS_LOC_CANCEL_SILENT" 1 "DAS_LOC_CANCEL_GENERIC" 0 "DAS_LOC_HEALTHY" ;
VAL_ 521 DAS_locRequest 4 "DAS_RQ_PARK" 3 "DAS_RQ_HOLD" 2 "DAS_RQ_BACKWARD" 1 "DAS_RQ_FORWARD" 0 "DAS_RQ_IDLE" ;
VAL_ 521 DAS_locJerkMin 255 "SNA" ;
VAL_ 521 DAS_locJerkMax 255 "SNA" ;
VAL_ 521 DAS_locSpeed 2047 "SNA" ;
VAL_ 521 DAS_locAccelMin 511 "SNA" ;
VAL_ 521 DAS_locAccelMax 511 "SNA" ;
VAL_ 522 driverBrakeStatus 2 "APPLIED" 1 "NOT_APPLIED" ;
VAL_ 760 UI_mapSpeedLimitUnits 1 "KPH" 0 "MPH" ;
VAL_ 760 UI_userSpeedOffsetUnits 1 "KPH" 0 "MPH" ;
VAL_ 643 AirTemp_Insd 255 "SNA" ;
VAL_ 643 AirTemp_Outsd 254 "INIT" 255 "SNA" ;
VAL_ 643 Bckl_Sw_RL_Stat_SAM_R 2 "FLT" 1 "NOT" 0 "OK" 3 "SNA" ;
VAL_ 643 Bckl_Sw_RM_Stat_SAM_R 2 "FLT" 1 "NOT" 0 "OK" 3 "SNA" ;
VAL_ 643 Bckl_Sw_RR_Stat_SAM_R 2 "FLT" 1 "NOT" 0 "OK" 3 "SNA" ;
VAL_ 643 DL_RLtch_Stat 1 "CLS" 0 "NDEF0" 2 "OPN" 3 "SNA" ;
VAL_ 643 DrRLtch_FL_Stat 1 "CLS" 0 "NDEF0" 2 "OPN" 3 "SNA" ;
VAL_ 643 DrRLtch_FR_Stat 1 "CLS" 0 "NDEF0" 2 "OPN" 3 "SNA" ;
VAL_ 643 DrRLtch_RL_Stat 1 "CLS" 0 "NDEF0" 2 "OPN" 3 "SNA" ;
VAL_ 643 DrRLtch_RR_Stat 1 "CLS" 0 "NDEF0" 2 "OPN" 3 "SNA" ;
VAL_ 643 EngHd_Stat 1 "CLS" 0 "NDEF0" 2 "OPN" 3 "SNA" ;
VAL_ 643 LgtSens_Night 0 "DAY" 1 "NIGHT" ;
VAL_ 643 MPkBrk_Stat 1 "ENGG" 0 "RELS" ;
VAL_ 643 RevGr_Engg 0 "DISENGG" 1 "ENGG" 2 "NDEF2" 3 "SNA" ;
VAL_ 643 StW_Cond_Stat 3 "BLINK" 1 "NDEF1" 0 "OFF" 2 "ON" ;
VAL_ 643 Trlr_Stat 2 "NDEF2" 0 "NONE" 1 "OK" 3 "SNA" ;
VAL_ 697 DAS_setSpeed 4095 "SNA" ;
VAL_ 697 DAS_accState 15 "FAULT_SNA" 14 "ACC_CANCEL_OUT_OF_CALIBRATION" 13 "ACC_CANCEL_GENERIC_SILENT" 12 "ACC_CANCEL_PATH_NOT_CLEAR" 11 "APC_SELFPARK_START" 10 "APC_UNPARK_COMPLETE" 9 "APC_PAUSE" 8 "APC_ABORT" 7 "APC_COMPLETE" 6 "APC_FORWARD" 5 "APC_BACKWARD" 4 "ACC_ON" 3 "ACC_HOLD" 2 "ACC_CANCEL_RADAR_BLIND" 1 "ACC_CANCEL_CAMERA_BLIND" 0 "ACC_CANCEL_GENERIC" ;
VAL_ 697 DAS_aebEvent 3 "AEB_SNA" 2 "AEB_FAULT" 1 "AEB_ACTIVE" 0 "AEB_NOT_ACTIVE" ;
VAL_ 697 DAS_jerkMin 511 "SNA" ;
VAL_ 697 DAS_jerkMax 255 "SNA" ;
VAL_ 697 DAS_accelMin 511 "SNA" ;
VAL_ 697 DAS_accelMax 511 "SNA" ;
VAL_ 782 PARK_pscRightCurbType 2 "HIGH_CURB" 1 "LOW_CURB" 0 "VIRTUAL_CURB" ;
VAL_ 782 PARK_pscLeftCurbType 2 "HIGH_CURB" 1 "LOW_CURB" 0 "VIRTUAL_CURB" ;
VAL_ 782 PARK_autoCalComplete 1 "COMPLETE" 0 "INCOMPLETE" ;
VAL_ 782 PARK_geometryType 2 "MODELX" 1 "MODELS_2" 0 "MODELS" ;
VAL_ 782 PARK_tireFitment 3 "SNA" 1 "STAGGERED" 0 "SQUARE" ;
VAL_ 782 PARK_rackDetected 3 "SNA" 2 "RACK_DETECTED" 1 "NO_RACK" 0 "UNKNOWN" ;
VAL_ 782 PARK_sdiActive 1 "SDI_ENABLED" 0 "SDI_DISABLED" ;
VAL_ 782 PARK_sdiNoise 3 "SDI_NOISE_SNA" 2 "SDI_NOISE_RAIN" 1 "SDI_NOISE_HIGH" 0 "SDI_NOISE_NOMINAL" ;
VAL_ 782 PARK_sdiBlindSpotRight 3 "SNA" 2 "UNUSED" 1 "WARNING" 0 "NO_WARNING" ;
VAL_ 782 PARK_sdiBlindSpotLeft 3 "SNA" 2 "UNUSED" 1 "WARNING" 0 "NO_WARNING" ;
VAL_ 792 BOOT_STATE 2 "Init" 3 "SNA" 0 "closed" 1 "open" ;
VAL_ 792 CERRD 1 "CAN error detect" 0 "no Can error detected" ;
VAL_ 792 DAY 1 "Init" 0 "SNA" ;
VAL_ 792 DOOR_STATE_FL 2 "Init" 3 "SNA" 0 "closed" 1 "open" ;
VAL_ 792 DOOR_STATE_FR 2 "Init" 3 "SNA" 0 "closed" 1 "open" ;
VAL_ 792 DOOR_STATE_FrontTrunk 2 "Init" 3 "SNA" 0 "closed" 1 "open" ;
VAL_ 792 DOOR_STATE_RL 2 "Init" 3 "SNA" 0 "closed" 1 "open" ;
VAL_ 792 DOOR_STATE_RR 2 "Init" 3 "SNA" 0 "closed" 1 "open" ;
VAL_ 792 GTW_updateInProgress 1 "IN_PROGRESS" 2 "IN_PROGRESS_NOT_USED" 3 "IN_PROGRESS_SNA" 0 "NOT_IN_PROGRESS" ;
VAL_ 792 Hour 30 "Init" 31 "SNA" ;
VAL_ 792 MCU_factoryMode 1 "FACTORY_MODE" 0 "NORMAL_MODE" ;
VAL_ 792 MCU_transportModeOn 0 "NORMAL_MODE" ;
VAL_ 792 MINUTE 62 "Init" 63 "SNA" ;
VAL_ 792 MONTH 1 "Init" 15 "SNA" ;
VAL_ 792 SECOND 62 "Init" 63 "SNA" ;
VAL_ 792 YEAR 126 "Init" 127 "SNA" ;
VAL_ 872 DI_aebState 2 "ENABLED" 4 "FAULT" 7 "SNA" 1 "STANDBY" 3 "STANDSTILL" 0 "UNAVAILABLE" ;
VAL_ 872 DI_analogSpeed 4095 "SNA" ;
VAL_ 872 DI_cruiseState 2 "ENABLED" 5 "FAULT" 0 "OFF" 4 "OVERRIDE" 7 "PRE_CANCEL" 6 "PRE_FAULT" 1 "STANDBY" 3 "STANDSTILL" ;
VAL_ 872 DI_digitalSpeed 255 "SNA" ;
VAL_ 872 DI_immobilizerState 2 "AUTHENTICATING" 3 "DISARMED" 6 "FAULT" 4 "IDLE" 0 "INIT_SNA" 1 "REQUEST" 5 "RESET" ;
VAL_ 872 DI_speedUnits 1 "KPH" 0 "MPH" ;
VAL_ 872 DI_state 3 "ABORT" 4 "ENABLE" 2 "FAULT" 1 "STANDBY" 0 "UNAVAILABLE" ;
VAL_ 872 DI_systemState 3 "ABORT" 4 "ENABLE" 2 "FAULT" 1 "STANDBY" 0 "UNAVAILABLE" ;
VAL_ 872 DI_vehicleHoldState 2 "BLEND_IN" 4 "BLEND_OUT" 6 "FAULT" 7 "INIT" 5 "PARK" 1 "STANDBY" 3 "STANDSTILL" 0 "UNAVAILABLE" ;
VAL_ 880 EPAS_currentTuneMode 1 "DM_COMFORT" 3 "DM_SPORT" 2 "DM_STANDARD" 0 "FAIL_SAFE_DEFAULT" 4 "RWD_COMFORT" 6 "RWD_SPORT" 5 "RWD_STANDARD" 7 "UNAVAILABLE" ;
VAL_ 880 EPAS_eacErrorCode 14 "EAC_ERROR_EPB_INHIBIT" 3 "EAC_ERROR_HANDS_ON" 7 "EAC_ERROR_HIGH_ANGLE_RATE_REQ" 9 "EAC_ERROR_HIGH_ANGLE_RATE_SAFETY" 6 "EAC_ERROR_HIGH_ANGLE_REQ" 8 "EAC_ERROR_HIGH_ANGLE_SAFETY" 10 "EAC_ERROR_HIGH_MMOT_SAFETY" 11 "EAC_ERROR_HIGH_TORSION_SAFETY" 0 "EAC_ERROR_IDLE" 12 "EAC_ERROR_LOW_ASSIST" 2 "EAC_ERROR_MAX_SPEED" 1 "EAC_ERROR_MIN_SPEED" 13 "EAC_ERROR_PINION_VEL_DIFF" 4 "EAC_ERROR_TMP_FAULT" 5 "EAR_ERROR_MAX_STEER_DELTA" 15 "SNA" ;
VAL_ 880 EPAS_eacStatus 2 "EAC_ACTIVE" 1 "EAC_AVAILABLE" 3 "EAC_FAULT" 0 "EAC_INHIBITED" 4 "SNA" ;
VAL_ 880 EPAS_handsOnLevel 0 "0" 1 "1" 2 "2" 3 "3" ;
VAL_ 880 EPAS_steeringFault 1 "FAULT" 0 "NO_FAULT" ;
VAL_ 880 EPAS_steeringRackForce 1022 "NOT_IN_SPEC" 1023 "SNA" ;
VAL_ 880 EPAS_steeringReduced 0 "NORMAL_ASSIST" 1 "REDUCED_ASSIST" ;
VAL_ 880 EPAS_torsionBarTorque 0 "SEE_SPECIFICATION" 4095 "SNA" 4094 "UNDEFINABLE_DATA" ;
VAL_ 904 MCU_clusterReadyForDrive 0 "NO_SNA" 1 "YES" ;
VAL_ 905 DAS_accSpeedLimit 1023 "SNA" 0 "NONE" ;
VAL_ 905 DAS_pmmObstacleSeverity 7 "PMM_SNA" 6 "PMM_ACCEL_LIMIT" 5 "PMM_CRASH_FRONT" 4 "PMM_CRASH_REAR" 3 "PMM_BRAKE_REQUEST" 2 "PMM_IMMINENT_FRONT" 1 "PMM_IMMINENT_REAR" 0 "PMM_NONE" ;
VAL_ 905 DAS_pmmLoggingRequest 1 "TRUE" 0 "FALSE" ;
VAL_ 905 DAS_activationFailureStatus 2 "LC_ACTIVATION_FAILED_2" 1 "LC_ACTIVATION_FAILED_1" 0 "LC_ACTIVATION_IDLE" ;
VAL_ 905 DAS_pmmUltrasonicsFaultReason 4 "PMM_ULTRASONICS_INVALID_MIA" 3 "PMM_ULTRASONICS_BLOCKED_BOTH" 2 "PMM_ULTRASONICS_BLOCKED_REAR" 1 "PMM_ULTRASONICS_BLOCKED_FRONT" 0 "PMM_ULTRASONICS_NO_FAULT" ;
VAL_ 905 DAS_pmmRadarFaultReason 2 "PMM_RADAR_INVALID_MIA" 1 "PMM_RADAR_BLOCKED_FRONT" 0 "PMM_RADAR_NO_FAULT" ;
VAL_ 905 DAS_pmmSysFaultReason 7 "PMM_FAULT_BRAKE_PEDAL_INHIBIT" 6 "PMM_FAULT_ROAD_TYPE" 5 "PMM_FAULT_DISABLED_BY_USER" 4 "PMM_FAULT_STEERING_ANGLE_RATE" 3 "PMM_FAULT_DI_FAULT" 2 "PMM_FAULT_SPEED" 1 "PMM_FAULT_DAS_DISABLED" 0 "PMM_FAULT_NONE" ;
VAL_ 905 DAS_pmmCameraFaultReason 2 "PMM_CAMERA_INVALID_MIA" 1 "PMM_CAMERA_BLOCKED_FRONT" 0 "PMM_CAMERA_NO_FAULT" ;
VAL_ 905 DAS_ACC_report 24 "ACC_REPORT_BEHAVIOR_REPORT" 23 "ACC_REPORT_CAMERA_ONLY" 22 "ACC_REPORT_RADAR_OBJ_FIVE" 21 "ACC_REPORT_CIPV_CUTTING_OUT" 20 "ACC_REPORT_MCVLR_IN_PATH" 19 "ACC_REPORT_MCVLR_DPP" 18 "ACC_REPORT_FLEET_SPEEDS" 17 "ACC_REPORT_TARGET_MCP" 16 "ACC_REPORT_RADAR_OBJ_TWO" 15 "ACC_REPORT_RADAR_OBJ_ONE" 14 "ACC_REPORT_LC_EXTERNAL_STATE_ACTIVE_RESTRICTED" 13 "ACC_REPORT_LC_EXTERNAL_STATE_ABORTED" 12 "ACC_REPORT_LC_EXTERNAL_STATE_ABORTING" 11 "ACC_REPORT_LC_HANDS_ON_REQD_STRUCK_OUT" 10 "ACC_REPORT_CSA" 9 "ACC_REPORT_TARGET_TYPE_FAULT" 8 "ACC_REPORT_TARGET_TYPE_IPSO" 7 "ACC_REPORT_TARGET_TYPE_TRAFFIC_LIGHT" 6 "ACC_REPORT_TARGET_TYPE_STOP_SIGN" 5 "ACC_REPORT_TARGET_CUTIN" 4 "ACC_REPORT_TARGET_MCVR" 3 "ACC_REPORT_TARGET_MCVL" 2 "ACC_REPORT_TARGET_IN_FRONT_OF_CIPV" 1 "ACC_REPORT_TARGET_CIPV" 0 "ACC_REPORT_TARGET_NONE" ;
VAL_ 921 DAS_lssState 7 "LSS_STATE_OFF" 6 "LSS_STATE_ABORT" 5 "LSS_STATE_BLINDSPOT" 4 "LSS_STATE_MONITOR" 3 "LSS_STATE_ELK" 2
VAL_ 905 DAS_radarTelemetry 2 "RADAR_TELEMETRY_URGENT" 1 "RADAR_TELEMETRY_NORMAL" 0 "RADAR_TELEMETRY_IDLE" ;
VAL_ 905 DAS_robState 3 "ROB_STATE_MAPLESS" 2 "ROB_STATE_ACTIVE" 1 "ROB_STATE_MEASURE" 0 "ROB_STATE_INHIBITED" ;
VAL_ 905 DAS_driverInteractionLevel 2 "CONTINUED_DRIVER_NOT_INTERACTING" 1 "DRIVER_NOT_INTERACTING" 0 "DRIVER_INTERACTING" ;
VAL_ 905 DAS_ppOffsetDesiredRamp 128 "PP_NO_OFFSET" ;
VAL_ 905 DAS_longCollisionWarning 15 "FCM_LONG_COLLISION_WARNING_SNA" 12 "FCM_LONG_COLLISION_WARNING_VEHICLE_CIPV2" 11 "FCM_LONG_COLLISION_WARNING_VEHICLE_MCVR2" 10 "FCM_LONG_COLLISION_WARNING_VEHICLE_MCVR" 9 "FCM_LONG_COLLISION_WARNING_VEHICLE_MCVL2" 8 "FCM_LONG_COLLISION_WARNING_VEHICLE_MCVL" 7 "FCM_LONG_COLLISION_WARNING_VEHICLE_CUTIN" 6 "FCM_LONG_COLLISION_WARNING_VEHICLE_CIPV" 5 "FCM_LONG_COLLISION_WARNING_TFL_STOPLINE" 4 "FCM_LONG_COLLISION_WARNING_STOPSIGN_STOPLINE" 3 "FCM_LONG_COLLISION_WARNING_IPSO" 2 "FCM_LONG_COLLISION_WARNING_PEDESTRIAN" 1 "FCM_LONG_COLLISION_WARNING_VEHICLE_UNKNOWN" 0 "FCM_LONG_COLLISION_WARNING_NONE" ;
VAL_ 921 DAS_autopilotState 5 "ACTIVE_NAVIGATE_ON_AUTOPILOT" 4 "ACTIVE_2" 3 "ACTIVE_1" 2 "AVAILABLE" 1 "UNAVAILABLE" 0 "DISABLED" ;
VAL_ 921 DAS_blindSpotRearLeft 3 "SNA" 2 "WARNING_LEVEL_2" 1 "WARNING_LEVEL_1" 0 "NO_WARNING" ;
VAL_ 921 DAS_blindSpotRearRight 3 "SNA" 2 "WARNING_LEVEL_2" 1 "WARNING_LEVEL_1" 0 "NO_WARNING" ;
VAL_ 921 DAS_fusedSpeedLimit 31 "NONE" 0 "UNKNOWN_SNA" ;
VAL_ 921 DAS_suppressSpeedWarning 1 "Suppress_Speed_Warning" 0 "Do_Not_Suppress" ;
VAL_ 921 DAS_visionOnlySpeedLimit 31 "NONE" 0 "UNKNOWN_SNA" ;
VAL_ 921 DAS_heaterState 1 "HEATER_ON" 0 "HEATER_OFF_SNA" ;
VAL_ 921 DAS_forwardCollisionWarning 3 "SNA" 1 "FORWARD_COLLISION_WARNING" 0 "NONE" ;
VAL_ 921 DAS_autoparkReady 1 "AUTOPARK_READY" 0 "AUTOPARK_UNAVAILABLE" ;
VAL_ 921 DAS_sideCollisionAvoid 3 "SNA" 2 "AVOID_RIGHT" 1 "AVOID_LEFT" 0 "NONE" ;
VAL_ 921 DAS_sideCollisionWarning 3 "WARN_LEFT_RIGHT" 2 "WARN_RIGHT" 1 "WARN_LEFT" 0 "NONE" ;
VAL_ 921 DAS_sideCollisionInhibit 1 "INHIBIT" 0 "NO_INHIBIT" ;
VAL_ 905 DAS_csaState 3 "CSA_EXTERNAL_STATE_HOLD" 2 "CSA_EXTERNAL_STATE_ENABLE" 1 "CSA_EXTERNAL_STATE_AVAILABLE" 0 "CSA_EXTERNAL_STATE_UNAVAILABLE" ;
VAL_ 921 DAS_laneDepartureWarning 5 "SNA" 4 "RIGHT_WARNING_SEVERE" 3 "LEFT_WARNING_SEVERE" 2 "RIGHT_WARNING" 1 "LEFT_WARNING" 0 "NONE" ;
VAL_ 921 DAS_fleetSpeedState 3 "FLEETSPEED_HOLD" 2 "FLEETSPEED_ACTIVE" 1 "FLEETSPEED_AVAILABLE" 0 "FLEETSPEED_UNAVAILABLE" ;
VAL_ 921 DAS_autopilotHandsOnState 15 "LC_HANDS_ON_SNA" 8 "LC_HANDS_ON_SUSPENDED" 7 "LC_HANDS_ON_REQD_STRUCK_OUT" 5 "LC_HANDS_ON_REQD_CHIME_2" 4 "LC_HANDS_ON_REQD_CHIME_1" 3 "LC_HANDS_ON_REQD_VISUAL" 2 "LC_HANDS_ON_REQD_NOT_DETECTED" 1 "LC_HANDS_ON_REQD_DETECTED" 0 "LC_HANDS_ON_NOT_REQD" ;
VAL_ 921 DAS_autoLaneChangeState 31 "ALC_SNA" 30 "ALC_ABORT_MISSION_PLAN_INVALID" 29 "ALC_ABORT_TIMEOUT" 28 "ALC_WAITING_HANDS_ON" 27 "ALC_BLOCKED_LANE_TYPE_R" 26 "ALC_BLOCKED_LANE_TYPE_L" 25 "ALC_BLOCKED_VEH_TTC_AND_USS_R" 24 "ALC_BLOCKED_VEH_TTC_R" 23 "ALC_BLOCKED_VEH_TTC_AND_USS_L" 22 "ALC_BLOCKED_VEH_TTC_L" 21 "ALC_UNAVAILABLE_SOLID_LANE_LINE" 20 "ALC_ABORT_OTHER_REASON" 19 "ALC_ABORT_BLINKER_TURNED_OFF" 18 "ALC_ABORT_LC_HEALTH_BAD" 17 "ALC_ABORT_POOR_VIEW_RANGE" 16 "ALC_ABORT_SIDE_OBSTACLE_PRESENT_R" 15 "ALC_ABORT_SIDE_OBSTACLE_PRESENT_L" 14 "ALC_WAITING_FOR_FWD_OBST_TO_PASS_R" 13 "ALC_WAITING_FOR_FWD_OBST_TO_PASS_L" 12 "ALC_WAITING_FOR_SIDE_OBST_TO_PASS_R" 11 "ALC_WAITING_FOR_SIDE_OBST_TO_PASS_L" 10 "ALC_IN_PROGRESS_R" 9 "ALC_IN_PROGRESS_L" 8 "ALC_AVAILABLE_BOTH" 7 "ALC_AVAILABLE_ONLY_R" 6 "ALC_AVAILABLE_ONLY_L" 5 "ALC_UNAVAILABLE_VEHICLE_SPEED" 4 "ALC_UNAVAILABLE_EXITING_HIGHWAY" 3 "ALC_UNAVAILABLE_TP_FOLLOW" 2 "ALC_UNAVAILABLE_SONICS_INVALID" 1 "ALC_UNAVAILABLE_NO_LANES" 0 "ALC_UNAVAILABLE_DISABLED" ;
VAL_ 1001 DAS_headlightRequest 3 "DAS_HEADLIGHT_REQUEST_INVALID" 1 "DAS_HEADLIGHT_REQUEST_ON" 0 "DAS_HEADLIGHT_REQUEST_OFF" ;
VAL_ 1001 DAS_hazardLightRequest 3 "DAS_REQUEST_HAZARDS_SNA" 2 "DAS_REQUEST_HAZARDS_UNUSED" 1 "DAS_REQUEST_HAZARDS_ON" 0 "DAS_REQUEST_HAZARDS_OFF" ;
VAL_ 1001 DAS_wiperSpeed 15 "DAS_WIPER_SPEED_INVALID" 14 "DAS_WIPER_SPEED_14" 13 "DAS_WIPER_SPEED_13" 12 "DAS_WIPER_SPEED_12" 11 "DAS_WIPER_SPEED_11" 10 "DAS_WIPER_SPEED_10" 9 "DAS_WIPER_SPEED_9" 8 "DAS_WIPER_SPEED_8" 7 "DAS_WIPER_SPEED_7" 6 "DAS_WIPER_SPEED_6" 5 "DAS_WIPER_SPEED_5" 4 "DAS_WIPER_SPEED_4" 3 "DAS_WIPER_SPEED_3" 2 "DAS_WIPER_SPEED_2" 1 "DAS_WIPER_SPEED_1" 0 "DAS_WIPER_SPEED_OFF" ;
VAL_ 1001 DAS_turnIndicatorRequest 3 "DAS_TURN_INDICATOR_CANCEL" 2 "DAS_TURN_INDICATOR_RIGHT" 1 "DAS_TURN_INDICATOR_LEFT" 0 "DAS_TURN_INDICATOR_NONE" ;
VAL_ 1001 DAS_highLowBeamDecision 3 "DAS_HIGH_BEAM_SNA" 2 "DAS_HIGH_BEAM_ON" 1 "DAS_HIGH_BEAM_OFF" 0 "DAS_HIGH_BEAM_UNDECIDED" ;
VAL_ 1001 DAS_highLowBeamOffReason 5 "HIGH_BEAM_OFF_REASON_SNA" 4 "HIGH_BEAM_OFF_REASON_HEAD_LIGHT" 3 "HIGH_BEAM_OFF_REASON_AMBIENT_LIGHT" 2 "HIGH_BEAM_OFF_REASON_MOVING_RADAR_TARGET" 1 "HIGH_BEAM_OFF_REASON_MOVING_VISION_TARGET" 0 "HIGH_BEAM_ON" ;
VAL_ 1001 DAS_turnIndicatorRequestReason 6 "DAS_ACTIVE_COMMANDED_LANE_CHANGE" 5 "DAS_CANCEL_FORK" 4 "DAS_CANCEL_LANE_CHANGE" 3 "DAS_ACTIVE_FORK" 2 "DAS_ACTIVE_SPEED_LANE_CHANGE" 1 "DAS_ACTIVE_NAV_LANE_CHANGE" 0 "DAS_NONE" ;
VAL_ 1160 DAS_steeringAngleRequest 16384 "ZERO_ANGLE" ;
VAL_ 1160 DAS_steeringControlType 1 "ANGLE_CONTROL" 3 "DISABLED" 0 "NONE" 2 "RESERVED" ;
VAL_ 1160 DAS_steeringHapticRequest 1 "ACTIVE" 0 "IDLE" ;
VAL_ 1362 STATE 5 "FAULT_TIMEOUT" 4 "FAULT_STARTUP" 3 "FAULT_SCE" 2 "FAULT_SEND" 1 "FAULT_BAD_CHECKSUM" 0 "NO_FAULT" ;
VAL_ 1364 DriverBrakeApplied 1 "Yes" 0 "No" ;
VAL_ 1364 BrakeApplied 1 "Yes" 0 "No" ;
VAL_ 1364 BrakeOK 1 "Yes" 0 "No" ;
VAL_ 1364 Status 5 "FAULT_TIMEOUT" 4 "FAULT_STARTUP" 3 "FAULT_SCE" 2 "FAULT_SEND" 1 "FAULT_BAD_CHECKSUM" 0 "NO_FAULT" ;
VAL_ 1363 BrakeMode 3 "Reserved" 2 "Position Control" 1 "Relative Control" 0 "Disengadged" ;
VAL_ 861 IBST_d000_bmsInitTestFail 0 "NOT_TESTED_DTC" 1 "PASSED_DTC" 2 "FAILED_DTC" 3 "UNABLE_TO_TEST_DTC" ;
VAL_ 861 IBST_d001_bmcSingleTransTest 0 "NOT_TESTED_DTC" 1 "PASSED_DTC" 2 "FAILED_DTC" 3 "UNABLE_TO_TEST_DTC" ;
VAL_ 861 IBST_d002_tle5012SsccrcFail 0 "NOT_TESTED_DTC" 1 "PASSED_DTC" 2 "FAILED_DTC" 3 "UNABLE_TO_TEST_DTC" ;
VAL_ 861 IBST_d003_tle5012Config 0 "NOT_TESTED_DTC" 1 "PASSED_DTC" 2 "FAILED_DTC" 3 "UNABLE_TO_TEST_DTC" ;
VAL_ 861 IBST_d004_deadlMonTaskx1Ovr 0 "NOT_TESTED_DTC" 1 "PASSED_DTC" 2 "FAILED_DTC" 3 "UNABLE_TO_TEST_DTC" ;
VAL_ 861 IBST_d005_ecuWdFltCntTstFls 0 "NOT_TESTED_DTC" 1 "PASSED_DTC" 2 "FAILED_DTC" 3 "UNABLE_TO_TEST_DTC" ;
VAL_ 861 IBST_d006_ecuWdScheduleTout 0 "NOT_TESTED_DTC" 1 "PASSED_DTC" 2 "FAILED_DTC" 3 "UNABLE_TO_TEST_DTC" ;
VAL_ 861 IBST_d007_ecuWdStarttestFls 0 "NOT_TESTED_DTC" 1 "PASSED_DTC" 2 "FAILED_DTC" 3 "UNABLE_TO_TEST_DTC" ;
VAL_ 861 IBST_d008_ecuWdStatusContErr 0 "NOT_TESTED_DTC" 1 "PASSED_DTC" 2 "FAILED_DTC" 3 "UNABLE_TO_TEST_DTC" ;
VAL_ 861 IBST_d009_netOvrvolt 0 "NOT_TESTED_DTC" 1 "PASSED_DTC" 2 "FAILED_DTC" 3 "UNABLE_TO_TEST_DTC" ;
VAL_ 861 IBST_d010_micSpiTout 0 "NOT_TESTED_DTC" 1 "PASSED_DTC" 2 "FAILED_DTC" 3 "UNABLE_TO_TEST_DTC" ;
VAL_ 861 IBST_d011_micSpiTransferErr 0 "NOT_TESTED_DTC" 1 "PASSED_DTC" 2 "FAILED_DTC" 3 "UNABLE_TO_TEST_DTC" ;
VAL_ 861 IBST_d012_netUndvolt 0 "NOT_TESTED_DTC" 1 "PASSED_DTC" 2 "FAILED_DTC" 3 "UNABLE_TO_TEST_DTC" ;
VAL_ 861 IBST_d013_xpassToutErr 0 "NOT_TESTED_DTC" 1 "PASSED_DTC" 2 "FAILED_DTC" 3 "UNABLE_TO_TEST_DTC" ;
VAL_ 861 IBST_d014_rpsOffsEeReadEmpty 0 "NOT_TESTED_DTC" 1 "PASSED_DTC" 2 "FAILED_DTC" 3 "UNABLE_TO_TEST_DTC" ;
VAL_ 861 IBST_d015_rtpEnaHigh 0 "NOT_TESTED_DTC" 1 "PASSED_DTC" 2 "FAILED_DTC" 3 "UNABLE_TO_TEST_DTC" ;
VAL_ 861 IBST_d016_xpassEchoCountErr 0 "NOT_TESTED_DTC" 1 "PASSED_DTC" 2 "FAILED_DTC" 3 "UNABLE_TO_TEST_DTC" ;
VAL_ 861 IBST_d017_preDriveChckFail 0 "NOT_TESTED_DTC" 1 "PASSED_DTC" 2 "FAILED_DTC" 3 "UNABLE_TO_TEST_DTC" ;
VAL_ 861 IBST_d018_ucSafetyFlt 0 "NOT_TESTED_DTC" 1 "PASSED_DTC" 2 "FAILED_DTC" 3 "UNABLE_TO_TEST_DTC" ;
VAL_ 861 IBST_d019_unsupportedHw 0 "NOT_TESTED_DTC" 1 "PASSED_DTC" 2 "FAILED_DTC" 3 "UNABLE_TO_TEST_DTC" ;
VAL_ 861 IBST_d020_voltPreRegModeFld 0 "NOT_TESTED_DTC" 1 "PASSED_DTC" 2 "FAILED_DTC" 3 "UNABLE_TO_TEST_DTC" ;
VAL_ 861 IBST_d021_ubbSupplyLine 0 "NOT_TESTED_DTC" 1 "PASSED_DTC" 2 "FAILED_DTC" 3 "UNABLE_TO_TEST_DTC" ;
VAL_ 861 IBST_d022_stmAswSysTout 0 "NOT_TESTED_DTC" 1 "PASSED_DTC" 2 "FAILED_DTC" 3 "UNABLE_TO_TEST_DTC" ;
VAL_ 861 IBST_d023_stackOvrUndFlow 0 "NOT_TESTED_DTC" 1 "PASSED_DTC" 2 "FAILED_DTC" 3 "UNABLE_TO_TEST_DTC" ;
VAL_ 861 IBST_d024_smmOneReqsInit 0 "NOT_TESTED_DTC" 1 "PASSED_DTC" 2 "FAILED_DTC" 3 "UNABLE_TO_TEST_DTC" ;
VAL_ 861 IBST_d025_ptsSupply 0 "NOT_TESTED_DTC" 1 "PASSED_DTC" 2 "FAILED_DTC" 3 "UNABLE_TO_TEST_DTC" ;
VAL_ 861 IBST_d026_ptsSupplyUndvolt 0 "NOT_TESTED_DTC" 1 "PASSED_DTC" 2 "FAILED_DTC" 3 "UNABLE_TO_TEST_DTC" ;
VAL_ 861 IBST_d027_tempB6Plaus 0 "NOT_TESTED_DTC" 1 "PASSED_DTC" 2 "FAILED_DTC" 3 "UNABLE_TO_TEST_DTC" ;
VAL_ 861 IBST_d028_ecuWdErrCntContErr 0 "NOT_TESTED_DTC" 1 "PASSED_DTC" 2 "FAILED_DTC" 3 "UNABLE_TO_TEST_DTC" ;
VAL_ 861 IBST_d029_bmcShortedGateTest 0 "NOT_TESTED_DTC" 1 "PASSED_DTC" 2 "FAILED_DTC" 3 "UNABLE_TO_TEST_DTC" ;
VAL_ 861 IBST_d030_controllerDevTooBig 0 "NOT_TESTED_DTC" 1 "PASSED_DTC" 2 "FAILED_DTC" 3 "UNABLE_TO_TEST_DTC" ;
VAL_ 861 IBST_d031_ibDtrFail 0 "NOT_TESTED_DTC" 1 "PASSED_DTC" 2 "FAILED_DTC" 3 "UNABLE_TO_TEST_DTC" ;
VAL_ 861 IBST_d032_oc6InitTestFail 0 "NOT_TESTED_DTC" 1 "PASSED_DTC" 2 "FAILED_DTC" 3 "UNABLE_TO_TEST_DTC" ;
VAL_ 861 IBST_d033_oc6Monitor 0 "NOT_TESTED_DTC" 1 "PASSED_DTC" 2 "FAILED_DTC" 3 "UNABLE_TO_TEST_DTC" ;
VAL_ 861 IBST_d034_motorOscillationDet 0 "NOT_TESTED_DTC" 1 "PASSED_DTC" 2 "FAILED_DTC" 3 "UNABLE_TO_TEST_DTC" ;
VAL_ 861 IBST_d035_rpsOffsEeReadFail 0 "NOT_TESTED_DTC" 1 "PASSED_DTC" 2 "FAILED_DTC" 3 "UNABLE_TO_TEST_DTC" ;
VAL_ 861 IBST_d036_sysErrHook 0 "NOT_TESTED_DTC" 1 "PASSED_DTC" 2 "FAILED_DTC" 3 "UNABLE_TO_TEST_DTC" ;
VAL_ 861 IBST_d037_calIdlePosNotPlaus 0 "NOT_TESTED_DTC" 1 "PASSED_DTC" 2 "FAILED_DTC" 3 "UNABLE_TO_TEST_DTC" ;
VAL_ 861 IBST_d038_boostSupUndrvolt 0 "NOT_TESTED_DTC" 1 "PASSED_DTC" 2 "FAILED_DTC" 3 "UNABLE_TO_TEST_DTC" ;
VAL_ 861 IBST_d039_calRoutineAbort 0 "NOT_TESTED_DTC" 1 "PASSED_DTC" 2 "FAILED_DTC" 3 "UNABLE_TO_TEST_DTC" ;
VAL_ 861 IBST_d040_bmcGateUndervoltPro 0 "NOT_TESTED_DTC" 1 "PASSED_DTC" 2 "FAILED_DTC" 3 "UNABLE_TO_TEST_DTC" ;
VAL_ 861 IBST_d041_hswInitPhseUndrvolt 0 "NOT_TESTED_DTC" 1 "PASSED_DTC" 2 "FAILED_DTC" 3 "UNABLE_TO_TEST_DTC" ;
VAL_ 861 IBST_d042_ltmWarnLevelReached 0 "NOT_TESTED_DTC" 1 "PASSED_DTC" 2 "FAILED_DTC" 3 "UNABLE_TO_TEST_DTC" ;
VAL_ 861 IBST_d043_rpsVctrLengthRelErr 0 "NOT_TESTED_DTC" 1 "PASSED_DTC" 2 "FAILED_DTC" 3 "UNABLE_TO_TEST_DTC" ;
VAL_ 861 IBST_d044_b6TempDegradeLevel1 0 "NOT_TESTED_DTC" 1 "PASSED_DTC" 2 "FAILED_DTC" 3 "UNABLE_TO_TEST_DTC" ;
VAL_ 861 IBST_d045_B6TempDegradeLevel2 0 "NOT_TESTED_DTC" 1 "PASSED_DTC" 2 "FAILED_DTC" 3 "UNABLE_TO_TEST_DTC" ;
VAL_ 861 IBST_d046_spiAnglOrRawNotUp 0 "NOT_TESTED_DTC" 1 "PASSED_DTC" 2 "FAILED_DTC" 3 "UNABLE_TO_TEST_DTC" ;
VAL_ 861 IBST_d047_dcomIboosterNotInit 0 "NOT_TESTED_DTC" 1 "PASSED_DTC" 2 "FAILED_DTC" 3 "UNABLE_TO_TEST_DTC" ;
VAL_ 861 IBST_d048_unintendMotorReturn 0 "NOT_TESTED_DTC" 1 "PASSED_DTC" 2 "FAILED_DTC" 3 "UNABLE_TO_TEST_DTC" ;
VAL_ 861 IBST_d049_cdmOvrvoltLevel1 0 "NOT_TESTED_DTC" 1 "PASSED_DTC" 2 "FAILED_DTC" 3 "UNABLE_TO_TEST_DTC" ;
VAL_ 861 IBST_d050_cdmUndrvoltLevel2 0 "NOT_TESTED_DTC" 1 "PASSED_DTC" 2 "FAILED_DTC" 3 "UNABLE_TO_TEST_DTC" ;
VAL_ 861 IBST_d051_cdmUndrvoltLevel1 0 "NOT_TESTED_DTC" 1 "PASSED_DTC" 2 "FAILED_DTC" 3 "UNABLE_TO_TEST_DTC" ;
VAL_ 861 IBST_d052_motTrvlRelReadFail 0 "NOT_TESTED_DTC" 1 "PASSED_DTC" 2 "FAILED_DTC" 3 "UNABLE_TO_TEST_DTC" ;
VAL_ 861 IBST_d053_tle5012UnexpReset 0 "NOT_TESTED_DTC" 1 "PASSED_DTC" 2 "FAILED_DTC" 3 "UNABLE_TO_TEST_DTC" ;
VAL_ 861 IBST_d054_bmsGateUndrvolt 0 "NOT_TESTED_DTC" 1 "PASSED_DTC" 2 "FAILED_DTC" 3 "UNABLE_TO_TEST_DTC" ;
VAL_ 861 IBST_d055_kl15HwPlausSw 0 "NOT_TESTED_DTC" 1 "PASSED_DTC" 2 "FAILED_DTC" 3 "UNABLE_TO_TEST_DTC" ;
VAL_ 861 IBST_d056_ibNotShutDownRight 0 "NOT_TESTED_DTC" 1 "PASSED_DTC" 2 "FAILED_DTC" 3 "UNABLE_TO_TEST_DTC" ;
VAL_ 861 IBST_d057_cdmHardUndrvolt 0 "NOT_TESTED_DTC" 1 "PASSED_DTC" 2 "FAILED_DTC" 3 "UNABLE_TO_TEST_DTC" ;
VAL_ 861 IBST_d058_cdmHardOvrvolt 0 "NOT_TESTED_DTC" 1 "PASSED_DTC" 2 "FAILED_DTC" 3 "UNABLE_TO_TEST_DTC" ;
VAL_ 861 IBST_d059_maxTrvlAdjstUpdFail 0 "NOT_TESTED_DTC" 1 "PASSED_DTC" 2 "FAILED_DTC" 3 "UNABLE_TO_TEST_DTC" ;
VAL_ 861 IBST_d060_ltmLimitReached 0 "NOT_TESTED_DTC" 1 "PASSED_DTC" 2 "FAILED_DTC" 3 "UNABLE_TO_TEST_DTC" ;
VAL_ 861 IBST_d061_dcomEcuDefect 0 "NOT_TESTED_DTC" 1 "PASSED_DTC" 2 "FAILED_DTC" 3 "UNABLE_TO_TEST_DTC" ;
VAL_ 861 IBST_d062_inputStroke1RngHigh 0 "NOT_TESTED_DTC" 1 "PASSED_DTC" 2 "FAILED_DTC" 3 "UNABLE_TO_TEST_DTC" ;
VAL_ 861 IBST_d063_inputStroke1RngLow 0 "NOT_TESTED_DTC" 1 "PASSED_DTC" 2 "FAILED_DTC" 3 "UNABLE_TO_TEST_DTC" ;
VAL_ 861 IBST_d064_inputStroke2RngHigh 0 "NOT_TESTED_DTC" 1 "PASSED_DTC" 2 "FAILED_DTC" 3 "UNABLE_TO_TEST_DTC" ;
VAL_ 861 IBST_d065_inputStroke2RngLow 0 "NOT_TESTED_DTC" 1 "PASSED_DTC" 2 "FAILED_DTC" 3 "UNABLE_TO_TEST_DTC" ;
VAL_ 861 IBST_d066_ibSupVoltDivDrift 0 "NOT_TESTED_DTC" 1 "PASSED_DTC" 2 "FAILED_DTC" 3 "UNABLE_TO_TEST_DTC" ;
VAL_ 861 IBST_d067_sOutRodToPressVal 0 "NOT_TESTED_DTC" 1 "PASSED_DTC" 2 "FAILED_DTC" 3 "UNABLE_TO_TEST_DTC" ;
VAL_ 861 IBST_d068_tle5012LifeCnt 0 "NOT_TESTED_DTC" 1 "PASSED_DTC" 2 "FAILED_DTC" 3 "UNABLE_TO_TEST_DTC" ;
VAL_ 861 IBST_d069_cdmExtendedUndrvolt 0 "NOT_TESTED_DTC" 1 "PASSED_DTC" 2 "FAILED_DTC" 3 "UNABLE_TO_TEST_DTC" ;
VAL_ 861 IBST_d070_cdmExtendedOvrvolt 0 "NOT_TESTED_DTC" 1 "PASSED_DTC" 2 "FAILED_DTC" 3 "UNABLE_TO_TEST_DTC" ;
VAL_ 861 IBST_d071_tempB6Ch1LineHigh 0 "NOT_TESTED_DTC" 1 "PASSED_DTC" 2 "FAILED_DTC" 3 "UNABLE_TO_TEST_DTC" ;
VAL_ 861 IBST_d072_tempB6Ch1LineLow 0 "NOT_TESTED_DTC" 1 "PASSED_DTC" 2 "FAILED_DTC" 3 "UNABLE_TO_TEST_DTC" ;
VAL_ 861 IBST_d073_tempB6Ch2LineHigh 0 "NOT_TESTED_DTC" 1 "PASSED_DTC" 2 "FAILED_DTC" 3 "UNABLE_TO_TEST_DTC" ;
VAL_ 861 IBST_d074_tempB6Ch2LineLow 0 "NOT_TESTED_DTC" 1 "PASSED_DTC" 2 "FAILED_DTC" 3 "UNABLE_TO_TEST_DTC" ;
VAL_ 861 IBST_d075_hevSwitchOffDcom 0 "NOT_TESTED_DTC" 1 "PASSED_DTC" 2 "FAILED_DTC" 3 "UNABLE_TO_TEST_DTC" ;
VAL_ 861 IBST_d076_tle5012VoltFail 0 "NOT_TESTED_DTC" 1 "PASSED_DTC" 2 "FAILED_DTC" 3 "UNABLE_TO_TEST_DTC" ;
VAL_ 861 IBST_d077_bcsFltCurrentHigh 0 "NOT_TESTED_DTC" 1 "PASSED_DTC" 2 "FAILED_DTC" 3 "UNABLE_TO_TEST_DTC" ;
VAL_ 861 IBST_d078_bcsFltCurrentLow 0 "NOT_TESTED_DTC" 1 "PASSED_DTC" 2 "FAILED_DTC" 3 "UNABLE_TO_TEST_DTC" ;
VAL_ 861 IBST_d079_ecuSupVoltDivDrift 0 "NOT_TESTED_DTC" 1 "PASSED_DTC" 2 "FAILED_DTC" 3 "UNABLE_TO_TEST_DTC" ;
VAL_ 861 IBST_d080_inputstroke1Grad 0 "NOT_TESTED_DTC" 1 "PASSED_DTC" 2 "FAILED_DTC" 3 "UNABLE_TO_TEST_DTC" ;
VAL_ 861 IBST_d081_pts1Err 0 "NOT_TESTED_DTC" 1 "PASSED_DTC" 2 "FAILED_DTC" 3 "UNABLE_TO_TEST_DTC" ;
VAL_ 861 IBST_d082_pts1LineGnd 0 "NOT_TESTED_DTC" 1 "PASSED_DTC" 2 "FAILED_DTC" 3 "UNABLE_TO_TEST_DTC" ;
VAL_ 861 IBST_d083_pts1LineHigh 0 "NOT_TESTED_DTC" 1 "PASSED_DTC" 2 "FAILED_DTC" 3 "UNABLE_TO_TEST_DTC" ;
VAL_ 861 IBST_d084_inputStroke2Grad 0 "NOT_TESTED_DTC" 1 "PASSED_DTC" 2 "FAILED_DTC" 3 "UNABLE_TO_TEST_DTC" ;
VAL_ 861 IBST_d085_pts2Err 0 "NOT_TESTED_DTC" 1 "PASSED_DTC" 2 "FAILED_DTC" 3 "UNABLE_TO_TEST_DTC" ;
VAL_ 861 IBST_d086_pts2LineGnd 0 "NOT_TESTED_DTC" 1 "PASSED_DTC" 2 "FAILED_DTC" 3 "UNABLE_TO_TEST_DTC" ;
VAL_ 861 IBST_d087_pts2LineHigh 0 "NOT_TESTED_DTC" 1 "PASSED_DTC" 2 "FAILED_DTC" 3 "UNABLE_TO_TEST_DTC" ;
VAL_ 861 IBST_d088_faildevInputStroke 0 "NOT_TESTED_DTC" 1 "PASSED_DTC" 2 "FAILED_DTC" 3 "UNABLE_TO_TEST_DTC" ;
VAL_ 861 IBST_d089_ptsOffsTooHigh 0 "NOT_TESTED_DTC" 1 "PASSED_DTC" 2 "FAILED_DTC" 3 "UNABLE_TO_TEST_DTC" ;
VAL_ 861 IBST_d090_pbistErr 0 "NOT_TESTED_DTC" 1 "PASSED_DTC" 2 "FAILED_DTC" 3 "UNABLE_TO_TEST_DTC" ;
VAL_ 861 IBST_d091_ramInitErr 0 "NOT_TESTED_DTC" 1 "PASSED_DTC" 2 "FAILED_DTC" 3 "UNABLE_TO_TEST_DTC" ;
VAL_ 861 IBST_d092_ramsinlgeFlt 0 "NOT_TESTED_DTC" 1 "PASSED_DTC" 2 "FAILED_DTC" 3 "UNABLE_TO_TEST_DTC" ;
VAL_ 861 IBST_d093_bertFlt 0 "NOT_TESTED_DTC" 1 "PASSED_DTC" 2 "FAILED_DTC" 3 "UNABLE_TO_TEST_DTC" ;
VAL_ 861 IBST_d094_CalDataNotPlaus 0 "NOT_TESTED_DTC" 1 "PASSED_DTC" 2 "FAILED_DTC" 3 "UNABLE_TO_TEST_DTC" ;
VAL_ 861 IBST_d095_canEHwError 0 "NOT_TESTED_DTC" 1 "PASSED_DTC" 2 "FAILED_DTC" 3 "UNABLE_TO_TEST_DTC" ;
VAL_ 861 IBST_d096_canETout 0 "NOT_TESTED_DTC" 1 "PASSED_DTC" 2 "FAILED_DTC" 3 "UNABLE_TO_TEST_DTC" ;
VAL_ 861 IBST_d097_cpuException 0 "NOT_TESTED_DTC" 1 "PASSED_DTC" 2 "FAILED_DTC" 3 "UNABLE_TO_TEST_DTC" ;
VAL_ 861 IBST_d098_ecuBandGap 0 "NOT_TESTED_DTC" 1 "PASSED_DTC" 2 "FAILED_DTC" 3 "UNABLE_TO_TEST_DTC" ;
VAL_ 861 IBST_d099_ecuBmsOnWhileWdTout 0 "NOT_TESTED_DTC" 1 "PASSED_DTC" 2 "FAILED_DTC" 3 "UNABLE_TO_TEST_DTC" ;
VAL_ 861 IBST_d100_ecuErrpinCntTstFls 0 "NOT_TESTED_DTC" 1 "PASSED_DTC" 2 "FAILED_DTC" 3 "UNABLE_TO_TEST_DTC" ;
VAL_ 861 IBST_d101_ecuHetException 0 "NOT_TESTED_DTC" 1 "PASSED_DTC" 2 "FAILED_DTC" 3 "UNABLE_TO_TEST_DTC" ;
VAL_ 861 IBST_d102_ecuHetTuAddErr 0 "NOT_TESTED_DTC" 1 "PASSED_DTC" 2 "FAILED_DTC" 3 "UNABLE_TO_TEST_DTC" ;
VAL_ 861 IBST_d103_ecuHetTuBusErr 0 "NOT_TESTED_DTC" 1 "PASSED_DTC" 2 "FAILED_DTC" 3 "UNABLE_TO_TEST_DTC" ;
VAL_ 861 IBST_d104_ecuHetTuBusyErr 0 "NOT_TESTED_DTC" 1 "PASSED_DTC" 2 "FAILED_DTC" 3 "UNABLE_TO_TEST_DTC" ;
VAL_ 861 IBST_d105_ecuHetTuException 0 "NOT_TESTED_DTC" 1 "PASSED_DTC" 2 "FAILED_DTC" 3 "UNABLE_TO_TEST_DTC" ;
VAL_ 861 IBST_d106_ecuTaskMissing 0 "NOT_TESTED_DTC" 1 "PASSED_DTC" 2 "FAILED_DTC" 3 "UNABLE_TO_TEST_DTC" ;
VAL_ 861 IBST_d107_hetRefError 0 "NOT_TESTED_DTC" 1 "PASSED_DTC" 2 "FAILED_DTC" 3 "UNABLE_TO_TEST_DTC" ;
VAL_ 861 IBST_d108_micInitSpiTstFld 0 "NOT_TESTED_DTC" 1 "PASSED_DTC" 2 "FAILED_DTC" 3 "UNABLE_TO_TEST_DTC" ;
VAL_ 861 IBST_d109_micInitSpiTransfErr 0 "NOT_TESTED_DTC" 1 "PASSED_DTC" 2 "FAILED_DTC" 3 "UNABLE_TO_TEST_DTC" ;
VAL_ 861 IBST_d110_micIntMonGenBitMon 0 "NOT_TESTED_DTC" 1 "PASSED_DTC" 2 "FAILED_DTC" 3 "UNABLE_TO_TEST_DTC" ;
VAL_ 861 IBST_d111_micIntVoltMonFld 0 "NOT_TESTED_DTC" 1 "PASSED_DTC" 2 "FAILED_DTC" 3 "UNABLE_TO_TEST_DTC" ;
VAL_ 861 IBST_d112_motPosTrvlReadEmpty 0 "NOT_TESTED_DTC" 1 "PASSED_DTC" 2 "FAILED_DTC" 3 "UNABLE_TO_TEST_DTC" ;
VAL_ 861 IBST_d113_motAngBoundReadEmpt 0 "NOT_TESTED_DTC" 1 "PASSED_DTC" 2 "FAILED_DTC" 3 "UNABLE_TO_TEST_DTC" ;
VAL_ 861 IBST_d114_motShaftShiftDetect 0 "NOT_TESTED_DTC" 1 "PASSED_DTC" 2 "FAILED_DTC" 3 "UNABLE_TO_TEST_DTC" ;
VAL_ 861 IBST_d115_osErrHook 0 "NOT_TESTED_DTC" 1 "PASSED_DTC" 2 "FAILED_DTC" 3 "UNABLE_TO_TEST_DTC" ;
VAL_ 861 IBST_d116_pdurEInitFail 0 "NOT_TESTED_DTC" 1 "PASSED_DTC" 2 "FAILED_DTC" 3 "UNABLE_TO_TEST_DTC" ;
VAL_ 861 IBST_d117_pdurEPduInstLost 0 "NOT_TESTED_DTC" 1 "PASSED_DTC" 2 "FAILED_DTC" 3 "UNABLE_TO_TEST_DTC" ;
VAL_ 861 IBST_d118_pts1OffsEeReadEmpty 0 "NOT_TESTED_DTC" 1 "PASSED_DTC" 2 "FAILED_DTC" 3 "UNABLE_TO_TEST_DTC" ;
VAL_ 861 IBST_d119_pts2OffsEeReadEmpty 0 "NOT_TESTED_DTC" 1 "PASSED_DTC" 2 "FAILED_DTC" 3 "UNABLE_TO_TEST_DTC" ;
VAL_ 861 IBST_d120_rpsOffsXEeReadFail 0 "NOT_TESTED_DTC" 1 "PASSED_DTC" 2 "FAILED_DTC" 3 "UNABLE_TO_TEST_DTC" ;
VAL_ 861 IBST_d121_rpsOffsYEeReadFail 0 "NOT_TESTED_DTC" 1 "PASSED_DTC" 2 "FAILED_DTC" 3 "UNABLE_TO_TEST_DTC" ;
VAL_ 861 IBST_d122_rpsSynchEeReadFail 0 "NOT_TESTED_DTC" 1 "PASSED_DTC" 2 "FAILED_DTC" 3 "UNABLE_TO_TEST_DTC" ;
VAL_ 861 IBST_d123_rpsAnglRecalcErr 0 "NOT_TESTED_DTC" 1 "PASSED_DTC" 2 "FAILED_DTC" 3 "UNABLE_TO_TEST_DTC" ;
VAL_ 861 IBST_d124_motTrvlRelWriteFail 0 "NOT_TESTED_DTC" 1 "PASSED_DTC" 2 "FAILED_DTC" 3 "UNABLE_TO_TEST_DTC" ;
VAL_ 861 IBST_d125_motTrvlRelReadEmpty 0 "NOT_TESTED_DTC" 1 "PASSED_DTC" 2 "FAILED_DTC" 3 "UNABLE_TO_TEST_DTC" ;
VAL_ 861 IBST_d126_ptsEeReadEmpty 0 "NOT_TESTED_DTC" 1 "PASSED_DTC" 2 "FAILED_DTC" 3 "UNABLE_TO_TEST_DTC" ;
VAL_ 861 IBST_d127_ecuAdcConversionErr 0 "NOT_TESTED_DTC" 1 "PASSED_DTC" 2 "FAILED_DTC" 3 "UNABLE_TO_TEST_DTC" ;
VAL_ 861 IBST_d128_ecuAdcSelftestErr 0 "NOT_TESTED_DTC" 1 "PASSED_DTC" 2 "FAILED_DTC" 3 "UNABLE_TO_TEST_DTC" ;
VAL_ 861 IBST_d129_ccmFlt 0 "NOT_TESTED_DTC" 1 "PASSED_DTC" 2 "FAILED_DTC" 3 "UNABLE_TO_TEST_DTC" ;
VAL_ 861 IBST_d130_ecuRomCheck 0 "NOT_TESTED_DTC" 1 "PASSED_DTC" 2 "FAILED_DTC" 3 "UNABLE_TO_TEST_DTC" ;
VAL_ 861 IBST_d131_esmNmiFlt 0 "NOT_TESTED_DTC" 1 "PASSED_DTC" 2 "FAILED_DTC" 3 "UNABLE_TO_TEST_DTC" ;
VAL_ 861 IBST_d132_esmSafetyFlt 0 "NOT_TESTED_DTC" 1 "PASSED_DTC" 2 "FAILED_DTC" 3 "UNABLE_TO_TEST_DTC" ;
VAL_ 861 IBST_d133_motPosTrvlReadFail 0 "NOT_TESTED_DTC" 1 "PASSED_DTC" 2 "FAILED_DTC" 3 "UNABLE_TO_TEST_DTC" ;
VAL_ 861 IBST_d134_motPosTrvlWriteFail 0 "NOT_TESTED_DTC" 1 "PASSED_DTC" 2 "FAILED_DTC" 3 "UNABLE_TO_TEST_DTC" ;
VAL_ 861 IBST_d135_motAnglBndReadErr 0 "NOT_TESTED_DTC" 1 "PASSED_DTC" 2 "FAILED_DTC" 3 "UNABLE_TO_TEST_DTC" ;
VAL_ 861 IBST_d136_motAnglBndWriteErr 0 "NOT_TESTED_DTC" 1 "PASSED_DTC" 2 "FAILED_DTC" 3 "UNABLE_TO_TEST_DTC" ;
VAL_ 861 IBST_d137_motAnglGradTooLarge 0 "NOT_TESTED_DTC" 1 "PASSED_DTC" 2 "FAILED_DTC" 3 "UNABLE_TO_TEST_DTC" ;
VAL_ 861 IBST_d138_pdmCustomerIdMis 0 "NOT_TESTED_DTC" 1 "PASSED_DTC" 2 "FAILED_DTC" 3 "UNABLE_TO_TEST_DTC" ;
VAL_ 861 IBST_d139_pdmDtFormatMis 0 "NOT_TESTED_DTC" 1 "PASSED_DTC" 2 "FAILED_DTC" 3 "UNABLE_TO_TEST_DTC" ;
VAL_ 861 IBST_d140_pdmOutOfMemory 0 "NOT_TESTED_DTC" 1 "PASSED_DTC" 2 "FAILED_DTC" 3 "UNABLE_TO_TEST_DTC" ;
VAL_ 861 IBST_d141_pdmFieldSizeMis 0 "NOT_TESTED_DTC" 1 "PASSED_DTC" 2 "FAILED_DTC" 3 "UNABLE_TO_TEST_DTC" ;
VAL_ 861 IBST_d142_pdmHwAcsErr 0 "NOT_TESTED_DTC" 1 "PASSED_DTC" 2 "FAILED_DTC" 3 "UNABLE_TO_TEST_DTC" ;
VAL_ 861 IBST_d143_pdmInternalHWErr 0 "NOT_TESTED_DTC" 1 "PASSED_DTC" 2 "FAILED_DTC" 3 "UNABLE_TO_TEST_DTC" ;
VAL_ 861 IBST_d144_ptsCalHysWritFail 0 "NOT_TESTED_DTC" 1 "PASSED_DTC" 2 "FAILED_DTC" 3 "UNABLE_TO_TEST_DTC" ;
VAL_ 861 IBST_d145_ptsCalValuesChkFail 0 "NOT_TESTED_DTC" 1 "PASSED_DTC" 2 "FAILED_DTC" 3 "UNABLE_TO_TEST_DTC" ;
VAL_ 861 IBST_d146_pts1CalEeReadFail 0 "NOT_TESTED_DTC" 1 "PASSED_DTC" 2 "FAILED_DTC" 3 "UNABLE_TO_TEST_DTC" ;
VAL_ 861 IBST_d147_pts1CalEeWriteFail 0 "NOT_TESTED_DTC" 1 "PASSED_DTC" 2 "FAILED_DTC" 3 "UNABLE_TO_TEST_DTC" ;
VAL_ 861 IBST_d148_rpsFailCompErr 0 "NOT_TESTED_DTC" 1 "PASSED_DTC" 2 "FAILED_DTC" 3 "UNABLE_TO_TEST_DTC" ;
VAL_ 861 IBST_d149_pts1OffsEeWriteFail 0 "NOT_TESTED_DTC" 1 "PASSED_DTC" 2 "FAILED_DTC" 3 "UNABLE_TO_TEST_DTC" ;
VAL_ 861 IBST_d150_pts2CalEeReadFail 0 "NOT_TESTED_DTC" 1 "PASSED_DTC" 2 "FAILED_DTC" 3 "UNABLE_TO_TEST_DTC" ;
VAL_ 861 IBST_d151_pts2CalEeWriteFail 0 "NOT_TESTED_DTC" 1 "PASSED_DTC" 2 "FAILED_DTC" 3 "UNABLE_TO_TEST_DTC" ;
VAL_ 861 IBST_d152_pts2OffsEeReadFail 0 "NOT_TESTED_DTC" 1 "PASSED_DTC" 2 "FAILED_DTC" 3 "UNABLE_TO_TEST_DTC" ;
VAL_ 861 IBST_d153_pts2OffsEeWriteFail 0 "NOT_TESTED_DTC" 1 "PASSED_DTC" 2 "FAILED_DTC" 3 "UNABLE_TO_TEST_DTC" ;
VAL_ 861 IBST_d154_rpsOffsXEeReadEmpty 0 "NOT_TESTED_DTC" 1 "PASSED_DTC" 2 "FAILED_DTC" 3 "UNABLE_TO_TEST_DTC" ;
VAL_ 861 IBST_d155_rpsOffsXEeWriteFail 0 "NOT_TESTED_DTC" 1 "PASSED_DTC" 2 "FAILED_DTC" 3 "UNABLE_TO_TEST_DTC" ;
VAL_ 861 IBST_d156_rpsOffsYEeReadEmpty 0 "NOT_TESTED_DTC" 1 "PASSED_DTC" 2 "FAILED_DTC" 3 "UNABLE_TO_TEST_DTC" ;
VAL_ 861 IBST_d157_rpsOffsYEeWriteFail 0 "NOT_TESTED_DTC" 1 "PASSED_DTC" 2 "FAILED_DTC" 3 "UNABLE_TO_TEST_DTC" ;
VAL_ 861 IBST_d158_rpsSynchEeReadEmpty 0 "NOT_TESTED_DTC" 1 "PASSED_DTC" 2 "FAILED_DTC" 3 "UNABLE_TO_TEST_DTC" ;
VAL_ 861 IBST_d159_rpsSynchEeWriteFail 0 "NOT_TESTED_DTC" 1 "PASSED_DTC" 2 "FAILED_DTC" 3 "UNABLE_TO_TEST_DTC" ;
VAL_ 861 IBST_d160_assertionFail 0 "NOT_TESTED_DTC" 1 "PASSED_DTC" 2 "FAILED_DTC" 3 "UNABLE_TO_TEST_DTC" ;
VAL_ 861 IBST_d161_comsclBrkPrsPduLen 0 "NOT_TESTED_DTC" 1 "PASSED_DTC" 2 "FAILED_DTC" 3 "UNABLE_TO_TEST_DTC" ;
VAL_ 861 IBST_d162_comsclBrkPrsPduTout 0 "NOT_TESTED_DTC" 1 "PASSED_DTC" 2 "FAILED_DTC" 3 "UNABLE_TO_TEST_DTC" ;
VAL_ 861 IBST_d163_comsclEspIb1CntErr 0 "NOT_TESTED_DTC" 1 "PASSED_DTC" 2 "FAILED_DTC" 3 "UNABLE_TO_TEST_DTC" ;
VAL_ 861 IBST_d164_comsclEspIb1CsErr 0 "NOT_TESTED_DTC" 1 "PASSED_DTC" 2 "FAILED_DTC" 3 "UNABLE_TO_TEST_DTC" ;
VAL_ 861 IBST_d165_comsclEspIb1DlcErr 0 "NOT_TESTED_DTC" 1 "PASSED_DTC" 2 "FAILED_DTC" 3 "UNABLE_TO_TEST_DTC" ;
VAL_ 861 IBST_d166_comsclEspIb1Tout 0 "NOT_TESTED_DTC" 1 "PASSED_DTC" 2 "FAILED_DTC" 3 "UNABLE_TO_TEST_DTC" ;
VAL_ 861 IBST_d167_comsclEspIb2CntErr 0 "NOT_TESTED_DTC" 1 "PASSED_DTC" 2 "FAILED_DTC" 3 "UNABLE_TO_TEST_DTC" ;
VAL_ 861 IBST_d168_comsclEspIb2CsErr 0 "NOT_TESTED_DTC" 1 "PASSED_DTC" 2 "FAILED_DTC" 3 "UNABLE_TO_TEST_DTC" ;
VAL_ 861 IBST_d169_comsclEspIb2DlcErr 0 "NOT_TESTED_DTC" 1 "PASSED_DTC" 2 "FAILED_DTC" 3 "UNABLE_TO_TEST_DTC" ;
VAL_ 861 IBST_d170_comsclEspIb2Tout 0 "NOT_TESTED_DTC" 1 "PASSED_DTC" 2 "FAILED_DTC" 3 "UNABLE_TO_TEST_DTC" ;
VAL_ 861 IBST_d171_comsclEspIb3CntErr 0 "NOT_TESTED_DTC" 1 "PASSED_DTC" 2 "FAILED_DTC" 3 "UNABLE_TO_TEST_DTC" ;
VAL_ 861 IBST_d172_comsclEspIb3CsErr 0 "NOT_TESTED_DTC" 1 "PASSED_DTC" 2 "FAILED_DTC" 3 "UNABLE_TO_TEST_DTC" ;
VAL_ 861 IBST_d173_comsclEspIb3DlcErr 0 "NOT_TESTED_DTC" 1 "PASSED_DTC" 2 "FAILED_DTC" 3 "UNABLE_TO_TEST_DTC" ;
VAL_ 861 IBST_d174_comsclEspIb3Tout 0 "NOT_TESTED_DTC" 1 "PASSED_DTC" 2 "FAILED_DTC" 3 "UNABLE_TO_TEST_DTC" ;
VAL_ 861 IBST_d175_comsclGtwEsp1CntErr 0 "NOT_TESTED_DTC" 1 "PASSED_DTC" 2 "FAILED_DTC" 3 "UNABLE_TO_TEST_DTC" ;
VAL_ 861 IBST_d176_comsclGtwEsp1CsErr 0 "NOT_TESTED_DTC" 1 "PASSED_DTC" 2 "FAILED_DTC" 3 "UNABLE_TO_TEST_DTC" ;
VAL_ 861 IBST_d177_comsclGtwEsp1Corrpt 0 "NOT_TESTED_DTC" 1 "PASSED_DTC" 2 "FAILED_DTC" 3 "UNABLE_TO_TEST_DTC" ;
VAL_ 861 IBST_d178_comsclGtwEsp1Tout 0 "NOT_TESTED_DTC" 1 "PASSED_DTC" 2 "FAILED_DTC" 3 "UNABLE_TO_TEST_DTC" ;
VAL_ 861 IBST_d179_dcomSmrtActuNotInit 0 "NOT_TESTED_DTC" 1 "PASSED_DTC" 2 "FAILED_DTC" 3 "UNABLE_TO_TEST_DTC" ;
VAL_ 861 IBST_d180_rpsLengthAbsolHigh 0 "NOT_TESTED_DTC" 1 "PASSED_DTC" 2 "FAILED_DTC" 3 "UNABLE_TO_TEST_DTC" ;
VAL_ 861 IBST_d181_rpsLengthAbsolLow 0 "NOT_TESTED_DTC" 1 "PASSED_DTC" 2 "FAILED_DTC" 3 "UNABLE_TO_TEST_DTC" ;
VAL_ 861 IBST_d182_shutDownEeReadFail 0 "NOT_TESTED_DTC" 1 "PASSED_DTC" 2 "FAILED_DTC" 3 "UNABLE_TO_TEST_DTC" ;
VAL_ 861 IBST_d183_shutDownEeWriteFail 0 "NOT_TESTED_DTC" 1 "PASSED_DTC" 2 "FAILED_DTC" 3 "UNABLE_TO_TEST_DTC" ;
VAL_ 861 IBST_d184_maxTrvlAdjstReadErr 0 "NOT_TESTED_DTC" 1 "PASSED_DTC" 2 "FAILED_DTC" 3 "UNABLE_TO_TEST_DTC" ;
VAL_ 861 IBST_d185_psOffsMcEeReadFail 0 "NOT_TESTED_DTC" 1 "PASSED_DTC" 2 "FAILED_DTC" 3 "UNABLE_TO_TEST_DTC" ;
VAL_ 861 IBST_d186_psOffsMcEeWriteFail 0 "NOT_TESTED_DTC" 1 "PASSED_DTC" 2 "FAILED_DTC" 3 "UNABLE_TO_TEST_DTC" ;
VAL_ 861 IBST_d187_ltmSelfProtDeact 0 "NOT_TESTED_DTC" 1 "PASSED_DTC" 2 "FAILED_DTC" 3 "UNABLE_TO_TEST_DTC" ;
VAL_ 861 IBST_d188_pts1OffsEeReadFail 0 "NOT_TESTED_DTC" 1 "PASSED_DTC" 2 "FAILED_DTC" 3 "UNABLE_TO_TEST_DTC" ;
VAL_ 861 IBST_d189_diffStrokeRange 0 "NOT_TESTED_DTC" 1 "PASSED_DTC" 2 "FAILED_DTC" 3 "UNABLE_TO_TEST_DTC" ;
VAL_ 861 IBST_d190_notProgVin 0 "NOT_TESTED_DTC" 1 "PASSED_DTC" 2 "FAILED_DTC" 3 "UNABLE_TO_TEST_DTC" ;
VAL_ 861 IBST_d191_plausVin 0 "NOT_TESTED_DTC" 1 "PASSED_DTC" 2 "FAILED_DTC" 3 "UNABLE_TO_TEST_DTC" ;
VAL_ 861 IBST_d192_dlCorCSumVin 0 "NOT_TESTED_DTC" 1 "PASSED_DTC" 2 "FAILED_DTC" 3 "UNABLE_TO_TEST_DTC" ;
VAL_ 861 IBST_d193_ToutVin 0 "NOT_TESTED_DTC" 1 "PASSED_DTC" 2 "FAILED_DTC" 3 "UNABLE_TO_TEST_DTC" ;
VAL_ 861 IBST_d194_ecuEnableB6Fail 0 "NOT_TESTED_DTC" 1 "PASSED_DTC" 2 "FAILED_DTC" 3 "UNABLE_TO_TEST_DTC" ;
VAL_ 861 IBST_d195_ecuIbEnContErr 0 "NOT_TESTED_DTC" 1 "PASSED_DTC" 2 "FAILED_DTC" 3 "UNABLE_TO_TEST_DTC" ;
VAL_ 861 IBST_d196_sclEspIb1pEstMax 0 "NOT_TESTED_DTC" 1 "PASSED_DTC" 2 "FAILED_DTC" 3 "UNABLE_TO_TEST_DTC" ;
VAL_ 861 IBST_d197_sclEspIb1VehSpd 0 "NOT_TESTED_DTC" 1 "PASSED_DTC" 2 "FAILED_DTC" 3 "UNABLE_TO_TEST_DTC" ;
VAL_ 861 IBST_d198_sclEspIb2pLimExt 0 "NOT_TESTED_DTC" 1 "PASSED_DTC" 2 "FAILED_DTC" 3 "UNABLE_TO_TEST_DTC" ;
VAL_ 861 IBST_d199_sclEspIb2qTarExt 0 "NOT_TESTED_DTC" 1 "PASSED_DTC" 2 "FAILED_DTC" 3 "UNABLE_TO_TEST_DTC" ;
VAL_ 861 IBST_d200_sclEspIb3pFBlend 0 "NOT_TESTED_DTC" 1 "PASSED_DTC" 2 "FAILED_DTC" 3 "UNABLE_TO_TEST_DTC" ;
VAL_ 861 IBST_d201_sclEspIb3pMc1 0 "NOT_TESTED_DTC" 1 "PASSED_DTC" 2 "FAILED_DTC" 3 "UNABLE_TO_TEST_DTC" ;
VAL_ 861 IBST_d202_sclEspIb3pTarDriver 0 "NOT_TESTED_DTC" 1 "PASSED_DTC" 2 "FAILED_DTC" 3 "UNABLE_TO_TEST_DTC" ;
VAL_ 861 IBST_d203_netBusOffNet0 0 "NOT_TESTED_DTC" 1 "PASSED_DTC" 2 "FAILED_DTC" 3 "UNABLE_TO_TEST_DTC" ;
VAL_ 861 IBST_d204_netErrPassivNet0 0 "NOT_TESTED_DTC" 1 "PASSED_DTC" 2 "FAILED_DTC" 3 "UNABLE_TO_TEST_DTC" ;
VAL_ 861 IBST_d205_netBusOffNet1 0 "NOT_TESTED_DTC" 1 "PASSED_DTC" 2 "FAILED_DTC" 3 "UNABLE_TO_TEST_DTC" ;
VAL_ 861 IBST_d206_netErrPassivNet1 0 "NOT_TESTED_DTC" 1 "PASSED_DTC" 2 "FAILED_DTC" 3 "UNABLE_TO_TEST_DTC" ;
VAL_ 861 IBST_d207_maxStrokeReached 0 "NOT_TESTED_DTC" 1 "PASSED_DTC" 2 "FAILED_DTC" 3 "UNABLE_TO_TEST_DTC" ;
VAL_ 861 IBST_d208_sysSwClockMismatch 0 "NOT_TESTED_DTC" 1 "PASSED_DTC" 2 "FAILED_DTC" 3 "UNABLE_TO_TEST_DTC" ;
VAL_ 861 IBST_d209_comsclGtwOdoCorrpt 0 "NOT_TESTED_DTC" 1 "PASSED_DTC" 2 "FAILED_DTC" 3 "UNABLE_TO_TEST_DTC" ;
VAL_ 861 IBST_d210_comsclGtwStatCorrpt 0 "NOT_TESTED_DTC" 1 "PASSED_DTC" 2 "FAILED_DTC" 3 "UNABLE_TO_TEST_DTC" ;
VAL_ 861 IBST_d211_comsclEpbStatCorrpt 0 "NOT_TESTED_DTC" 1 "PASSED_DTC" 2 "FAILED_DTC" 3 "UNABLE_TO_TEST_DTC" ;
VAL_ 861 IBST_d212_comsclGtwOdoTout 0 "NOT_TESTED_DTC" 1 "PASSED_DTC" 2 "FAILED_DTC" 3 "UNABLE_TO_TEST_DTC" ;
VAL_ 861 IBST_d213_comsclGtwStatTout 0 "NOT_TESTED_DTC" 1 "PASSED_DTC" 2 "FAILED_DTC" 3 "UNABLE_TO_TEST_DTC" ;
VAL_ 861 IBST_d214_comsclEpbStatTout 0 "NOT_TESTED_DTC" 1 "PASSED_DTC" 2 "FAILED_DTC" 3 "UNABLE_TO_TEST_DTC" ;
VAL_ 861 IBST_d215_comSclEpbStatCsErr 0 "NOT_TESTED_DTC" 1 "PASSED_DTC" 2 "FAILED_DTC" 3 "UNABLE_TO_TEST_DTC" ;
VAL_ 861 IBST_d216_comSclEpbStatCntFlt 0 "NOT_TESTED_DTC" 1 "PASSED_DTC" 2 "FAILED_DTC" 3 "UNABLE_TO_TEST_DTC" ;
VAL_ 861 IBST_d217_comSclDiTrq1Tout 0 "NOT_TESTED_DTC" 1 "PASSED_DTC" 2 "FAILED_DTC" 3 "UNABLE_TO_TEST_DTC" ;
VAL_ 861 IBST_d218_comSclDiTrq1Corrpt 0 "NOT_TESTED_DTC" 1 "PASSED_DTC" 2 "FAILED_DTC" 3 "UNABLE_TO_TEST_DTC" ;
VAL_ 861 IBST_d219_comSclDiTrq1CsErr 0 "NOT_TESTED_DTC" 1 "PASSED_DTC" 2 "FAILED_DTC" 3 "UNABLE_TO_TEST_DTC" ;
VAL_ 861 IBST_d220_comSclDiTrq1CntFlt 0 "NOT_TESTED_DTC" 1 "PASSED_DTC" 2 "FAILED_DTC" 3 "UNABLE_TO_TEST_DTC" ;
VAL_ 813 IBST_infoIndex 0 "DEPRECATED_0" 1 "DEPRECATED_1" 2 "DEPRECATED_2" 3 "DEPRECATED_3" 4 "DEPRECATED_4" 5 "DEPRECATED_5" 6 "DEPRECATED_6" 7 "DEPRECATED_7" 8 "DEPRECATED_8" 9 "DEPRECATED_9" 10 "BUILD_HWID_COMPONENTID" 11 "PCBAID_ASSYID_USAGEID" 13 "APP_CRC" 14 "BOOTLOADER_SVN" 15 "BOOTLOADER_CRC" 16 "SUBCOMPONENT" 17 "APP_GITHASH" 18 "BOOTLOADER_GITHASH" 19 "VERSION_DEPRECATED" 20 "UDS_PROTOCOL_BOOTCRC" 22 "VARIANT_CRC" 255 "END" ;
VAL_ 925 IBST_brakeInputStroke 1022 "NOT_VALID" 1023 "SNA" ;
VAL_ 925 IBST_iBoosterStatus 0 "NOT_INITIALIZED_OR_SUP" 1 "FAILURE" 2 "DIAGNOSIS" 3 "MAX_STROKE" 4 "STANDALONE" 5 "REDUCED" 6 "POST_RUN_REDUCED" 7 "READY" ;
